VERSION ""

NS_ :

BS_:

BU_: BMU ECU LOGGER

BO_ 2284093440 BMU_TransmitVoltage_N_0_P_0: 8 BMU
 SG_ BMU_M00_V00 : 0|16@1+ (1,0) [0|65535] "mV" LOGGER
 SG_ BMU_M00_V01 : 16|16@1+ (1,0) [0|65535] "mV" LOGGER
 SG_ BMU_M00_V02 : 32|16@1+ (1,0) [0|65535] "mV" LOGGER
 SG_ BMU_M00_VAge0 : 48|16@1+ (1,0) [0|65535] "ms" LOGGER

BO_ 2284093441 BMU_TransmitVoltage_N_0_P_1: 8 BMU
 SG_ BMU_M00_V03 : 0|16@1+ (1,0) [0|65535] "mV" LOGGER
 SG_ BMU_M00_V04 : 16|16@1+ (1,0) [0|65535] "mV" LOGGER
 SG_ BMU_M00_V05 : 32|16@1+ (1,0) [0|65535] "mV" LOGGER
 SG_ BMU_M00_VAge1 : 48|16@1+ (1,0) [0|65535] "ms" LOGGER

BO_ 2284093442 BMU_TransmitVoltage_N_0_P_2: 8 BMU
 SG_ BMU_M00_V06 : 0|16@1+ (1,0) [0|65535] "mV" LOGGER
 SG_ BMU_M00_V07 : 16|16@1+ (1,0) [0|65535] "mV" LOGGER
 SG_ BMU_M00_V08 : 32|16@1+ (1,0) [0|65535] "mV" LOGGER
 SG_ BMU_M00_VAge2 : 48|16@1+ (1,0) [0|65535] "ms" LOGGER

BO_ 2284093443 BMU_TransmitVoltage_N_0_P_3: 8 BMU
 SG_ BMU_M00_V09 : 0|16@1+ (1,0) [0|65535] "mV" LOGGER
 SG_ BMU_M00_V10 : 16|16@1+ (1,0) [0|65535] "mV" LOGGER
 SG_ BMU_M00_V11 : 32|16@1+ (1,0) [0|65535] "mV" LOGGER
 SG_ BMU_M00_VAge3 : 48|16@1+ (1,0) [0|65535] "ms" LOGGER

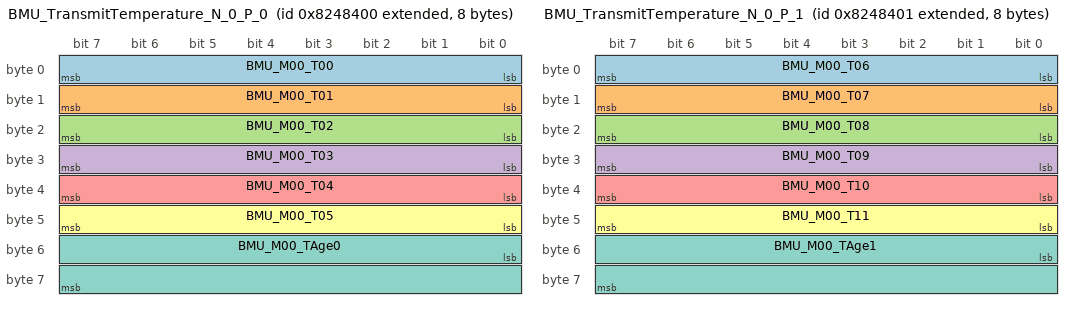
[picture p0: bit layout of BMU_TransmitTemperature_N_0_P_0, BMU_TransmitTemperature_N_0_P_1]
BO_ 2284094464 BMU_TransmitTemperature_N_0_P_0: 8 BMU
 SG_ BMU_M00_T00 : 0|8@1+ (1,0) [0|255] "degC" ECU,LOGGER
 SG_ BMU_M00_T01 : 8|8@1+ (1,0) [0|255] "degC" ECU,LOGGER
 SG_ BMU_M00_T02 : 16|8@1+ (1,0) [0|255] "degC" ECU,LOGGER
 SG_ BMU_M00_T03 : 24|8@1+ (1,0) [0|255] "degC" ECU,LOGGER
 SG_ BMU_M00_T04 : 32|8@1+ (1,0) [0|255] "degC" ECU,LOGGER
 SG_ BMU_M00_T05 : 40|8@1+ (1,0) [0|255] "degC" ECU,LOGGER
 SG_ BMU_M00_TAge0 : 48|16@1+ (1,0) [0|65535] "ms" ECU,LOGGER

BO_ 2284094465 BMU_TransmitTemperature_N_0_P_1: 8 BMU
 SG_ BMU_M00_T06 : 0|8@1+ (1,0) [0|255] "degC" ECU,LOGGER
 SG_ BMU_M00_T07 : 8|8@1+ (1,0) [0|255] "degC" ECU,LOGGER
 SG_ BMU_M00_T08 : 16|8@1+ (1,0) [0|255] "degC" ECU,LOGGER
 SG_ BMU_M00_T09 : 24|8@1+ (1,0) [0|255] "degC" ECU,LOGGER
 SG_ BMU_M00_T10 : 32|8@1+ (1,0) [0|255] "degC" ECU,LOGGER
 SG_ BMU_M00_T11 : 40|8@1+ (1,0) [0|255] "degC" ECU,LOGGER
 SG_ BMU_M00_TAge1 : 48|16@1+ (1,0) [0|65535] "ms" ECU,LOGGER

BO_ 2284095488 BMU_TransmitBalancing_N_0: 8 BMU
 SG_ BMU_M00_Balance : 0|16@1+ (1,0) [0|65535] "" LOGGER
 SG_ BMU_M00_DieTemp : 16|8@1+ (1,0) [0|255] "degC" LOGGER

BO_ 2284093456 BMU_TransmitVoltage_N_1_P_0: 8 BMU
 SG_ BMU_M01_V00 : 0|16@1+ (1,0) [0|65535] "mV" LOGGER
 SG_ BMU_M01_V01 : 16|16@1+ (1,0) [0|65535] "mV" LOGGER
 SG_ BMU_M01_V02 : 32|16@1+ (1,0) [0|65535] "mV" LOGGER
 SG_ BMU_M01_VAge0 : 48|16@1+ (1,0) [0|65535] "ms" LOGGER

BO_ 2284093457 BMU_TransmitVoltage_N_1_P_1: 8 BMU
 SG_ BMU_M01_V03 : 0|16@1+ (1,0) [0|65535] "mV" LOGGER
 SG_ BMU_M01_V04 : 16|16@1+ (1,0) [0|65535] "mV" LOGGER
 SG_ BMU_M01_V05 : 32|16@1+ (1,0) [0|65535] "mV" LOGGER
 SG_ BMU_M01_VAge1 : 48|16@1+ (1,0) [0|65535] "ms" LOGGER

BO_ 2284093458 BMU_TransmitVoltage_N_1_P_2: 8 BMU
 SG_ BMU_M01_V06 : 0|16@1+ (1,0) [0|65535] "mV" LOGGER
 SG_ BMU_M01_V07 : 16|16@1+ (1,0) [0|65535] "mV" LOGGER
 SG_ BMU_M01_V08 : 32|16@1+ (1,0) [0|65535] "mV" LOGGER
 SG_ BMU_M01_VAge2 : 48|16@1+ (1,0) [0|65535] "ms" LOGGER

BO_ 2284093459 BMU_TransmitVoltage_N_1_P_3: 8 BMU
 SG_ BMU_M01_V09 : 0|16@1+ (1,0) [0|65535] "mV" LOGGER
 SG_ BMU_M01_V10 : 16|16@1+ (1,0) [0|65535] "mV" LOGGER
 SG_ BMU_M01_V11 : 32|16@1+ (1,0) [0|65535] "mV" LOGGER
 SG_ BMU_M01_VAge3 : 48|16@1+ (1,0) [0|65535] "ms" LOGGER

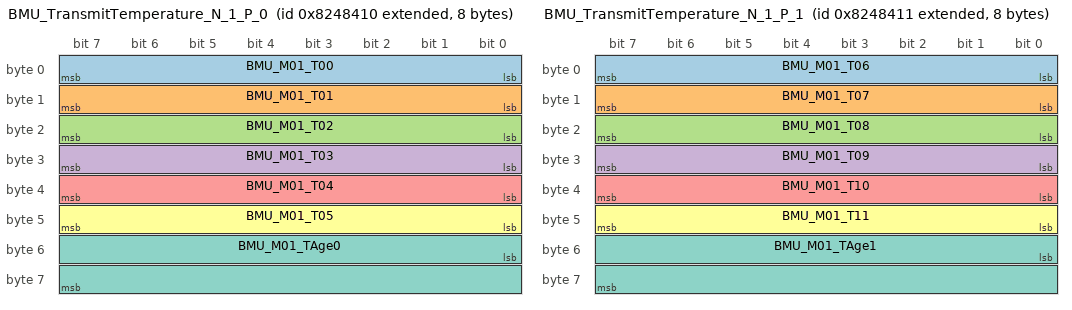
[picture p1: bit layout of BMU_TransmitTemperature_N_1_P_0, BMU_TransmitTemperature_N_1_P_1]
BO_ 2284094480 BMU_TransmitTemperature_N_1_P_0: 8 BMU
 SG_ BMU_M01_T00 : 0|8@1+ (1,0) [0|255] "degC" ECU,LOGGER
 SG_ BMU_M01_T01 : 8|8@1+ (1,0) [0|255] "degC" ECU,LOGGER
 SG_ BMU_M01_T02 : 16|8@1+ (1,0) [0|255] "degC" ECU,LOGGER
 SG_ BMU_M01_T03 : 24|8@1+ (1,0) [0|255] "degC" ECU,LOGGER
 SG_ BMU_M01_T04 : 32|8@1+ (1,0) [0|255] "degC" ECU,LOGGER
 SG_ BMU_M01_T05 : 40|8@1+ (1,0) [0|255] "degC" ECU,LOGGER
 SG_ BMU_M01_TAge0 : 48|16@1+ (1,0) [0|65535] "ms" ECU,LOGGER

BO_ 2284094481 BMU_TransmitTemperature_N_1_P_1: 8 BMU
 SG_ BMU_M01_T06 : 0|8@1+ (1,0) [0|255] "degC" ECU,LOGGER
 SG_ BMU_M01_T07 : 8|8@1+ (1,0) [0|255] "degC" ECU,LOGGER
 SG_ BMU_M01_T08 : 16|8@1+ (1,0) [0|255] "degC" ECU,LOGGER
 SG_ BMU_M01_T09 : 24|8@1+ (1,0) [0|255] "degC" ECU,LOGGER
 SG_ BMU_M01_T10 : 32|8@1+ (1,0) [0|255] "degC" ECU,LOGGER
 SG_ BMU_M01_T11 : 40|8@1+ (1,0) [0|255] "degC" ECU,LOGGER
 SG_ BMU_M01_TAge1 : 48|16@1+ (1,0) [0|65535] "ms" ECU,LOGGER

BO_ 2284095504 BMU_TransmitBalancing_N_1: 8 BMU
 SG_ BMU_M01_Balance : 0|16@1+ (1,0) [0|65535] "" LOGGER
 SG_ BMU_M01_DieTemp : 16|8@1+ (1,0) [0|255] "degC" LOGGER

BO_ 2284093472 BMU_TransmitVoltage_N_2_P_0: 8 BMU
 SG_ BMU_M02_V00 : 0|16@1+ (1,0) [0|65535] "mV" LOGGER
 SG_ BMU_M02_V01 : 16|16@1+ (1,0) [0|65535] "mV" LOGGER
 SG_ BMU_M02_V02 : 32|16@1+ (1,0) [0|65535] "mV" LOGGER
 SG_ BMU_M02_VAge0 : 48|16@1+ (1,0) [0|65535] "ms" LOGGER

BO_ 2284093473 BMU_TransmitVoltage_N_2_P_1: 8 BMU
 SG_ BMU_M02_V03 : 0|16@1+ (1,0) [0|65535] "mV" LOGGER
 SG_ BMU_M02_V04 : 16|16@1+ (1,0) [0|65535] "mV" LOGGER
 SG_ BMU_M02_V05 : 32|16@1+ (1,0) [0|65535] "mV" LOGGER
 SG_ BMU_M02_VAge1 : 48|16@1+ (1,0) [0|65535] "ms" LOGGER

BO_ 2284093474 BMU_TransmitVoltage_N_2_P_2: 8 BMU
 SG_ BMU_M02_V06 : 0|16@1+ (1,0) [0|65535] "mV" LOGGER
 SG_ BMU_M02_V07 : 16|16@1+ (1,0) [0|65535] "mV" LOGGER
 SG_ BMU_M02_V08 : 32|16@1+ (1,0) [0|65535] "mV" LOGGER
 SG_ BMU_M02_VAge2 : 48|16@1+ (1,0) [0|65535] "ms" LOGGER

BO_ 2284093475 BMU_TransmitVoltage_N_2_P_3: 8 BMU
 SG_ BMU_M02_V09 : 0|16@1+ (1,0) [0|65535] "mV" LOGGER
 SG_ BMU_M02_V10 : 16|16@1+ (1,0) [0|65535] "mV" LOGGER
 SG_ BMU_M02_V11 : 32|16@1+ (1,0) [0|65535] "mV" LOGGER
 SG_ BMU_M02_VAge3 : 48|16@1+ (1,0) [0|65535] "ms" LOGGER

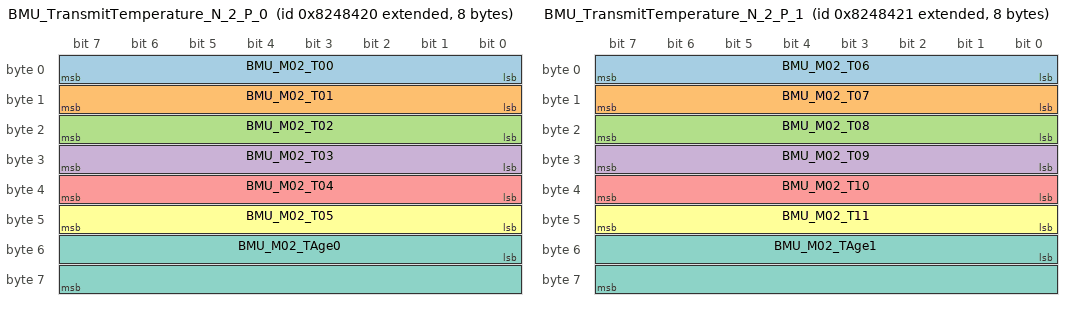
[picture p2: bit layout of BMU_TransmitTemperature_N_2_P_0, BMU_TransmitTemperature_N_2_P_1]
BO_ 2284094496 BMU_TransmitTemperature_N_2_P_0: 8 BMU
 SG_ BMU_M02_T00 : 0|8@1+ (1,0) [0|255] "degC" ECU,LOGGER
 SG_ BMU_M02_T01 : 8|8@1+ (1,0) [0|255] "degC" ECU,LOGGER
 SG_ BMU_M02_T02 : 16|8@1+ (1,0) [0|255] "degC" ECU,LOGGER
 SG_ BMU_M02_T03 : 24|8@1+ (1,0) [0|255] "degC" ECU,LOGGER
 SG_ BMU_M02_T04 : 32|8@1+ (1,0) [0|255] "degC" ECU,LOGGER
 SG_ BMU_M02_T05 : 40|8@1+ (1,0) [0|255] "degC" ECU,LOGGER
 SG_ BMU_M02_TAge0 : 48|16@1+ (1,0) [0|65535] "ms" ECU,LOGGER

BO_ 2284094497 BMU_TransmitTemperature_N_2_P_1: 8 BMU
 SG_ BMU_M02_T06 : 0|8@1+ (1,0) [0|255] "degC" ECU,LOGGER
 SG_ BMU_M02_T07 : 8|8@1+ (1,0) [0|255] "degC" ECU,LOGGER
 SG_ BMU_M02_T08 : 16|8@1+ (1,0) [0|255] "degC" ECU,LOGGER
 SG_ BMU_M02_T09 : 24|8@1+ (1,0) [0|255] "degC" ECU,LOGGER
 SG_ BMU_M02_T10 : 32|8@1+ (1,0) [0|255] "degC" ECU,LOGGER
 SG_ BMU_M02_T11 : 40|8@1+ (1,0) [0|255] "degC" ECU,LOGGER
 SG_ BMU_M02_TAge1 : 48|16@1+ (1,0) [0|65535] "ms" ECU,LOGGER

BO_ 2284095520 BMU_TransmitBalancing_N_2: 8 BMU
 SG_ BMU_M02_Balance : 0|16@1+ (1,0) [0|65535] "" LOGGER
 SG_ BMU_M02_DieTemp : 16|8@1+ (1,0) [0|255] "degC" LOGGER

BO_ 2284093488 BMU_TransmitVoltage_N_3_P_0: 8 BMU
 SG_ BMU_M03_V00 : 0|16@1+ (1,0) [0|65535] "mV" LOGGER
 SG_ BMU_M03_V01 : 16|16@1+ (1,0) [0|65535] "mV" LOGGER
 SG_ BMU_M03_V02 : 32|16@1+ (1,0) [0|65535] "mV" LOGGER
 SG_ BMU_M03_VAge0 : 48|16@1+ (1,0) [0|65535] "ms" LOGGER

BO_ 2284093489 BMU_TransmitVoltage_N_3_P_1: 8 BMU
 SG_ BMU_M03_V03 : 0|16@1+ (1,0) [0|65535] "mV" LOGGER
 SG_ BMU_M03_V04 : 16|16@1+ (1,0) [0|65535] "mV" LOGGER
 SG_ BMU_M03_V05 : 32|16@1+ (1,0) [0|65535] "mV" LOGGER
 SG_ BMU_M03_VAge1 : 48|16@1+ (1,0) [0|65535] "ms" LOGGER

BO_ 2284093490 BMU_TransmitVoltage_N_3_P_2: 8 BMU
 SG_ BMU_M03_V06 : 0|16@1+ (1,0) [0|65535] "mV" LOGGER
 SG_ BMU_M03_V07 : 16|16@1+ (1,0) [0|65535] "mV" LOGGER
 SG_ BMU_M03_V08 : 32|16@1+ (1,0) [0|65535] "mV" LOGGER
 SG_ BMU_M03_VAge2 : 48|16@1+ (1,0) [0|65535] "ms" LOGGER

BO_ 2284093491 BMU_TransmitVoltage_N_3_P_3: 8 BMU
 SG_ BMU_M03_V09 : 0|16@1+ (1,0) [0|65535] "mV" LOGGER
 SG_ BMU_M03_V10 : 16|16@1+ (1,0) [0|65535] "mV" LOGGER
 SG_ BMU_M03_V11 : 32|16@1+ (1,0) [0|65535] "mV" LOGGER
 SG_ BMU_M03_VAge3 : 48|16@1+ (1,0) [0|65535] "ms" LOGGER

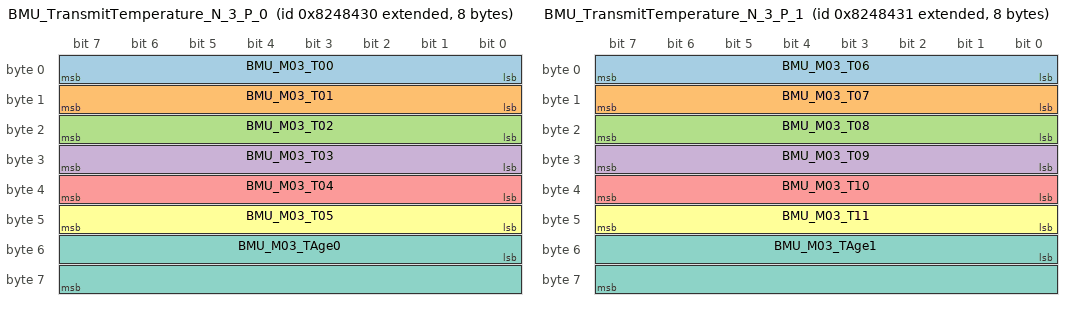
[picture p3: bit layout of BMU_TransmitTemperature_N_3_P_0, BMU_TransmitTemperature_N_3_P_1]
BO_ 2284094512 BMU_TransmitTemperature_N_3_P_0: 8 BMU
 SG_ BMU_M03_T00 : 0|8@1+ (1,0) [0|255] "degC" ECU,LOGGER
 SG_ BMU_M03_T01 : 8|8@1+ (1,0) [0|255] "degC" ECU,LOGGER
 SG_ BMU_M03_T02 : 16|8@1+ (1,0) [0|255] "degC" ECU,LOGGER
 SG_ BMU_M03_T03 : 24|8@1+ (1,0) [0|255] "degC" ECU,LOGGER
 SG_ BMU_M03_T04 : 32|8@1+ (1,0) [0|255] "degC" ECU,LOGGER
 SG_ BMU_M03_T05 : 40|8@1+ (1,0) [0|255] "degC" ECU,LOGGER
 SG_ BMU_M03_TAge0 : 48|16@1+ (1,0) [0|65535] "ms" ECU,LOGGER

BO_ 2284094513 BMU_TransmitTemperature_N_3_P_1: 8 BMU
 SG_ BMU_M03_T06 : 0|8@1+ (1,0) [0|255] "degC" ECU,LOGGER
 SG_ BMU_M03_T07 : 8|8@1+ (1,0) [0|255] "degC" ECU,LOGGER
 SG_ BMU_M03_T08 : 16|8@1+ (1,0) [0|255] "degC" ECU,LOGGER
 SG_ BMU_M03_T09 : 24|8@1+ (1,0) [0|255] "degC" ECU,LOGGER
 SG_ BMU_M03_T10 : 32|8@1+ (1,0) [0|255] "degC" ECU,LOGGER
 SG_ BMU_M03_T11 : 40|8@1+ (1,0) [0|255] "degC" ECU,LOGGER
 SG_ BMU_M03_TAge1 : 48|16@1+ (1,0) [0|65535] "ms" ECU,LOGGER

BO_ 2284095536 BMU_TransmitBalancing_N_3: 8 BMU
 SG_ BMU_M03_Balance : 0|16@1+ (1,0) [0|65535] "" LOGGER
 SG_ BMU_M03_DieTemp : 16|8@1+ (1,0) [0|255] "degC" LOGGER

BO_ 2284093504 BMU_TransmitVoltage_N_4_P_0: 8 BMU
 SG_ BMU_M04_V00 : 0|16@1+ (1,0) [0|65535] "mV" LOGGER
 SG_ BMU_M04_V01 : 16|16@1+ (1,0) [0|65535] "mV" LOGGER
 SG_ BMU_M04_V02 : 32|16@1+ (1,0) [0|65535] "mV" LOGGER
 SG_ BMU_M04_VAge0 : 48|16@1+ (1,0) [0|65535] "ms" LOGGER

BO_ 2284093505 BMU_TransmitVoltage_N_4_P_1: 8 BMU
 SG_ BMU_M04_V03 : 0|16@1+ (1,0) [0|65535] "mV" LOGGER
 SG_ BMU_M04_V04 : 16|16@1+ (1,0) [0|65535] "mV" LOGGER
 SG_ BMU_M04_V05 : 32|16@1+ (1,0) [0|65535] "mV" LOGGER
 SG_ BMU_M04_VAge1 : 48|16@1+ (1,0) [0|65535] "ms" LOGGER

BO_ 2284093506 BMU_TransmitVoltage_N_4_P_2: 8 BMU
 SG_ BMU_M04_V06 : 0|16@1+ (1,0) [0|65535] "mV" LOGGER
 SG_ BMU_M04_V07 : 16|16@1+ (1,0) [0|65535] "mV" LOGGER
 SG_ BMU_M04_V08 : 32|16@1+ (1,0) [0|65535] "mV" LOGGER
 SG_ BMU_M04_VAge2 : 48|16@1+ (1,0) [0|65535] "ms" LOGGER

BO_ 2284093507 BMU_TransmitVoltage_N_4_P_3: 8 BMU
 SG_ BMU_M04_V09 : 0|16@1+ (1,0) [0|65535] "mV" LOGGER
 SG_ BMU_M04_V10 : 16|16@1+ (1,0) [0|65535] "mV" LOGGER
 SG_ BMU_M04_V11 : 32|16@1+ (1,0) [0|65535] "mV" LOGGER
 SG_ BMU_M04_VAge3 : 48|16@1+ (1,0) [0|65535] "ms" LOGGER

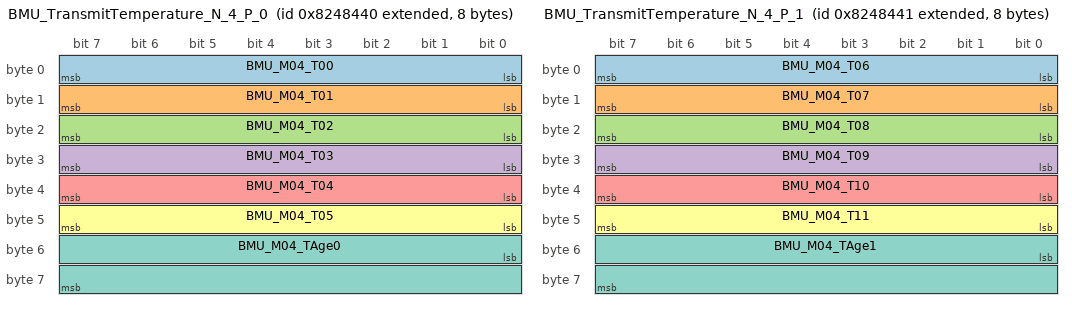
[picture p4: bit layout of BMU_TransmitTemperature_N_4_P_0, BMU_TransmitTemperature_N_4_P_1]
BO_ 2284094528 BMU_TransmitTemperature_N_4_P_0: 8 BMU
 SG_ BMU_M04_T00 : 0|8@1+ (1,0) [0|255] "degC" ECU,LOGGER
 SG_ BMU_M04_T01 : 8|8@1+ (1,0) [0|255] "degC" ECU,LOGGER
 SG_ BMU_M04_T02 : 16|8@1+ (1,0) [0|255] "degC" ECU,LOGGER
 SG_ BMU_M04_T03 : 24|8@1+ (1,0) [0|255] "degC" ECU,LOGGER
 SG_ BMU_M04_T04 : 32|8@1+ (1,0) [0|255] "degC" ECU,LOGGER
 SG_ BMU_M04_T05 : 40|8@1+ (1,0) [0|255] "degC" ECU,LOGGER
 SG_ BMU_M04_TAge0 : 48|16@1+ (1,0) [0|65535] "ms" ECU,LOGGER

BO_ 2284094529 BMU_TransmitTemperature_N_4_P_1: 8 BMU
 SG_ BMU_M04_T06 : 0|8@1+ (1,0) [0|255] "degC" ECU,LOGGER
 SG_ BMU_M04_T07 : 8|8@1+ (1,0) [0|255] "degC" ECU,LOGGER
 SG_ BMU_M04_T08 : 16|8@1+ (1,0) [0|255] "degC" ECU,LOGGER
 SG_ BMU_M04_T09 : 24|8@1+ (1,0) [0|255] "degC" ECU,LOGGER
 SG_ BMU_M04_T10 : 32|8@1+ (1,0) [0|255] "degC" ECU,LOGGER
 SG_ BMU_M04_T11 : 40|8@1+ (1,0) [0|255] "degC" ECU,LOGGER
 SG_ BMU_M04_TAge1 : 48|16@1+ (1,0) [0|65535] "ms" ECU,LOGGER

BO_ 2284095552 BMU_TransmitBalancing_N_4: 8 BMU
 SG_ BMU_M04_Balance : 0|16@1+ (1,0) [0|65535] "" LOGGER
 SG_ BMU_M04_DieTemp : 16|8@1+ (1,0) [0|255] "degC" LOGGER

BO_ 2284093520 BMU_TransmitVoltage_N_5_P_0: 8 BMU
 SG_ BMU_M05_V00 : 0|16@1+ (1,0) [0|65535] "mV" LOGGER
 SG_ BMU_M05_V01 : 16|16@1+ (1,0) [0|65535] "mV" LOGGER
 SG_ BMU_M05_V02 : 32|16@1+ (1,0) [0|65535] "mV" LOGGER
 SG_ BMU_M05_VAge0 : 48|16@1+ (1,0) [0|65535] "ms" LOGGER

BO_ 2284093521 BMU_TransmitVoltage_N_5_P_1: 8 BMU
 SG_ BMU_M05_V03 : 0|16@1+ (1,0) [0|65535] "mV" LOGGER
 SG_ BMU_M05_V04 : 16|16@1+ (1,0) [0|65535] "mV" LOGGER
 SG_ BMU_M05_V05 : 32|16@1+ (1,0) [0|65535] "mV" LOGGER
 SG_ BMU_M05_VAge1 : 48|16@1+ (1,0) [0|65535] "ms" LOGGER

BO_ 2284093522 BMU_TransmitVoltage_N_5_P_2: 8 BMU
 SG_ BMU_M05_V06 : 0|16@1+ (1,0) [0|65535] "mV" LOGGER
 SG_ BMU_M05_V07 : 16|16@1+ (1,0) [0|65535] "mV" LOGGER
 SG_ BMU_M05_V08 : 32|16@1+ (1,0) [0|65535] "mV" LOGGER
 SG_ BMU_M05_VAge2 : 48|16@1+ (1,0) [0|65535] "ms" LOGGER

BO_ 2284093523 BMU_TransmitVoltage_N_5_P_3: 8 BMU
 SG_ BMU_M05_V09 : 0|16@1+ (1,0) [0|65535] "mV" LOGGER
 SG_ BMU_M05_V10 : 16|16@1+ (1,0) [0|65535] "mV" LOGGER
 SG_ BMU_M05_V11 : 32|16@1+ (1,0) [0|65535] "mV" LOGGER
 SG_ BMU_M05_VAge3 : 48|16@1+ (1,0) [0|65535] "ms" LOGGER

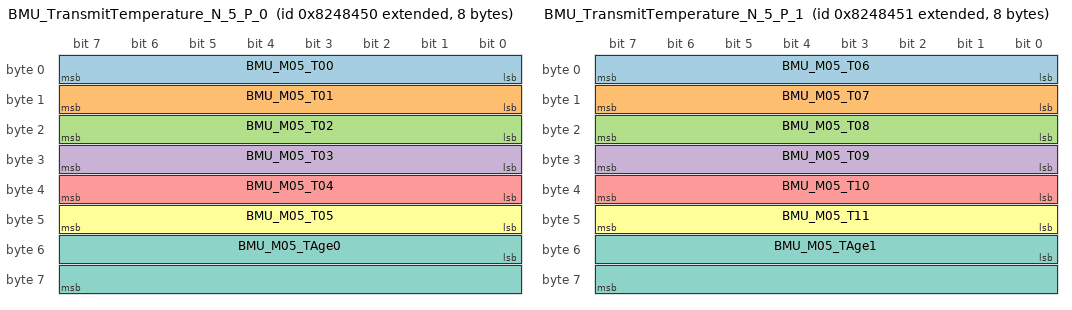
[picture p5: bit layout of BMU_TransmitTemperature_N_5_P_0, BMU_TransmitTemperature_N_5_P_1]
BO_ 2284094544 BMU_TransmitTemperature_N_5_P_0: 8 BMU
 SG_ BMU_M05_T00 : 0|8@1+ (1,0) [0|255] "degC" ECU,LOGGER
 SG_ BMU_M05_T01 : 8|8@1+ (1,0) [0|255] "degC" ECU,LOGGER
 SG_ BMU_M05_T02 : 16|8@1+ (1,0) [0|255] "degC" ECU,LOGGER
 SG_ BMU_M05_T03 : 24|8@1+ (1,0) [0|255] "degC" ECU,LOGGER
 SG_ BMU_M05_T04 : 32|8@1+ (1,0) [0|255] "degC" ECU,LOGGER
 SG_ BMU_M05_T05 : 40|8@1+ (1,0) [0|255] "degC" ECU,LOGGER
 SG_ BMU_M05_TAge0 : 48|16@1+ (1,0) [0|65535] "ms" ECU,LOGGER

BO_ 2284094545 BMU_TransmitTemperature_N_5_P_1: 8 BMU
 SG_ BMU_M05_T06 : 0|8@1+ (1,0) [0|255] "degC" ECU,LOGGER
 SG_ BMU_M05_T07 : 8|8@1+ (1,0) [0|255] "degC" ECU,LOGGER
 SG_ BMU_M05_T08 : 16|8@1+ (1,0) [0|255] "degC" ECU,LOGGER
 SG_ BMU_M05_T09 : 24|8@1+ (1,0) [0|255] "degC" ECU,LOGGER
 SG_ BMU_M05_T10 : 32|8@1+ (1,0) [0|255] "degC" ECU,LOGGER
 SG_ BMU_M05_T11 : 40|8@1+ (1,0) [0|255] "degC" ECU,LOGGER
 SG_ BMU_M05_TAge1 : 48|16@1+ (1,0) [0|65535] "ms" ECU,LOGGER

BO_ 2284095568 BMU_TransmitBalancing_N_5: 8 BMU
 SG_ BMU_M05_Balance : 0|16@1+ (1,0) [0|65535] "" LOGGER
 SG_ BMU_M05_DieTemp : 16|8@1+ (1,0) [0|255] "degC" LOGGER

BO_ 2284093536 BMU_TransmitVoltage_N_6_P_0: 8 BMU
 SG_ BMU_M06_V00 : 0|16@1+ (1,0) [0|65535] "mV" LOGGER
 SG_ BMU_M06_V01 : 16|16@1+ (1,0) [0|65535] "mV" LOGGER
 SG_ BMU_M06_V02 : 32|16@1+ (1,0) [0|65535] "mV" LOGGER
 SG_ BMU_M06_VAge0 : 48|16@1+ (1,0) [0|65535] "ms" LOGGER

BO_ 2284093537 BMU_TransmitVoltage_N_6_P_1: 8 BMU
 SG_ BMU_M06_V03 : 0|16@1+ (1,0) [0|65535] "mV" LOGGER
 SG_ BMU_M06_V04 : 16|16@1+ (1,0) [0|65535] "mV" LOGGER
 SG_ BMU_M06_V05 : 32|16@1+ (1,0) [0|65535] "mV" LOGGER
 SG_ BMU_M06_VAge1 : 48|16@1+ (1,0) [0|65535] "ms" LOGGER

BO_ 2284093538 BMU_TransmitVoltage_N_6_P_2: 8 BMU
 SG_ BMU_M06_V06 : 0|16@1+ (1,0) [0|65535] "mV" LOGGER
 SG_ BMU_M06_V07 : 16|16@1+ (1,0) [0|65535] "mV" LOGGER
 SG_ BMU_M06_V08 : 32|16@1+ (1,0) [0|65535] "mV" LOGGER
 SG_ BMU_M06_VAge2 : 48|16@1+ (1,0) [0|65535] "ms" LOGGER

BO_ 2284093539 BMU_TransmitVoltage_N_6_P_3: 8 BMU
 SG_ BMU_M06_V09 : 0|16@1+ (1,0) [0|65535] "mV" LOGGER
 SG_ BMU_M06_V10 : 16|16@1+ (1,0) [0|65535] "mV" LOGGER
 SG_ BMU_M06_V11 : 32|16@1+ (1,0) [0|65535] "mV" LOGGER
 SG_ BMU_M06_VAge3 : 48|16@1+ (1,0) [0|65535] "ms" LOGGER

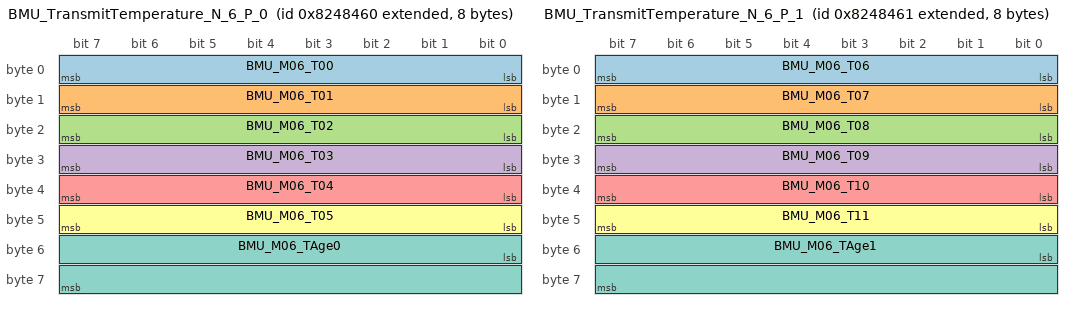
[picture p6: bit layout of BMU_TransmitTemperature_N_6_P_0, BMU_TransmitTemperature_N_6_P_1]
BO_ 2284094560 BMU_TransmitTemperature_N_6_P_0: 8 BMU
 SG_ BMU_M06_T00 : 0|8@1+ (1,0) [0|255] "degC" ECU,LOGGER
 SG_ BMU_M06_T01 : 8|8@1+ (1,0) [0|255] "degC" ECU,LOGGER
 SG_ BMU_M06_T02 : 16|8@1+ (1,0) [0|255] "degC" ECU,LOGGER
 SG_ BMU_M06_T03 : 24|8@1+ (1,0) [0|255] "degC" ECU,LOGGER
 SG_ BMU_M06_T04 : 32|8@1+ (1,0) [0|255] "degC" ECU,LOGGER
 SG_ BMU_M06_T05 : 40|8@1+ (1,0) [0|255] "degC" ECU,LOGGER
 SG_ BMU_M06_TAge0 : 48|16@1+ (1,0) [0|65535] "ms" ECU,LOGGER

BO_ 2284094561 BMU_TransmitTemperature_N_6_P_1: 8 BMU
 SG_ BMU_M06_T06 : 0|8@1+ (1,0) [0|255] "degC" ECU,LOGGER
 SG_ BMU_M06_T07 : 8|8@1+ (1,0) [0|255] "degC" ECU,LOGGER
 SG_ BMU_M06_T08 : 16|8@1+ (1,0) [0|255] "degC" ECU,LOGGER
 SG_ BMU_M06_T09 : 24|8@1+ (1,0) [0|255] "degC" ECU,LOGGER
 SG_ BMU_M06_T10 : 32|8@1+ (1,0) [0|255] "degC" ECU,LOGGER
 SG_ BMU_M06_T11 : 40|8@1+ (1,0) [0|255] "degC" ECU,LOGGER
 SG_ BMU_M06_TAge1 : 48|16@1+ (1,0) [0|65535] "ms" ECU,LOGGER

BO_ 2284095584 BMU_TransmitBalancing_N_6: 8 BMU
 SG_ BMU_M06_Balance : 0|16@1+ (1,0) [0|65535] "" LOGGER
 SG_ BMU_M06_DieTemp : 16|8@1+ (1,0) [0|255] "degC" LOGGER

BO_ 2284093552 BMU_TransmitVoltage_N_7_P_0: 8 BMU
 SG_ BMU_M07_V00 : 0|16@1+ (1,0) [0|65535] "mV" LOGGER
 SG_ BMU_M07_V01 : 16|16@1+ (1,0) [0|65535] "mV" LOGGER
 SG_ BMU_M07_V02 : 32|16@1+ (1,0) [0|65535] "mV" LOGGER
 SG_ BMU_M07_VAge0 : 48|16@1+ (1,0) [0|65535] "ms" LOGGER

BO_ 2284093553 BMU_TransmitVoltage_N_7_P_1: 8 BMU
 SG_ BMU_M07_V03 : 0|16@1+ (1,0) [0|65535] "mV" LOGGER
 SG_ BMU_M07_V04 : 16|16@1+ (1,0) [0|65535] "mV" LOGGER
 SG_ BMU_M07_V05 : 32|16@1+ (1,0) [0|65535] "mV" LOGGER
 SG_ BMU_M07_VAge1 : 48|16@1+ (1,0) [0|65535] "ms" LOGGER

BO_ 2284093554 BMU_TransmitVoltage_N_7_P_2: 8 BMU
 SG_ BMU_M07_V06 : 0|16@1+ (1,0) [0|65535] "mV" LOGGER
 SG_ BMU_M07_V07 : 16|16@1+ (1,0) [0|65535] "mV" LOGGER
 SG_ BMU_M07_V08 : 32|16@1+ (1,0) [0|65535] "mV" LOGGER
 SG_ BMU_M07_VAge2 : 48|16@1+ (1,0) [0|65535] "ms" LOGGER

BO_ 2284093555 BMU_TransmitVoltage_N_7_P_3: 8 BMU
 SG_ BMU_M07_V09 : 0|16@1+ (1,0) [0|65535] "mV" LOGGER
 SG_ BMU_M07_V10 : 16|16@1+ (1,0) [0|65535] "mV" LOGGER
 SG_ BMU_M07_V11 : 32|16@1+ (1,0) [0|65535] "mV" LOGGER
 SG_ BMU_M07_VAge3 : 48|16@1+ (1,0) [0|65535] "ms" LOGGER

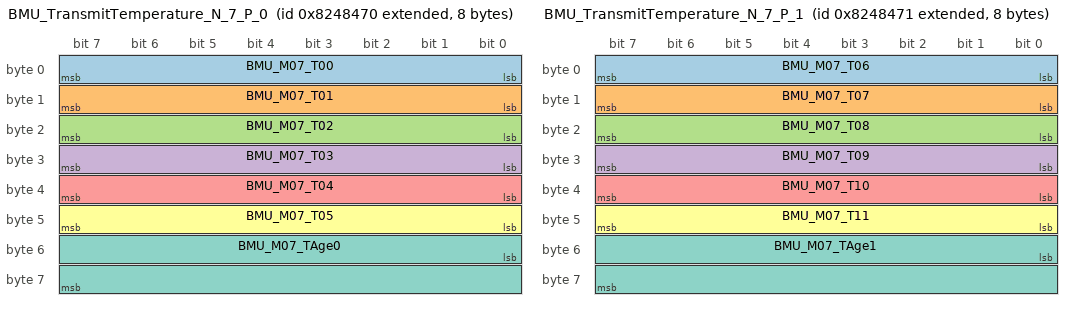
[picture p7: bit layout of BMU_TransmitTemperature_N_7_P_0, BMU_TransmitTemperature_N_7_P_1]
BO_ 2284094576 BMU_TransmitTemperature_N_7_P_0: 8 BMU
 SG_ BMU_M07_T00 : 0|8@1+ (1,0) [0|255] "degC" ECU,LOGGER
 SG_ BMU_M07_T01 : 8|8@1+ (1,0) [0|255] "degC" ECU,LOGGER
 SG_ BMU_M07_T02 : 16|8@1+ (1,0) [0|255] "degC" ECU,LOGGER
 SG_ BMU_M07_T03 : 24|8@1+ (1,0) [0|255] "degC" ECU,LOGGER
 SG_ BMU_M07_T04 : 32|8@1+ (1,0) [0|255] "degC" ECU,LOGGER
 SG_ BMU_M07_T05 : 40|8@1+ (1,0) [0|255] "degC" ECU,LOGGER
 SG_ BMU_M07_TAge0 : 48|16@1+ (1,0) [0|65535] "ms" ECU,LOGGER

BO_ 2284094577 BMU_TransmitTemperature_N_7_P_1: 8 BMU
 SG_ BMU_M07_T06 : 0|8@1+ (1,0) [0|255] "degC" ECU,LOGGER
 SG_ BMU_M07_T07 : 8|8@1+ (1,0) [0|255] "degC" ECU,LOGGER
 SG_ BMU_M07_T08 : 16|8@1+ (1,0) [0|255] "degC" ECU,LOGGER
 SG_ BMU_M07_T09 : 24|8@1+ (1,0) [0|255] "degC" ECU,LOGGER
 SG_ BMU_M07_T10 : 32|8@1+ (1,0) [0|255] "degC" ECU,LOGGER
 SG_ BMU_M07_T11 : 40|8@1+ (1,0) [0|255] "degC" ECU,LOGGER
 SG_ BMU_M07_TAge1 : 48|16@1+ (1,0) [0|65535] "ms" ECU,LOGGER

BO_ 2284095600 BMU_TransmitBalancing_N_7: 8 BMU
 SG_ BMU_M07_Balance : 0|16@1+ (1,0) [0|65535] "" LOGGER
 SG_ BMU_M07_DieTemp : 16|8@1+ (1,0) [0|255] "degC" LOGGER

BO_ 2284093568 BMU_TransmitVoltage_N_8_P_0: 8 BMU
 SG_ BMU_M08_V00 : 0|16@1+ (1,0) [0|65535] "mV" LOGGER
 SG_ BMU_M08_V01 : 16|16@1+ (1,0) [0|65535] "mV" LOGGER
 SG_ BMU_M08_V02 : 32|16@1+ (1,0) [0|65535] "mV" LOGGER
 SG_ BMU_M08_VAge0 : 48|16@1+ (1,0) [0|65535] "ms" LOGGER

BO_ 2284093569 BMU_TransmitVoltage_N_8_P_1: 8 BMU
 SG_ BMU_M08_V03 : 0|16@1+ (1,0) [0|65535] "mV" LOGGER
 SG_ BMU_M08_V04 : 16|16@1+ (1,0) [0|65535] "mV" LOGGER
 SG_ BMU_M08_V05 : 32|16@1+ (1,0) [0|65535] "mV" LOGGER
 SG_ BMU_M08_VAge1 : 48|16@1+ (1,0) [0|65535] "ms" LOGGER

BO_ 2284093570 BMU_TransmitVoltage_N_8_P_2: 8 BMU
 SG_ BMU_M08_V06 : 0|16@1+ (1,0) [0|65535] "mV" LOGGER
 SG_ BMU_M08_V07 : 16|16@1+ (1,0) [0|65535] "mV" LOGGER
 SG_ BMU_M08_V08 : 32|16@1+ (1,0) [0|65535] "mV" LOGGER
 SG_ BMU_M08_VAge2 : 48|16@1+ (1,0) [0|65535] "ms" LOGGER

BO_ 2284093571 BMU_TransmitVoltage_N_8_P_3: 8 BMU
 SG_ BMU_M08_V09 : 0|16@1+ (1,0) [0|65535] "mV" LOGGER
 SG_ BMU_M08_V10 : 16|16@1+ (1,0) [0|65535] "mV" LOGGER
 SG_ BMU_M08_V11 : 32|16@1+ (1,0) [0|65535] "mV" LOGGER
 SG_ BMU_M08_VAge3 : 48|16@1+ (1,0) [0|65535] "ms" LOGGER

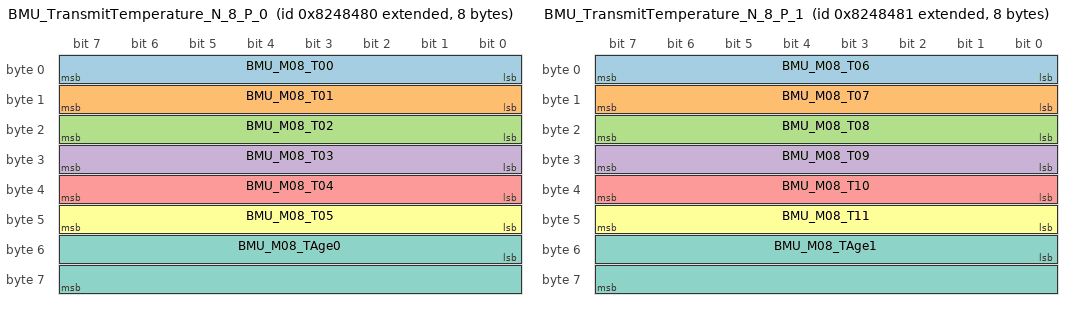
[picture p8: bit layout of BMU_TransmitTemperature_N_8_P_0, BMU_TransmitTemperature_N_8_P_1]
BO_ 2284094592 BMU_TransmitTemperature_N_8_P_0: 8 BMU
 SG_ BMU_M08_T00 : 0|8@1+ (1,0) [0|255] "degC" ECU,LOGGER
 SG_ BMU_M08_T01 : 8|8@1+ (1,0) [0|255] "degC" ECU,LOGGER
 SG_ BMU_M08_T02 : 16|8@1+ (1,0) [0|255] "degC" ECU,LOGGER
 SG_ BMU_M08_T03 : 24|8@1+ (1,0) [0|255] "degC" ECU,LOGGER
 SG_ BMU_M08_T04 : 32|8@1+ (1,0) [0|255] "degC" ECU,LOGGER
 SG_ BMU_M08_T05 : 40|8@1+ (1,0) [0|255] "degC" ECU,LOGGER
 SG_ BMU_M08_TAge0 : 48|16@1+ (1,0) [0|65535] "ms" ECU,LOGGER

BO_ 2284094593 BMU_TransmitTemperature_N_8_P_1: 8 BMU
 SG_ BMU_M08_T06 : 0|8@1+ (1,0) [0|255] "degC" ECU,LOGGER
 SG_ BMU_M08_T07 : 8|8@1+ (1,0) [0|255] "degC" ECU,LOGGER
 SG_ BMU_M08_T08 : 16|8@1+ (1,0) [0|255] "degC" ECU,LOGGER
 SG_ BMU_M08_T09 : 24|8@1+ (1,0) [0|255] "degC" ECU,LOGGER
 SG_ BMU_M08_T10 : 32|8@1+ (1,0) [0|255] "degC" ECU,LOGGER
 SG_ BMU_M08_T11 : 40|8@1+ (1,0) [0|255] "degC" ECU,LOGGER
 SG_ BMU_M08_TAge1 : 48|16@1+ (1,0) [0|65535] "ms" ECU,LOGGER

BO_ 2284095616 BMU_TransmitBalancing_N_8: 8 BMU
 SG_ BMU_M08_Balance : 0|16@1+ (1,0) [0|65535] "" LOGGER
 SG_ BMU_M08_DieTemp : 16|8@1+ (1,0) [0|255] "degC" LOGGER

BO_ 2284093584 BMU_TransmitVoltage_N_9_P_0: 8 BMU
 SG_ BMU_M09_V00 : 0|16@1+ (1,0) [0|65535] "mV" LOGGER
 SG_ BMU_M09_V01 : 16|16@1+ (1,0) [0|65535] "mV" LOGGER
 SG_ BMU_M09_V02 : 32|16@1+ (1,0) [0|65535] "mV" LOGGER
 SG_ BMU_M09_VAge0 : 48|16@1+ (1,0) [0|65535] "ms" LOGGER

BO_ 2284093585 BMU_TransmitVoltage_N_9_P_1: 8 BMU
 SG_ BMU_M09_V03 : 0|16@1+ (1,0) [0|65535] "mV" LOGGER
 SG_ BMU_M09_V04 : 16|16@1+ (1,0) [0|65535] "mV" LOGGER
 SG_ BMU_M09_V05 : 32|16@1+ (1,0) [0|65535] "mV" LOGGER
 SG_ BMU_M09_VAge1 : 48|16@1+ (1,0) [0|65535] "ms" LOGGER

BO_ 2284093586 BMU_TransmitVoltage_N_9_P_2: 8 BMU
 SG_ BMU_M09_V06 : 0|16@1+ (1,0) [0|65535] "mV" LOGGER
 SG_ BMU_M09_V07 : 16|16@1+ (1,0) [0|65535] "mV" LOGGER
 SG_ BMU_M09_V08 : 32|16@1+ (1,0) [0|65535] "mV" LOGGER
 SG_ BMU_M09_VAge2 : 48|16@1+ (1,0) [0|65535] "ms" LOGGER

BO_ 2284093587 BMU_TransmitVoltage_N_9_P_3: 8 BMU
 SG_ BMU_M09_V09 : 0|16@1+ (1,0) [0|65535] "mV" LOGGER
 SG_ BMU_M09_V10 : 16|16@1+ (1,0) [0|65535] "mV" LOGGER
 SG_ BMU_M09_V11 : 32|16@1+ (1,0) [0|65535] "mV" LOGGER
 SG_ BMU_M09_VAge3 : 48|16@1+ (1,0) [0|65535] "ms" LOGGER

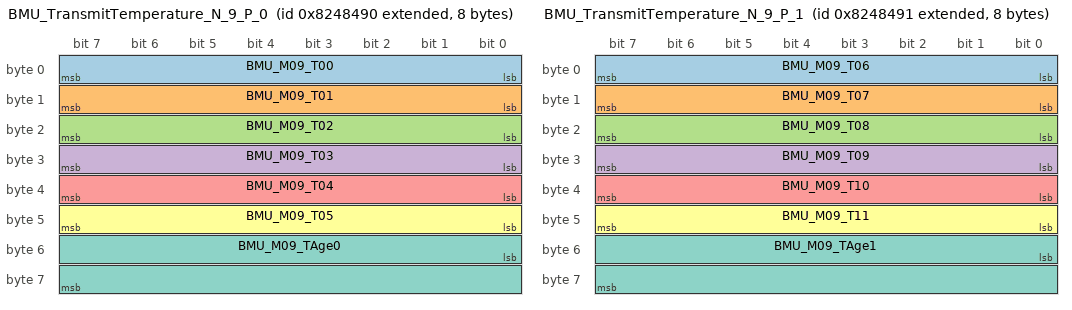
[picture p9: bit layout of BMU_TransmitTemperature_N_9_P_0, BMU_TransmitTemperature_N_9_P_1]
BO_ 2284094608 BMU_TransmitTemperature_N_9_P_0: 8 BMU
 SG_ BMU_M09_T00 : 0|8@1+ (1,0) [0|255] "degC" ECU,LOGGER
 SG_ BMU_M09_T01 : 8|8@1+ (1,0) [0|255] "degC" ECU,LOGGER
 SG_ BMU_M09_T02 : 16|8@1+ (1,0) [0|255] "degC" ECU,LOGGER
 SG_ BMU_M09_T03 : 24|8@1+ (1,0) [0|255] "degC" ECU,LOGGER
 SG_ BMU_M09_T04 : 32|8@1+ (1,0) [0|255] "degC" ECU,LOGGER
 SG_ BMU_M09_T05 : 40|8@1+ (1,0) [0|255] "degC" ECU,LOGGER
 SG_ BMU_M09_TAge0 : 48|16@1+ (1,0) [0|65535] "ms" ECU,LOGGER

BO_ 2284094609 BMU_TransmitTemperature_N_9_P_1: 8 BMU
 SG_ BMU_M09_T06 : 0|8@1+ (1,0) [0|255] "degC" ECU,LOGGER
 SG_ BMU_M09_T07 : 8|8@1+ (1,0) [0|255] "degC" ECU,LOGGER
 SG_ BMU_M09_T08 : 16|8@1+ (1,0) [0|255] "degC" ECU,LOGGER
 SG_ BMU_M09_T09 : 24|8@1+ (1,0) [0|255] "degC" ECU,LOGGER
 SG_ BMU_M09_T10 : 32|8@1+ (1,0) [0|255] "degC" ECU,LOGGER
 SG_ BMU_M09_T11 : 40|8@1+ (1,0) [0|255] "degC" ECU,LOGGER
 SG_ BMU_M09_TAge1 : 48|16@1+ (1,0) [0|65535] "ms" ECU,LOGGER

BO_ 2284095632 BMU_TransmitBalancing_N_9: 8 BMU
 SG_ BMU_M09_Balance : 0|16@1+ (1,0) [0|65535] "" LOGGER
 SG_ BMU_M09_DieTemp : 16|8@1+ (1,0) [0|255] "degC" LOGGER

BO_ 2284093600 BMU_TransmitVoltage_N_10_P_0: 8 BMU
 SG_ BMU_M10_V00 : 0|16@1+ (1,0) [0|65535] "mV" LOGGER
 SG_ BMU_M10_V01 : 16|16@1+ (1,0) [0|65535] "mV" LOGGER
 SG_ BMU_M10_V02 : 32|16@1+ (1,0) [0|65535] "mV" LOGGER
 SG_ BMU_M10_VAge0 : 48|16@1+ (1,0) [0|65535] "ms" LOGGER

BO_ 2284093601 BMU_TransmitVoltage_N_10_P_1: 8 BMU
 SG_ BMU_M10_V03 : 0|16@1+ (1,0) [0|65535] "mV" LOGGER
 SG_ BMU_M10_V04 : 16|16@1+ (1,0) [0|65535] "mV" LOGGER
 SG_ BMU_M10_V05 : 32|16@1+ (1,0) [0|65535] "mV" LOGGER
 SG_ BMU_M10_VAge1 : 48|16@1+ (1,0) [0|65535] "ms" LOGGER

BO_ 2284093602 BMU_TransmitVoltage_N_10_P_2: 8 BMU
 SG_ BMU_M10_V06 : 0|16@1+ (1,0) [0|65535] "mV" LOGGER
 SG_ BMU_M10_V07 : 16|16@1+ (1,0) [0|65535] "mV" LOGGER
 SG_ BMU_M10_V08 : 32|16@1+ (1,0) [0|65535] "mV" LOGGER
 SG_ BMU_M10_VAge2 : 48|16@1+ (1,0) [0|65535] "ms" LOGGER

BO_ 2284093603 BMU_TransmitVoltage_N_10_P_3: 8 BMU
 SG_ BMU_M10_V09 : 0|16@1+ (1,0) [0|65535] "mV" LOGGER
 SG_ BMU_M10_V10 : 16|16@1+ (1,0) [0|65535] "mV" LOGGER
 SG_ BMU_M10_V11 : 32|16@1+ (1,0) [0|65535] "mV" LOGGER
 SG_ BMU_M10_VAge3 : 48|16@1+ (1,0) [0|65535] "ms" LOGGER

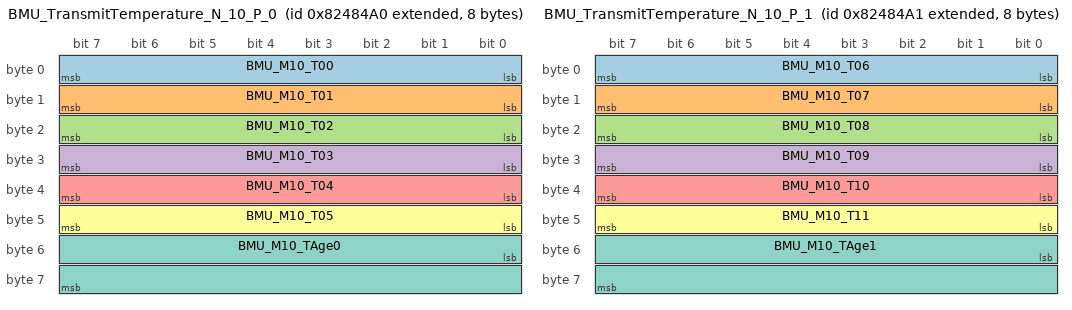
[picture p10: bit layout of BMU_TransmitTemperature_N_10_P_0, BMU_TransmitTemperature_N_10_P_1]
BO_ 2284094624 BMU_TransmitTemperature_N_10_P_0: 8 BMU
 SG_ BMU_M10_T00 : 0|8@1+ (1,0) [0|255] "degC" ECU,LOGGER
 SG_ BMU_M10_T01 : 8|8@1+ (1,0) [0|255] "degC" ECU,LOGGER
 SG_ BMU_M10_T02 : 16|8@1+ (1,0) [0|255] "degC" ECU,LOGGER
 SG_ BMU_M10_T03 : 24|8@1+ (1,0) [0|255] "degC" ECU,LOGGER
 SG_ BMU_M10_T04 : 32|8@1+ (1,0) [0|255] "degC" ECU,LOGGER
 SG_ BMU_M10_T05 : 40|8@1+ (1,0) [0|255] "degC" ECU,LOGGER
 SG_ BMU_M10_TAge0 : 48|16@1+ (1,0) [0|65535] "ms" ECU,LOGGER

BO_ 2284094625 BMU_TransmitTemperature_N_10_P_1: 8 BMU
 SG_ BMU_M10_T06 : 0|8@1+ (1,0) [0|255] "degC" ECU,LOGGER
 SG_ BMU_M10_T07 : 8|8@1+ (1,0) [0|255] "degC" ECU,LOGGER
 SG_ BMU_M10_T08 : 16|8@1+ (1,0) [0|255] "degC" ECU,LOGGER
 SG_ BMU_M10_T09 : 24|8@1+ (1,0) [0|255] "degC" ECU,LOGGER
 SG_ BMU_M10_T10 : 32|8@1+ (1,0) [0|255] "degC" ECU,LOGGER
 SG_ BMU_M10_T11 : 40|8@1+ (1,0) [0|255] "degC" ECU,LOGGER
 SG_ BMU_M10_TAge1 : 48|16@1+ (1,0) [0|65535] "ms" ECU,LOGGER

BO_ 2284095648 BMU_TransmitBalancing_N_10: 8 BMU
 SG_ BMU_M10_Balance : 0|16@1+ (1,0) [0|65535] "" LOGGER
 SG_ BMU_M10_DieTemp : 16|8@1+ (1,0) [0|255] "degC" LOGGER

BO_ 2284093616 BMU_TransmitVoltage_N_11_P_0: 8 BMU
 SG_ BMU_M11_V00 : 0|16@1+ (1,0) [0|65535] "mV" LOGGER
 SG_ BMU_M11_V01 : 16|16@1+ (1,0) [0|65535] "mV" LOGGER
 SG_ BMU_M11_V02 : 32|16@1+ (1,0) [0|65535] "mV" LOGGER
 SG_ BMU_M11_VAge0 : 48|16@1+ (1,0) [0|65535] "ms" LOGGER

BO_ 2284093617 BMU_TransmitVoltage_N_11_P_1: 8 BMU
 SG_ BMU_M11_V03 : 0|16@1+ (1,0) [0|65535] "mV" LOGGER
 SG_ BMU_M11_V04 : 16|16@1+ (1,0) [0|65535] "mV" LOGGER
 SG_ BMU_M11_V05 : 32|16@1+ (1,0) [0|65535] "mV" LOGGER
 SG_ BMU_M11_VAge1 : 48|16@1+ (1,0) [0|65535] "ms" LOGGER

BO_ 2284093618 BMU_TransmitVoltage_N_11_P_2: 8 BMU
 SG_ BMU_M11_V06 : 0|16@1+ (1,0) [0|65535] "mV" LOGGER
 SG_ BMU_M11_V07 : 16|16@1+ (1,0) [0|65535] "mV" LOGGER
 SG_ BMU_M11_V08 : 32|16@1+ (1,0) [0|65535] "mV" LOGGER
 SG_ BMU_M11_VAge2 : 48|16@1+ (1,0) [0|65535] "ms" LOGGER

BO_ 2284093619 BMU_TransmitVoltage_N_11_P_3: 8 BMU
 SG_ BMU_M11_V09 : 0|16@1+ (1,0) [0|65535] "mV" LOGGER
 SG_ BMU_M11_V10 : 16|16@1+ (1,0) [0|65535] "mV" LOGGER
 SG_ BMU_M11_V11 : 32|16@1+ (1,0) [0|65535] "mV" LOGGER
 SG_ BMU_M11_VAge3 : 48|16@1+ (1,0) [0|65535] "ms" LOGGER

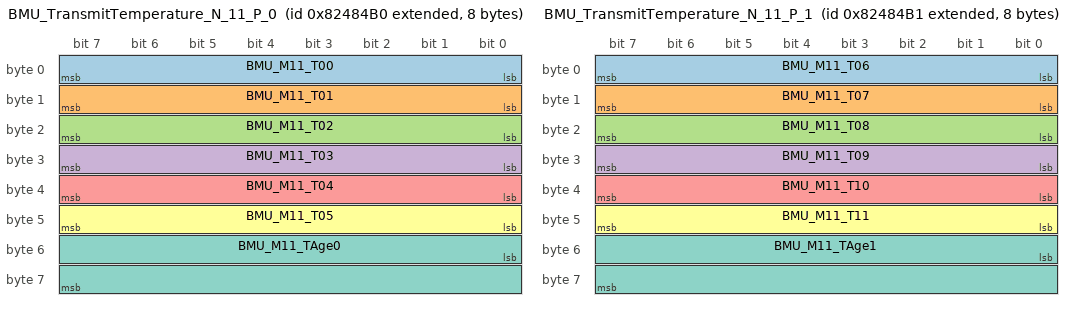
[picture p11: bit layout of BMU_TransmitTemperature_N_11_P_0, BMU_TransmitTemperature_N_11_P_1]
BO_ 2284094640 BMU_TransmitTemperature_N_11_P_0: 8 BMU
 SG_ BMU_M11_T00 : 0|8@1+ (1,0) [0|255] "degC" ECU,LOGGER
 SG_ BMU_M11_T01 : 8|8@1+ (1,0) [0|255] "degC" ECU,LOGGER
 SG_ BMU_M11_T02 : 16|8@1+ (1,0) [0|255] "degC" ECU,LOGGER
 SG_ BMU_M11_T03 : 24|8@1+ (1,0) [0|255] "degC" ECU,LOGGER
 SG_ BMU_M11_T04 : 32|8@1+ (1,0) [0|255] "degC" ECU,LOGGER
 SG_ BMU_M11_T05 : 40|8@1+ (1,0) [0|255] "degC" ECU,LOGGER
 SG_ BMU_M11_TAge0 : 48|16@1+ (1,0) [0|65535] "ms" ECU,LOGGER

BO_ 2284094641 BMU_TransmitTemperature_N_11_P_1: 8 BMU
 SG_ BMU_M11_T06 : 0|8@1+ (1,0) [0|255] "degC" ECU,LOGGER
 SG_ BMU_M11_T07 : 8|8@1+ (1,0) [0|255] "degC" ECU,LOGGER
 SG_ BMU_M11_T08 : 16|8@1+ (1,0) [0|255] "degC" ECU,LOGGER
 SG_ BMU_M11_T09 : 24|8@1+ (1,0) [0|255] "degC" ECU,LOGGER
 SG_ BMU_M11_T10 : 32|8@1+ (1,0) [0|255] "degC" ECU,LOGGER
 SG_ BMU_M11_T11 : 40|8@1+ (1,0) [0|255] "degC" ECU,LOGGER
 SG_ BMU_M11_TAge1 : 48|16@1+ (1,0) [0|65535] "ms" ECU,LOGGER

BO_ 2284095664 BMU_TransmitBalancing_N_11: 8 BMU
 SG_ BMU_M11_Balance : 0|16@1+ (1,0) [0|65535] "" LOGGER
 SG_ BMU_M11_DieTemp : 16|8@1+ (1,0) [0|255] "degC" LOGGER

BO_ 2284093632 BMU_TransmitVoltage_N_12_P_0: 8 BMU
 SG_ BMU_M12_V00 : 0|16@1+ (1,0) [0|65535] "mV" LOGGER
 SG_ BMU_M12_V01 : 16|16@1+ (1,0) [0|65535] "mV" LOGGER
 SG_ BMU_M12_V02 : 32|16@1+ (1,0) [0|65535] "mV" LOGGER
 SG_ BMU_M12_VAge0 : 48|16@1+ (1,0) [0|65535] "ms" LOGGER

BO_ 2284093633 BMU_TransmitVoltage_N_12_P_1: 8 BMU
 SG_ BMU_M12_V03 : 0|16@1+ (1,0) [0|65535] "mV" LOGGER
 SG_ BMU_M12_V04 : 16|16@1+ (1,0) [0|65535] "mV" LOGGER
 SG_ BMU_M12_V05 : 32|16@1+ (1,0) [0|65535] "mV" LOGGER
 SG_ BMU_M12_VAge1 : 48|16@1+ (1,0) [0|65535] "ms" LOGGER

BO_ 2284093634 BMU_TransmitVoltage_N_12_P_2: 8 BMU
 SG_ BMU_M12_V06 : 0|16@1+ (1,0) [0|65535] "mV" LOGGER
 SG_ BMU_M12_V07 : 16|16@1+ (1,0) [0|65535] "mV" LOGGER
 SG_ BMU_M12_V08 : 32|16@1+ (1,0) [0|65535] "mV" LOGGER
 SG_ BMU_M12_VAge2 : 48|16@1+ (1,0) [0|65535] "ms" LOGGER

BO_ 2284093635 BMU_TransmitVoltage_N_12_P_3: 8 BMU
 SG_ BMU_M12_V09 : 0|16@1+ (1,0) [0|65535] "mV" LOGGER
 SG_ BMU_M12_V10 : 16|16@1+ (1,0) [0|65535] "mV" LOGGER
 SG_ BMU_M12_V11 : 32|16@1+ (1,0) [0|65535] "mV" LOGGER
 SG_ BMU_M12_VAge3 : 48|16@1+ (1,0) [0|65535] "ms" LOGGER

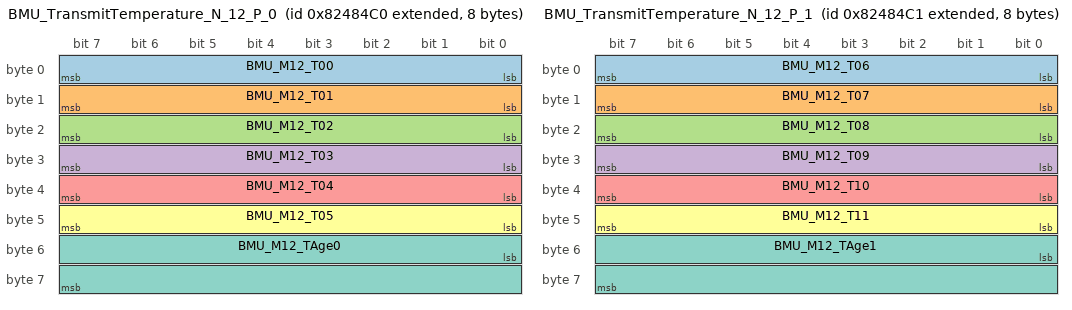
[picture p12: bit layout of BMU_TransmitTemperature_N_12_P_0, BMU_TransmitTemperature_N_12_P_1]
BO_ 2284094656 BMU_TransmitTemperature_N_12_P_0: 8 BMU
 SG_ BMU_M12_T00 : 0|8@1+ (1,0) [0|255] "degC" ECU,LOGGER
 SG_ BMU_M12_T01 : 8|8@1+ (1,0) [0|255] "degC" ECU,LOGGER
 SG_ BMU_M12_T02 : 16|8@1+ (1,0) [0|255] "degC" ECU,LOGGER
 SG_ BMU_M12_T03 : 24|8@1+ (1,0) [0|255] "degC" ECU,LOGGER
 SG_ BMU_M12_T04 : 32|8@1+ (1,0) [0|255] "degC" ECU,LOGGER
 SG_ BMU_M12_T05 : 40|8@1+ (1,0) [0|255] "degC" ECU,LOGGER
 SG_ BMU_M12_TAge0 : 48|16@1+ (1,0) [0|65535] "ms" ECU,LOGGER

BO_ 2284094657 BMU_TransmitTemperature_N_12_P_1: 8 BMU
 SG_ BMU_M12_T06 : 0|8@1+ (1,0) [0|255] "degC" ECU,LOGGER
 SG_ BMU_M12_T07 : 8|8@1+ (1,0) [0|255] "degC" ECU,LOGGER
 SG_ BMU_M12_T08 : 16|8@1+ (1,0) [0|255] "degC" ECU,LOGGER
 SG_ BMU_M12_T09 : 24|8@1+ (1,0) [0|255] "degC" ECU,LOGGER
 SG_ BMU_M12_T10 : 32|8@1+ (1,0) [0|255] "degC" ECU,LOGGER
 SG_ BMU_M12_T11 : 40|8@1+ (1,0) [0|255] "degC" ECU,LOGGER
 SG_ BMU_M12_TAge1 : 48|16@1+ (1,0) [0|65535] "ms" ECU,LOGGER

BO_ 2284095680 BMU_TransmitBalancing_N_12: 8 BMU
 SG_ BMU_M12_Balance : 0|16@1+ (1,0) [0|65535] "" LOGGER
 SG_ BMU_M12_DieTemp : 16|8@1+ (1,0) [0|255] "degC" LOGGER

BO_ 2284093648 BMU_TransmitVoltage_N_13_P_0: 8 BMU
 SG_ BMU_M13_V00 : 0|16@1+ (1,0) [0|65535] "mV" LOGGER
 SG_ BMU_M13_V01 : 16|16@1+ (1,0) [0|65535] "mV" LOGGER
 SG_ BMU_M13_V02 : 32|16@1+ (1,0) [0|65535] "mV" LOGGER
 SG_ BMU_M13_VAge0 : 48|16@1+ (1,0) [0|65535] "ms" LOGGER

BO_ 2284093649 BMU_TransmitVoltage_N_13_P_1: 8 BMU
 SG_ BMU_M13_V03 : 0|16@1+ (1,0) [0|65535] "mV" LOGGER
 SG_ BMU_M13_V04 : 16|16@1+ (1,0) [0|65535] "mV" LOGGER
 SG_ BMU_M13_V05 : 32|16@1+ (1,0) [0|65535] "mV" LOGGER
 SG_ BMU_M13_VAge1 : 48|16@1+ (1,0) [0|65535] "ms" LOGGER

BO_ 2284093650 BMU_TransmitVoltage_N_13_P_2: 8 BMU
 SG_ BMU_M13_V06 : 0|16@1+ (1,0) [0|65535] "mV" LOGGER
 SG_ BMU_M13_V07 : 16|16@1+ (1,0) [0|65535] "mV" LOGGER
 SG_ BMU_M13_V08 : 32|16@1+ (1,0) [0|65535] "mV" LOGGER
 SG_ BMU_M13_VAge2 : 48|16@1+ (1,0) [0|65535] "ms" LOGGER

BO_ 2284093651 BMU_TransmitVoltage_N_13_P_3: 8 BMU
 SG_ BMU_M13_V09 : 0|16@1+ (1,0) [0|65535] "mV" LOGGER
 SG_ BMU_M13_V10 : 16|16@1+ (1,0) [0|65535] "mV" LOGGER
 SG_ BMU_M13_V11 : 32|16@1+ (1,0) [0|65535] "mV" LOGGER
 SG_ BMU_M13_VAge3 : 48|16@1+ (1,0) [0|65535] "ms" LOGGER

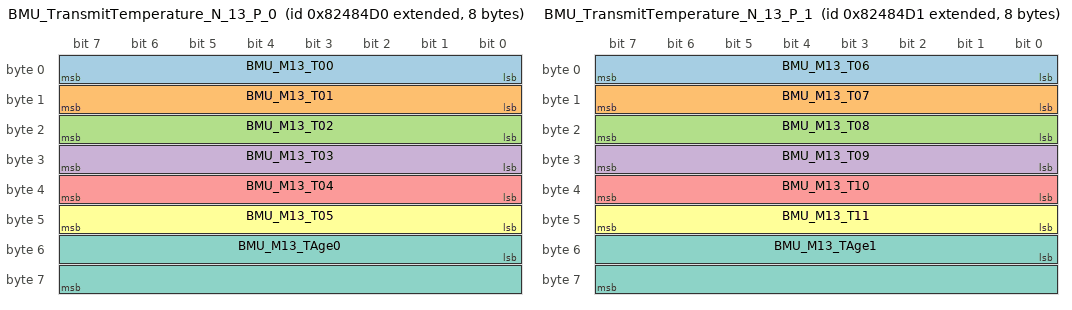
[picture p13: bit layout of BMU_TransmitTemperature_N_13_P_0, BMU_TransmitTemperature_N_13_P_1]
BO_ 2284094672 BMU_TransmitTemperature_N_13_P_0: 8 BMU
 SG_ BMU_M13_T00 : 0|8@1+ (1,0) [0|255] "degC" ECU,LOGGER
 SG_ BMU_M13_T01 : 8|8@1+ (1,0) [0|255] "degC" ECU,LOGGER
 SG_ BMU_M13_T02 : 16|8@1+ (1,0) [0|255] "degC" ECU,LOGGER
 SG_ BMU_M13_T03 : 24|8@1+ (1,0) [0|255] "degC" ECU,LOGGER
 SG_ BMU_M13_T04 : 32|8@1+ (1,0) [0|255] "degC" ECU,LOGGER
 SG_ BMU_M13_T05 : 40|8@1+ (1,0) [0|255] "degC" ECU,LOGGER
 SG_ BMU_M13_TAge0 : 48|16@1+ (1,0) [0|65535] "ms" ECU,LOGGER

BO_ 2284094673 BMU_TransmitTemperature_N_13_P_1: 8 BMU
 SG_ BMU_M13_T06 : 0|8@1+ (1,0) [0|255] "degC" ECU,LOGGER
 SG_ BMU_M13_T07 : 8|8@1+ (1,0) [0|255] "degC" ECU,LOGGER
 SG_ BMU_M13_T08 : 16|8@1+ (1,0) [0|255] "degC" ECU,LOGGER
 SG_ BMU_M13_T09 : 24|8@1+ (1,0) [0|255] "degC" ECU,LOGGER
 SG_ BMU_M13_T10 : 32|8@1+ (1,0) [0|255] "degC" ECU,LOGGER
 SG_ BMU_M13_T11 : 40|8@1+ (1,0) [0|255] "degC" ECU,LOGGER
 SG_ BMU_M13_TAge1 : 48|16@1+ (1,0) [0|65535] "ms" ECU,LOGGER

BO_ 2284095696 BMU_TransmitBalancing_N_13: 8 BMU
 SG_ BMU_M13_Balance : 0|16@1+ (1,0) [0|65535] "" LOGGER
 SG_ BMU_M13_DieTemp : 16|8@1+ (1,0) [0|255] "degC" LOGGER

BO_ 2284093664 BMU_TransmitVoltage_N_14_P_0: 8 BMU
 SG_ BMU_M14_V00 : 0|16@1+ (1,0) [0|65535] "mV" LOGGER
 SG_ BMU_M14_V01 : 16|16@1+ (1,0) [0|65535] "mV" LOGGER
 SG_ BMU_M14_V02 : 32|16@1+ (1,0) [0|65535] "mV" LOGGER
 SG_ BMU_M14_VAge0 : 48|16@1+ (1,0) [0|65535] "ms" LOGGER

BO_ 2284093665 BMU_TransmitVoltage_N_14_P_1: 8 BMU
 SG_ BMU_M14_V03 : 0|16@1+ (1,0) [0|65535] "mV" LOGGER
 SG_ BMU_M14_V04 : 16|16@1+ (1,0) [0|65535] "mV" LOGGER
 SG_ BMU_M14_V05 : 32|16@1+ (1,0) [0|65535] "mV" LOGGER
 SG_ BMU_M14_VAge1 : 48|16@1+ (1,0) [0|65535] "ms" LOGGER

BO_ 2284093666 BMU_TransmitVoltage_N_14_P_2: 8 BMU
 SG_ BMU_M14_V06 : 0|16@1+ (1,0) [0|65535] "mV" LOGGER
 SG_ BMU_M14_V07 : 16|16@1+ (1,0) [0|65535] "mV" LOGGER
 SG_ BMU_M14_V08 : 32|16@1+ (1,0) [0|65535] "mV" LOGGER
 SG_ BMU_M14_VAge2 : 48|16@1+ (1,0) [0|65535] "ms" LOGGER

BO_ 2284093667 BMU_TransmitVoltage_N_14_P_3: 8 BMU
 SG_ BMU_M14_V09 : 0|16@1+ (1,0) [0|65535] "mV" LOGGER
 SG_ BMU_M14_V10 : 16|16@1+ (1,0) [0|65535] "mV" LOGGER
 SG_ BMU_M14_V11 : 32|16@1+ (1,0) [0|65535] "mV" LOGGER
 SG_ BMU_M14_VAge3 : 48|16@1+ (1,0) [0|65535] "ms" LOGGER

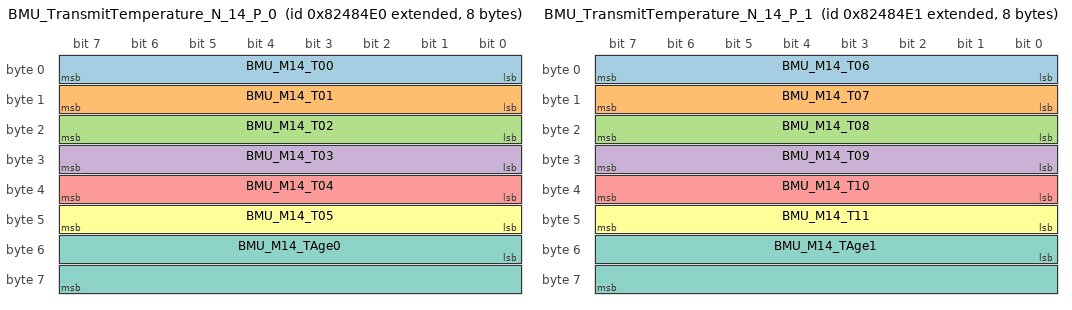
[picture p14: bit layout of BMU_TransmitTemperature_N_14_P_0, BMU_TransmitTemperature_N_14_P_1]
BO_ 2284094688 BMU_TransmitTemperature_N_14_P_0: 8 BMU
 SG_ BMU_M14_T00 : 0|8@1+ (1,0) [0|255] "degC" ECU,LOGGER
 SG_ BMU_M14_T01 : 8|8@1+ (1,0) [0|255] "degC" ECU,LOGGER
 SG_ BMU_M14_T02 : 16|8@1+ (1,0) [0|255] "degC" ECU,LOGGER
 SG_ BMU_M14_T03 : 24|8@1+ (1,0) [0|255] "degC" ECU,LOGGER
 SG_ BMU_M14_T04 : 32|8@1+ (1,0) [0|255] "degC" ECU,LOGGER
 SG_ BMU_M14_T05 : 40|8@1+ (1,0) [0|255] "degC" ECU,LOGGER
 SG_ BMU_M14_TAge0 : 48|16@1+ (1,0) [0|65535] "ms" ECU,LOGGER

BO_ 2284094689 BMU_TransmitTemperature_N_14_P_1: 8 BMU
 SG_ BMU_M14_T06 : 0|8@1+ (1,0) [0|255] "degC" ECU,LOGGER
 SG_ BMU_M14_T07 : 8|8@1+ (1,0) [0|255] "degC" ECU,LOGGER
 SG_ BMU_M14_T08 : 16|8@1+ (1,0) [0|255] "degC" ECU,LOGGER
 SG_ BMU_M14_T09 : 24|8@1+ (1,0) [0|255] "degC" ECU,LOGGER
 SG_ BMU_M14_T10 : 32|8@1+ (1,0) [0|255] "degC" ECU,LOGGER
 SG_ BMU_M14_T11 : 40|8@1+ (1,0) [0|255] "degC" ECU,LOGGER
 SG_ BMU_M14_TAge1 : 48|16@1+ (1,0) [0|65535] "ms" ECU,LOGGER

BO_ 2284095712 BMU_TransmitBalancing_N_14: 8 BMU
 SG_ BMU_M14_Balance : 0|16@1+ (1,0) [0|65535] "" LOGGER
 SG_ BMU_M14_DieTemp : 16|8@1+ (1,0) [0|255] "degC" LOGGER

BO_ 2284093680 BMU_TransmitVoltage_N_15_P_0: 8 BMU
 SG_ BMU_M15_V00 : 0|16@1+ (1,0) [0|65535] "mV" LOGGER
 SG_ BMU_M15_V01 : 16|16@1+ (1,0) [0|65535] "mV" LOGGER
 SG_ BMU_M15_V02 : 32|16@1+ (1,0) [0|65535] "mV" LOGGER
 SG_ BMU_M15_VAge0 : 48|16@1+ (1,0) [0|65535] "ms" LOGGER

BO_ 2284093681 BMU_TransmitVoltage_N_15_P_1: 8 BMU
 SG_ BMU_M15_V03 : 0|16@1+ (1,0) [0|65535] "mV" LOGGER
 SG_ BMU_M15_V04 : 16|16@1+ (1,0) [0|65535] "mV" LOGGER
 SG_ BMU_M15_V05 : 32|16@1+ (1,0) [0|65535] "mV" LOGGER
 SG_ BMU_M15_VAge1 : 48|16@1+ (1,0) [0|65535] "ms" LOGGER

BO_ 2284093682 BMU_TransmitVoltage_N_15_P_2: 8 BMU
 SG_ BMU_M15_V06 : 0|16@1+ (1,0) [0|65535] "mV" LOGGER
 SG_ BMU_M15_V07 : 16|16@1+ (1,0) [0|65535] "mV" LOGGER
 SG_ BMU_M15_V08 : 32|16@1+ (1,0) [0|65535] "mV" LOGGER
 SG_ BMU_M15_VAge2 : 48|16@1+ (1,0) [0|65535] "ms" LOGGER

BO_ 2284093683 BMU_TransmitVoltage_N_15_P_3: 8 BMU
 SG_ BMU_M15_V09 : 0|16@1+ (1,0) [0|65535] "mV" LOGGER
 SG_ BMU_M15_V10 : 16|16@1+ (1,0) [0|65535] "mV" LOGGER
 SG_ BMU_M15_V11 : 32|16@1+ (1,0) [0|65535] "mV" LOGGER
 SG_ BMU_M15_VAge3 : 48|16@1+ (1,0) [0|65535] "ms" LOGGER

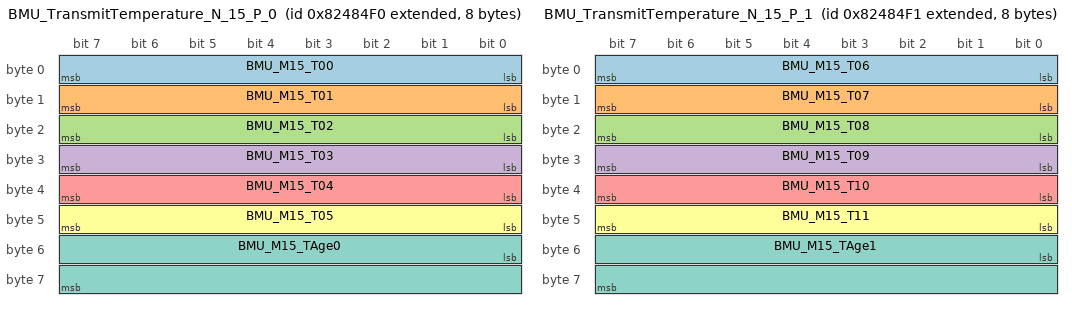
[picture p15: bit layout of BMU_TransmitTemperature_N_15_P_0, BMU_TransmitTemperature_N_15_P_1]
BO_ 2284094704 BMU_TransmitTemperature_N_15_P_0: 8 BMU
 SG_ BMU_M15_T00 : 0|8@1+ (1,0) [0|255] "degC" ECU,LOGGER
 SG_ BMU_M15_T01 : 8|8@1+ (1,0) [0|255] "degC" ECU,LOGGER
 SG_ BMU_M15_T02 : 16|8@1+ (1,0) [0|255] "degC" ECU,LOGGER
 SG_ BMU_M15_T03 : 24|8@1+ (1,0) [0|255] "degC" ECU,LOGGER
 SG_ BMU_M15_T04 : 32|8@1+ (1,0) [0|255] "degC" ECU,LOGGER
 SG_ BMU_M15_T05 : 40|8@1+ (1,0) [0|255] "degC" ECU,LOGGER
 SG_ BMU_M15_TAge0 : 48|16@1+ (1,0) [0|65535] "ms" ECU,LOGGER

BO_ 2284094705 BMU_TransmitTemperature_N_15_P_1: 8 BMU
 SG_ BMU_M15_T06 : 0|8@1+ (1,0) [0|255] "degC" ECU,LOGGER
 SG_ BMU_M15_T07 : 8|8@1+ (1,0) [0|255] "degC" ECU,LOGGER
 SG_ BMU_M15_T08 : 16|8@1+ (1,0) [0|255] "degC" ECU,LOGGER
 SG_ BMU_M15_T09 : 24|8@1+ (1,0) [0|255] "degC" ECU,LOGGER
 SG_ BMU_M15_T10 : 32|8@1+ (1,0) [0|255] "degC" ECU,LOGGER
 SG_ BMU_M15_T11 : 40|8@1+ (1,0) [0|255] "degC" ECU,LOGGER
 SG_ BMU_M15_TAge1 : 48|16@1+ (1,0) [0|65535] "ms" ECU,LOGGER

BO_ 2284095728 BMU_TransmitBalancing_N_15: 8 BMU
 SG_ BMU_M15_Balance : 0|16@1+ (1,0) [0|65535] "" LOGGER
 SG_ BMU_M15_DieTemp : 16|8@1+ (1,0) [0|255] "degC" LOGGER

BO_ 2284093696 BMU_TransmitVoltage_N_16_P_0: 8 BMU
 SG_ BMU_M16_V00 : 0|16@1+ (1,0) [0|65535] "mV" LOGGER
 SG_ BMU_M16_V01 : 16|16@1+ (1,0) [0|65535] "mV" LOGGER
 SG_ BMU_M16_V02 : 32|16@1+ (1,0) [0|65535] "mV" LOGGER
 SG_ BMU_M16_VAge0 : 48|16@1+ (1,0) [0|65535] "ms" LOGGER

BO_ 2284093697 BMU_TransmitVoltage_N_16_P_1: 8 BMU
 SG_ BMU_M16_V03 : 0|16@1+ (1,0) [0|65535] "mV" LOGGER
 SG_ BMU_M16_V04 : 16|16@1+ (1,0) [0|65535] "mV" LOGGER
 SG_ BMU_M16_V05 : 32|16@1+ (1,0) [0|65535] "mV" LOGGER
 SG_ BMU_M16_VAge1 : 48|16@1+ (1,0) [0|65535] "ms" LOGGER

BO_ 2284093698 BMU_TransmitVoltage_N_16_P_2: 8 BMU
 SG_ BMU_M16_V06 : 0|16@1+ (1,0) [0|65535] "mV" LOGGER
 SG_ BMU_M16_V07 : 16|16@1+ (1,0) [0|65535] "mV" LOGGER
 SG_ BMU_M16_V08 : 32|16@1+ (1,0) [0|65535] "mV" LOGGER
 SG_ BMU_M16_VAge2 : 48|16@1+ (1,0) [0|65535] "ms" LOGGER

BO_ 2284093699 BMU_TransmitVoltage_N_16_P_3: 8 BMU
 SG_ BMU_M16_V09 : 0|16@1+ (1,0) [0|65535] "mV" LOGGER
 SG_ BMU_M16_V10 : 16|16@1+ (1,0) [0|65535] "mV" LOGGER
 SG_ BMU_M16_V11 : 32|16@1+ (1,0) [0|65535] "mV" LOGGER
 SG_ BMU_M16_VAge3 : 48|16@1+ (1,0) [0|65535] "ms" LOGGER

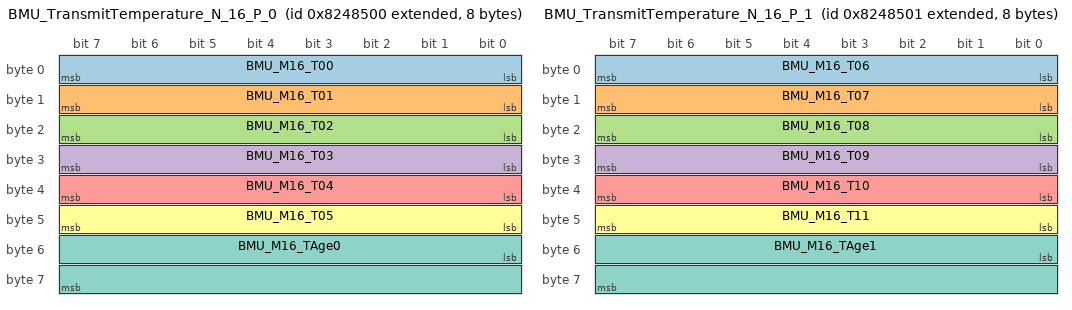
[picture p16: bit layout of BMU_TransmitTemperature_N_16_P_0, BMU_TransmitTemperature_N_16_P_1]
BO_ 2284094720 BMU_TransmitTemperature_N_16_P_0: 8 BMU
 SG_ BMU_M16_T00 : 0|8@1+ (1,0) [0|255] "degC" ECU,LOGGER
 SG_ BMU_M16_T01 : 8|8@1+ (1,0) [0|255] "degC" ECU,LOGGER
 SG_ BMU_M16_T02 : 16|8@1+ (1,0) [0|255] "degC" ECU,LOGGER
 SG_ BMU_M16_T03 : 24|8@1+ (1,0) [0|255] "degC" ECU,LOGGER
 SG_ BMU_M16_T04 : 32|8@1+ (1,0) [0|255] "degC" ECU,LOGGER
 SG_ BMU_M16_T05 : 40|8@1+ (1,0) [0|255] "degC" ECU,LOGGER
 SG_ BMU_M16_TAge0 : 48|16@1+ (1,0) [0|65535] "ms" ECU,LOGGER

BO_ 2284094721 BMU_TransmitTemperature_N_16_P_1: 8 BMU
 SG_ BMU_M16_T06 : 0|8@1+ (1,0) [0|255] "degC" ECU,LOGGER
 SG_ BMU_M16_T07 : 8|8@1+ (1,0) [0|255] "degC" ECU,LOGGER
 SG_ BMU_M16_T08 : 16|8@1+ (1,0) [0|255] "degC" ECU,LOGGER
 SG_ BMU_M16_T09 : 24|8@1+ (1,0) [0|255] "degC" ECU,LOGGER
 SG_ BMU_M16_T10 : 32|8@1+ (1,0) [0|255] "degC" ECU,LOGGER
 SG_ BMU_M16_T11 : 40|8@1+ (1,0) [0|255] "degC" ECU,LOGGER
 SG_ BMU_M16_TAge1 : 48|16@1+ (1,0) [0|65535] "ms" ECU,LOGGER

BO_ 2284095744 BMU_TransmitBalancing_N_16: 8 BMU
 SG_ BMU_M16_Balance : 0|16@1+ (1,0) [0|65535] "" LOGGER
 SG_ BMU_M16_DieTemp : 16|8@1+ (1,0) [0|255] "degC" LOGGER

BO_ 2284093712 BMU_TransmitVoltage_N_17_P_0: 8 BMU
 SG_ BMU_M17_V00 : 0|16@1+ (1,0) [0|65535] "mV" LOGGER
 SG_ BMU_M17_V01 : 16|16@1+ (1,0) [0|65535] "mV" LOGGER
 SG_ BMU_M17_V02 : 32|16@1+ (1,0) [0|65535] "mV" LOGGER
 SG_ BMU_M17_VAge0 : 48|16@1+ (1,0) [0|65535] "ms" LOGGER

BO_ 2284093713 BMU_TransmitVoltage_N_17_P_1: 8 BMU
 SG_ BMU_M17_V03 : 0|16@1+ (1,0) [0|65535] "mV" LOGGER
 SG_ BMU_M17_V04 : 16|16@1+ (1,0) [0|65535] "mV" LOGGER
 SG_ BMU_M17_V05 : 32|16@1+ (1,0) [0|65535] "mV" LOGGER
 SG_ BMU_M17_VAge1 : 48|16@1+ (1,0) [0|65535] "ms" LOGGER

BO_ 2284093714 BMU_TransmitVoltage_N_17_P_2: 8 BMU
 SG_ BMU_M17_V06 : 0|16@1+ (1,0) [0|65535] "mV" LOGGER
 SG_ BMU_M17_V07 : 16|16@1+ (1,0) [0|65535] "mV" LOGGER
 SG_ BMU_M17_V08 : 32|16@1+ (1,0) [0|65535] "mV" LOGGER
 SG_ BMU_M17_VAge2 : 48|16@1+ (1,0) [0|65535] "ms" LOGGER

BO_ 2284093715 BMU_TransmitVoltage_N_17_P_3: 8 BMU
 SG_ BMU_M17_V09 : 0|16@1+ (1,0) [0|65535] "mV" LOGGER
 SG_ BMU_M17_V10 : 16|16@1+ (1,0) [0|65535] "mV" LOGGER
 SG_ BMU_M17_V11 : 32|16@1+ (1,0) [0|65535] "mV" LOGGER
 SG_ BMU_M17_VAge3 : 48|16@1+ (1,0) [0|65535] "ms" LOGGER

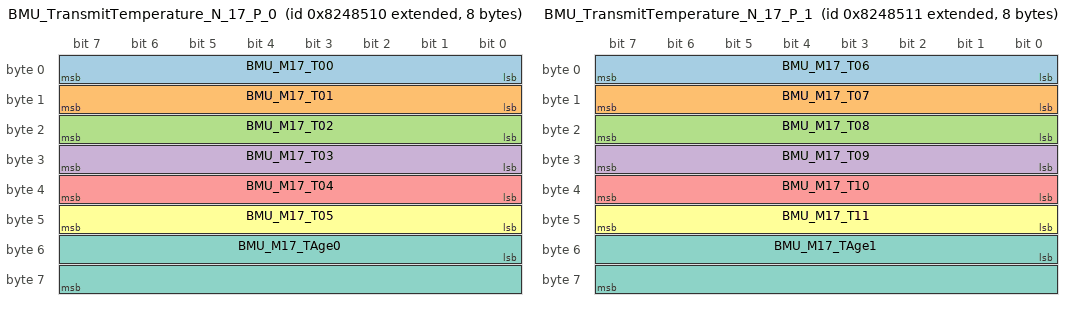
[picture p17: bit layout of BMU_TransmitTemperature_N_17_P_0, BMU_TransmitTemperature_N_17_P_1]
BO_ 2284094736 BMU_TransmitTemperature_N_17_P_0: 8 BMU
 SG_ BMU_M17_T00 : 0|8@1+ (1,0) [0|255] "degC" ECU,LOGGER
 SG_ BMU_M17_T01 : 8|8@1+ (1,0) [0|255] "degC" ECU,LOGGER
 SG_ BMU_M17_T02 : 16|8@1+ (1,0) [0|255] "degC" ECU,LOGGER
 SG_ BMU_M17_T03 : 24|8@1+ (1,0) [0|255] "degC" ECU,LOGGER
 SG_ BMU_M17_T04 : 32|8@1+ (1,0) [0|255] "degC" ECU,LOGGER
 SG_ BMU_M17_T05 : 40|8@1+ (1,0) [0|255] "degC" ECU,LOGGER
 SG_ BMU_M17_TAge0 : 48|16@1+ (1,0) [0|65535] "ms" ECU,LOGGER

BO_ 2284094737 BMU_TransmitTemperature_N_17_P_1: 8 BMU
 SG_ BMU_M17_T06 : 0|8@1+ (1,0) [0|255] "degC" ECU,LOGGER
 SG_ BMU_M17_T07 : 8|8@1+ (1,0) [0|255] "degC" ECU,LOGGER
 SG_ BMU_M17_T08 : 16|8@1+ (1,0) [0|255] "degC" ECU,LOGGER
 SG_ BMU_M17_T09 : 24|8@1+ (1,0) [0|255] "degC" ECU,LOGGER
 SG_ BMU_M17_T10 : 32|8@1+ (1,0) [0|255] "degC" ECU,LOGGER
 SG_ BMU_M17_T11 : 40|8@1+ (1,0) [0|255] "degC" ECU,LOGGER
 SG_ BMU_M17_TAge1 : 48|16@1+ (1,0) [0|65535] "ms" ECU,LOGGER

BO_ 2284095760 BMU_TransmitBalancing_N_17: 8 BMU
 SG_ BMU_M17_Balance : 0|16@1+ (1,0) [0|65535] "" LOGGER
 SG_ BMU_M17_DieTemp : 16|8@1+ (1,0) [0|255] "degC" LOGGER

BO_ 2284093728 BMU_TransmitVoltage_N_18_P_0: 8 BMU
 SG_ BMU_M18_V00 : 0|16@1+ (1,0) [0|65535] "mV" LOGGER
 SG_ BMU_M18_V01 : 16|16@1+ (1,0) [0|65535] "mV" LOGGER
 SG_ BMU_M18_V02 : 32|16@1+ (1,0) [0|65535] "mV" LOGGER
 SG_ BMU_M18_VAge0 : 48|16@1+ (1,0) [0|65535] "ms" LOGGER

BO_ 2284093729 BMU_TransmitVoltage_N_18_P_1: 8 BMU
 SG_ BMU_M18_V03 : 0|16@1+ (1,0) [0|65535] "mV" LOGGER
 SG_ BMU_M18_V04 : 16|16@1+ (1,0) [0|65535] "mV" LOGGER
 SG_ BMU_M18_V05 : 32|16@1+ (1,0) [0|65535] "mV" LOGGER
 SG_ BMU_M18_VAge1 : 48|16@1+ (1,0) [0|65535] "ms" LOGGER

BO_ 2284093730 BMU_TransmitVoltage_N_18_P_2: 8 BMU
 SG_ BMU_M18_V06 : 0|16@1+ (1,0) [0|65535] "mV" LOGGER
 SG_ BMU_M18_V07 : 16|16@1+ (1,0) [0|65535] "mV" LOGGER
 SG_ BMU_M18_V08 : 32|16@1+ (1,0) [0|65535] "mV" LOGGER
 SG_ BMU_M18_VAge2 : 48|16@1+ (1,0) [0|65535] "ms" LOGGER

BO_ 2284093731 BMU_TransmitVoltage_N_18_P_3: 8 BMU
 SG_ BMU_M18_V09 : 0|16@1+ (1,0) [0|65535] "mV" LOGGER
 SG_ BMU_M18_V10 : 16|16@1+ (1,0) [0|65535] "mV" LOGGER
 SG_ BMU_M18_V11 : 32|16@1+ (1,0) [0|65535] "mV" LOGGER
 SG_ BMU_M18_VAge3 : 48|16@1+ (1,0) [0|65535] "ms" LOGGER

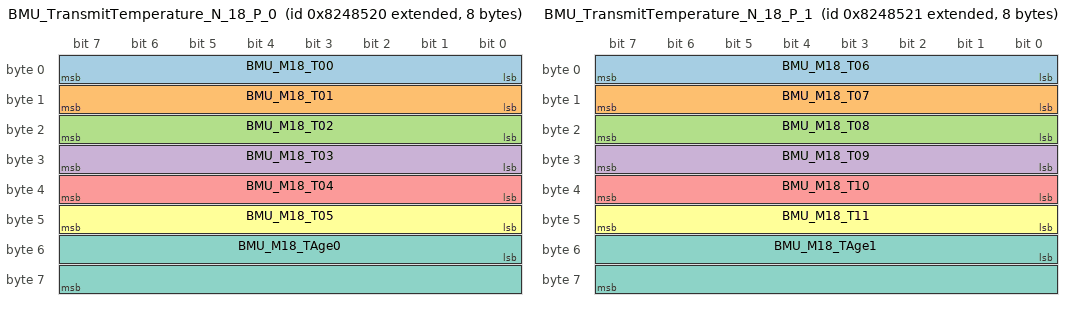
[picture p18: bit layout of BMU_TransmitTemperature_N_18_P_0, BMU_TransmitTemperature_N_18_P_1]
BO_ 2284094752 BMU_TransmitTemperature_N_18_P_0: 8 BMU
 SG_ BMU_M18_T00 : 0|8@1+ (1,0) [0|255] "degC" ECU,LOGGER
 SG_ BMU_M18_T01 : 8|8@1+ (1,0) [0|255] "degC" ECU,LOGGER
 SG_ BMU_M18_T02 : 16|8@1+ (1,0) [0|255] "degC" ECU,LOGGER
 SG_ BMU_M18_T03 : 24|8@1+ (1,0) [0|255] "degC" ECU,LOGGER
 SG_ BMU_M18_T04 : 32|8@1+ (1,0) [0|255] "degC" ECU,LOGGER
 SG_ BMU_M18_T05 : 40|8@1+ (1,0) [0|255] "degC" ECU,LOGGER
 SG_ BMU_M18_TAge0 : 48|16@1+ (1,0) [0|65535] "ms" ECU,LOGGER

BO_ 2284094753 BMU_TransmitTemperature_N_18_P_1: 8 BMU
 SG_ BMU_M18_T06 : 0|8@1+ (1,0) [0|255] "degC" ECU,LOGGER
 SG_ BMU_M18_T07 : 8|8@1+ (1,0) [0|255] "degC" ECU,LOGGER
 SG_ BMU_M18_T08 : 16|8@1+ (1,0) [0|255] "degC" ECU,LOGGER
 SG_ BMU_M18_T09 : 24|8@1+ (1,0) [0|255] "degC" ECU,LOGGER
 SG_ BMU_M18_T10 : 32|8@1+ (1,0) [0|255] "degC" ECU,LOGGER
 SG_ BMU_M18_T11 : 40|8@1+ (1,0) [0|255] "degC" ECU,LOGGER
 SG_ BMU_M18_TAge1 : 48|16@1+ (1,0) [0|65535] "ms" ECU,LOGGER

BO_ 2284095776 BMU_TransmitBalancing_N_18: 8 BMU
 SG_ BMU_M18_Balance : 0|16@1+ (1,0) [0|65535] "" LOGGER
 SG_ BMU_M18_DieTemp : 16|8@1+ (1,0) [0|255] "degC" LOGGER

BO_ 2284093744 BMU_TransmitVoltage_N_19_P_0: 8 BMU
 SG_ BMU_M19_V00 : 0|16@1+ (1,0) [0|65535] "mV" LOGGER
 SG_ BMU_M19_V01 : 16|16@1+ (1,0) [0|65535] "mV" LOGGER
 SG_ BMU_M19_V02 : 32|16@1+ (1,0) [0|65535] "mV" LOGGER
 SG_ BMU_M19_VAge0 : 48|16@1+ (1,0) [0|65535] "ms" LOGGER

BO_ 2284093745 BMU_TransmitVoltage_N_19_P_1: 8 BMU
 SG_ BMU_M19_V03 : 0|16@1+ (1,0) [0|65535] "mV" LOGGER
 SG_ BMU_M19_V04 : 16|16@1+ (1,0) [0|65535] "mV" LOGGER
 SG_ BMU_M19_V05 : 32|16@1+ (1,0) [0|65535] "mV" LOGGER
 SG_ BMU_M19_VAge1 : 48|16@1+ (1,0) [0|65535] "ms" LOGGER

BO_ 2284093746 BMU_TransmitVoltage_N_19_P_2: 8 BMU
 SG_ BMU_M19_V06 : 0|16@1+ (1,0) [0|65535] "mV" LOGGER
 SG_ BMU_M19_V07 : 16|16@1+ (1,0) [0|65535] "mV" LOGGER
 SG_ BMU_M19_V08 : 32|16@1+ (1,0) [0|65535] "mV" LOGGER
 SG_ BMU_M19_VAge2 : 48|16@1+ (1,0) [0|65535] "ms" LOGGER

BO_ 2284093747 BMU_TransmitVoltage_N_19_P_3: 8 BMU
 SG_ BMU_M19_V09 : 0|16@1+ (1,0) [0|65535] "mV" LOGGER
 SG_ BMU_M19_V10 : 16|16@1+ (1,0) [0|65535] "mV" LOGGER
 SG_ BMU_M19_V11 : 32|16@1+ (1,0) [0|65535] "mV" LOGGER
 SG_ BMU_M19_VAge3 : 48|16@1+ (1,0) [0|65535] "ms" LOGGER

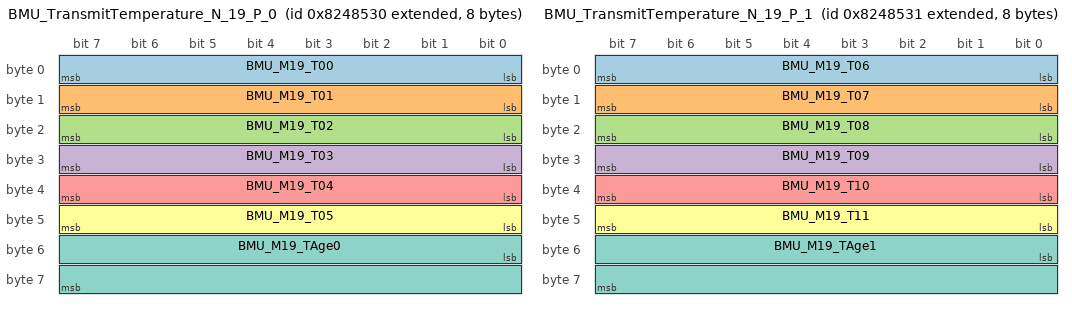
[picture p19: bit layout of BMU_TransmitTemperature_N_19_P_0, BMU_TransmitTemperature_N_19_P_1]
BO_ 2284094768 BMU_TransmitTemperature_N_19_P_0: 8 BMU
 SG_ BMU_M19_T00 : 0|8@1+ (1,0) [0|255] "degC" ECU,LOGGER
 SG_ BMU_M19_T01 : 8|8@1+ (1,0) [0|255] "degC" ECU,LOGGER
 SG_ BMU_M19_T02 : 16|8@1+ (1,0) [0|255] "degC" ECU,LOGGER
 SG_ BMU_M19_T03 : 24|8@1+ (1,0) [0|255] "degC" ECU,LOGGER
 SG_ BMU_M19_T04 : 32|8@1+ (1,0) [0|255] "degC" ECU,LOGGER
 SG_ BMU_M19_T05 : 40|8@1+ (1,0) [0|255] "degC" ECU,LOGGER
 SG_ BMU_M19_TAge0 : 48|16@1+ (1,0) [0|65535] "ms" ECU,LOGGER

BO_ 2284094769 BMU_TransmitTemperature_N_19_P_1: 8 BMU
 SG_ BMU_M19_T06 : 0|8@1+ (1,0) [0|255] "degC" ECU,LOGGER
 SG_ BMU_M19_T07 : 8|8@1+ (1,0) [0|255] "degC" ECU,LOGGER
 SG_ BMU_M19_T08 : 16|8@1+ (1,0) [0|255] "degC" ECU,LOGGER
 SG_ BMU_M19_T09 : 24|8@1+ (1,0) [0|255] "degC" ECU,LOGGER
 SG_ BMU_M19_T10 : 32|8@1+ (1,0) [0|255] "degC" ECU,LOGGER
 SG_ BMU_M19_T11 : 40|8@1+ (1,0) [0|255] "degC" ECU,LOGGER
 SG_ BMU_M19_TAge1 : 48|16@1+ (1,0) [0|65535] "ms" ECU,LOGGER

BO_ 2284095792 BMU_TransmitBalancing_N_19: 8 BMU
 SG_ BMU_M19_Balance : 0|16@1+ (1,0) [0|65535] "" LOGGER
 SG_ BMU_M19_DieTemp : 16|8@1+ (1,0) [0|255] "degC" LOGGER

BO_ 2284093760 BMU_TransmitVoltage_N_20_P_0: 8 BMU
 SG_ BMU_M20_V00 : 0|16@1+ (1,0) [0|65535] "mV" LOGGER
 SG_ BMU_M20_V01 : 16|16@1+ (1,0) [0|65535] "mV" LOGGER
 SG_ BMU_M20_V02 : 32|16@1+ (1,0) [0|65535] "mV" LOGGER
 SG_ BMU_M20_VAge0 : 48|16@1+ (1,0) [0|65535] "ms" LOGGER

BO_ 2284093761 BMU_TransmitVoltage_N_20_P_1: 8 BMU
 SG_ BMU_M20_V03 : 0|16@1+ (1,0) [0|65535] "mV" LOGGER
 SG_ BMU_M20_V04 : 16|16@1+ (1,0) [0|65535] "mV" LOGGER
 SG_ BMU_M20_V05 : 32|16@1+ (1,0) [0|65535] "mV" LOGGER
 SG_ BMU_M20_VAge1 : 48|16@1+ (1,0) [0|65535] "ms" LOGGER

BO_ 2284093762 BMU_TransmitVoltage_N_20_P_2: 8 BMU
 SG_ BMU_M20_V06 : 0|16@1+ (1,0) [0|65535] "mV" LOGGER
 SG_ BMU_M20_V07 : 16|16@1+ (1,0) [0|65535] "mV" LOGGER
 SG_ BMU_M20_V08 : 32|16@1+ (1,0) [0|65535] "mV" LOGGER
 SG_ BMU_M20_VAge2 : 48|16@1+ (1,0) [0|65535] "ms" LOGGER

BO_ 2284093763 BMU_TransmitVoltage_N_20_P_3: 8 BMU
 SG_ BMU_M20_V09 : 0|16@1+ (1,0) [0|65535] "mV" LOGGER
 SG_ BMU_M20_V10 : 16|16@1+ (1,0) [0|65535] "mV" LOGGER
 SG_ BMU_M20_V11 : 32|16@1+ (1,0) [0|65535] "mV" LOGGER
 SG_ BMU_M20_VAge3 : 48|16@1+ (1,0) [0|65535] "ms" LOGGER

BO_ 2284094784 BMU_TransmitTemperature_N_20_P_0: 8 BMU
 SG_ BMU_M20_T00 : 0|8@1+ (1,0) [0|255] "degC" ECU,LOGGER
 SG_ BMU_M20_T01 : 8|8@1+ (1,0) [0|255] "degC" ECU,LOGGER
 SG_ BMU_M20_T02 : 16|8@1+ (1,0) [0|255] "degC" ECU,LOGGER
 SG_ BMU_M20_T03 : 24|8@1+ (1,0) [0|255] "degC" ECU,LOGGER
 SG_ BMU_M20_T04 : 32|8@1+ (1,0) [0|255] "degC" ECU,LOGGER
 SG_ BMU_M20_T05 : 40|8@1+ (1,0) [0|255] "degC" ECU,LOGGER
 SG_ BMU_M20_TAge0 : 48|16@1+ (1,0) [0|65535] "ms" ECU,LOGGER

BO_ 2284094785 BMU_TransmitTemperature_N_20_P_1: 8 BMU
 SG_ BMU_M20_T06 : 0|8@1+ (1,0) [0|255] "degC" ECU,LOGGER
 SG_ BMU_M20_T07 : 8|8@1+ (1,0) [0|255] "degC" ECU,LOGGER
 SG_ BMU_M20_T08 : 16|8@1+ (1,0) [0|255] "degC" ECU,LOGGER
 SG_ BMU_M20_T09 : 24|8@1+ (1,0) [0|255] "degC" ECU,LOGGER
 SG_ BMU_M20_T10 : 32|8@1+ (1,0) [0|255] "degC" ECU,LOGGER
 SG_ BMU_M20_T11 : 40|8@1+ (1,0) [0|255] "degC" ECU,LOGGER
 SG_ BMU_M20_TAge1 : 48|16@1+ (1,0) [0|65535] "ms" ECU,LOGGER

BO_ 2284095808 BMU_TransmitBalancing_N_20: 8 BMU
 SG_ BMU_M20_Balance : 0|16@1+ (1,0) [0|65535] "" LOGGER
 SG_ BMU_M20_DieTemp : 16|8@1+ (1,0) [0|255] "degC" LOGGER

BO_ 2284093776 BMU_TransmitVoltage_N_21_P_0: 8 BMU
 SG_ BMU_M21_V00 : 0|16@1+ (1,0) [0|65535] "mV" LOGGER
 SG_ BMU_M21_V01 : 16|16@1+ (1,0) [0|65535] "mV" LOGGER
 SG_ BMU_M21_V02 : 32|16@1+ (1,0) [0|65535] "mV" LOGGER
 SG_ BMU_M21_VAge0 : 48|16@1+ (1,0) [0|65535] "ms" LOGGER

BO_ 2284093777 BMU_TransmitVoltage_N_21_P_1: 8 BMU
 SG_ BMU_M21_V03 : 0|16@1+ (1,0) [0|65535] "mV" LOGGER
 SG_ BMU_M21_V04 : 16|16@1+ (1,0) [0|65535] "mV" LOGGER
 SG_ BMU_M21_V05 : 32|16@1+ (1,0) [0|65535] "mV" LOGGER
 SG_ BMU_M21_VAge1 : 48|16@1+ (1,0) [0|65535] "ms" LOGGER

BO_ 2284093778 BMU_TransmitVoltage_N_21_P_2: 8 BMU
 SG_ BMU_M21_V06 : 0|16@1+ (1,0) [0|65535] "mV" LOGGER
 SG_ BMU_M21_V07 : 16|16@1+ (1,0) [0|65535] "mV" LOGGER
 SG_ BMU_M21_V08 : 32|16@1+ (1,0) [0|65535] "mV" LOGGER
 SG_ BMU_M21_VAge2 : 48|16@1+ (1,0) [0|65535] "ms" LOGGER

BO_ 2284093779 BMU_TransmitVoltage_N_21_P_3: 8 BMU
 SG_ BMU_M21_V09 : 0|16@1+ (1,0) [0|65535] "mV" LOGGER
 SG_ BMU_M21_V10 : 16|16@1+ (1,0) [0|65535] "mV" LOGGER
 SG_ BMU_M21_V11 : 32|16@1+ (1,0) [0|65535] "mV" LOGGER
 SG_ BMU_M21_VAge3 : 48|16@1+ (1,0) [0|65535] "ms" LOGGER

BO_ 2284094800 BMU_TransmitTemperature_N_21_P_0: 8 BMU
 SG_ BMU_M21_T00 : 0|8@1+ (1,0) [0|255] "degC" ECU,LOGGER
 SG_ BMU_M21_T01 : 8|8@1+ (1,0) [0|255] "degC" ECU,LOGGER
 SG_ BMU_M21_T02 : 16|8@1+ (1,0) [0|255] "degC" ECU,LOGGER
 SG_ BMU_M21_T03 : 24|8@1+ (1,0) [0|255] "degC" ECU,LOGGER
 SG_ BMU_M21_T04 : 32|8@1+ (1,0) [0|255] "degC" ECU,LOGGER
 SG_ BMU_M21_T05 : 40|8@1+ (1,0) [0|255] "degC" ECU,LOGGER
 SG_ BMU_M21_TAge0 : 48|16@1+ (1,0) [0|65535] "ms" ECU,LOGGER

BO_ 2284094801 BMU_TransmitTemperature_N_21_P_1: 8 BMU
 SG_ BMU_M21_T06 : 0|8@1+ (1,0) [0|255] "degC" ECU,LOGGER
 SG_ BMU_M21_T07 : 8|8@1+ (1,0) [0|255] "degC" ECU,LOGGER
 SG_ BMU_M21_T08 : 16|8@1+ (1,0) [0|255] "degC" ECU,LOGGER
 SG_ BMU_M21_T09 : 24|8@1+ (1,0) [0|255] "degC" ECU,LOGGER
 SG_ BMU_M21_T10 : 32|8@1+ (1,0) [0|255] "degC" ECU,LOGGER
 SG_ BMU_M21_T11 : 40|8@1+ (1,0) [0|255] "degC" ECU,LOGGER
 SG_ BMU_M21_TAge1 : 48|16@1+ (1,0) [0|65535] "ms" ECU,LOGGER

BO_ 2284095824 BMU_TransmitBalancing_N_21: 8 BMU
 SG_ BMU_M21_Balance : 0|16@1+ (1,0) [0|65535] "" LOGGER
 SG_ BMU_M21_DieTemp : 16|8@1+ (1,0) [0|255] "degC" LOGGER

BO_ 2284093792 BMU_TransmitVoltage_N_22_P_0: 8 BMU
 SG_ BMU_M22_V00 : 0|16@1+ (1,0) [0|65535] "mV" LOGGER
 SG_ BMU_M22_V01 : 16|16@1+ (1,0) [0|65535] "mV" LOGGER
 SG_ BMU_M22_V02 : 32|16@1+ (1,0) [0|65535] "mV" LOGGER
 SG_ BMU_M22_VAge0 : 48|16@1+ (1,0) [0|65535] "ms" LOGGER

BO_ 2284093793 BMU_TransmitVoltage_N_22_P_1: 8 BMU
 SG_ BMU_M22_V03 : 0|16@1+ (1,0) [0|65535] "mV" LOGGER
 SG_ BMU_M22_V04 : 16|16@1+ (1,0) [0|65535] "mV" LOGGER
 SG_ BMU_M22_V05 : 32|16@1+ (1,0) [0|65535] "mV" LOGGER
 SG_ BMU_M22_VAge1 : 48|16@1+ (1,0) [0|65535] "ms" LOGGER

BO_ 2284093794 BMU_TransmitVoltage_N_22_P_2: 8 BMU
 SG_ BMU_M22_V06 : 0|16@1+ (1,0) [0|65535] "mV" LOGGER
 SG_ BMU_M22_V07 : 16|16@1+ (1,0) [0|65535] "mV" LOGGER
 SG_ BMU_M22_V08 : 32|16@1+ (1,0) [0|65535] "mV" LOGGER
 SG_ BMU_M22_VAge2 : 48|16@1+ (1,0) [0|65535] "ms" LOGGER

BO_ 2284093795 BMU_TransmitVoltage_N_22_P_3: 8 BMU
 SG_ BMU_M22_V09 : 0|16@1+ (1,0) [0|65535] "mV" LOGGER
 SG_ BMU_M22_V10 : 16|16@1+ (1,0) [0|65535] "mV" LOGGER
 SG_ BMU_M22_V11 : 32|16@1+ (1,0) [0|65535] "mV" LOGGER
 SG_ BMU_M22_VAge3 : 48|16@1+ (1,0) [0|65535] "ms" LOGGER

BO_ 2284094816 BMU_TransmitTemperature_N_22_P_0: 8 BMU
 SG_ BMU_M22_T00 : 0|8@1+ (1,0) [0|255] "degC" ECU,LOGGER
 SG_ BMU_M22_T01 : 8|8@1+ (1,0) [0|255] "degC" ECU,LOGGER
 SG_ BMU_M22_T02 : 16|8@1+ (1,0) [0|255] "degC" ECU,LOGGER
 SG_ BMU_M22_T03 : 24|8@1+ (1,0) [0|255] "degC" ECU,LOGGER
 SG_ BMU_M22_T04 : 32|8@1+ (1,0) [0|255] "degC" ECU,LOGGER
 SG_ BMU_M22_T05 : 40|8@1+ (1,0) [0|255] "degC" ECU,LOGGER
 SG_ BMU_M22_TAge0 : 48|16@1+ (1,0) [0|65535] "ms" ECU,LOGGER

BO_ 2284094817 BMU_TransmitTemperature_N_22_P_1: 8 BMU
 SG_ BMU_M22_T06 : 0|8@1+ (1,0) [0|255] "degC" ECU,LOGGER
 SG_ BMU_M22_T07 : 8|8@1+ (1,0) [0|255] "degC" ECU,LOGGER
 SG_ BMU_M22_T08 : 16|8@1+ (1,0) [0|255] "degC" ECU,LOGGER
 SG_ BMU_M22_T09 : 24|8@1+ (1,0) [0|255] "degC" ECU,LOGGER
 SG_ BMU_M22_T10 : 32|8@1+ (1,0) [0|255] "degC" ECU,LOGGER
 SG_ BMU_M22_T11 : 40|8@1+ (1,0) [0|255] "degC" ECU,LOGGER
 SG_ BMU_M22_TAge1 : 48|16@1+ (1,0) [0|65535] "ms" ECU,LOGGER

BO_ 2284095840 BMU_TransmitBalancing_N_22: 8 BMU
 SG_ BMU_M22_Balance : 0|16@1+ (1,0) [0|65535] "" LOGGER
 SG_ BMU_M22_DieTemp : 16|8@1+ (1,0) [0|255] "degC" LOGGER

BO_ 2284093808 BMU_TransmitVoltage_N_23_P_0: 8 BMU
 SG_ BMU_M23_V00 : 0|16@1+ (1,0) [0|65535] "mV" LOGGER
 SG_ BMU_M23_V01 : 16|16@1+ (1,0) [0|65535] "mV" LOGGER
 SG_ BMU_M23_V02 : 32|16@1+ (1,0) [0|65535] "mV" LOGGER
 SG_ BMU_M23_VAge0 : 48|16@1+ (1,0) [0|65535] "ms" LOGGER

BO_ 2284093809 BMU_TransmitVoltage_N_23_P_1: 8 BMU
 SG_ BMU_M23_V03 : 0|16@1+ (1,0) [0|65535] "mV" LOGGER
 SG_ BMU_M23_V04 : 16|16@1+ (1,0) [0|65535] "mV" LOGGER
 SG_ BMU_M23_V05 : 32|16@1+ (1,0) [0|65535] "mV" LOGGER
 SG_ BMU_M23_VAge1 : 48|16@1+ (1,0) [0|65535] "ms" LOGGER

BO_ 2284093810 BMU_TransmitVoltage_N_23_P_2: 8 BMU
 SG_ BMU_M23_V06 : 0|16@1+ (1,0) [0|65535] "mV" LOGGER
 SG_ BMU_M23_V07 : 16|16@1+ (1,0) [0|65535] "mV" LOGGER
 SG_ BMU_M23_V08 : 32|16@1+ (1,0) [0|65535] "mV" LOGGER
 SG_ BMU_M23_VAge2 : 48|16@1+ (1,0) [0|65535] "ms" LOGGER

BO_ 2284093811 BMU_TransmitVoltage_N_23_P_3: 8 BMU
 SG_ BMU_M23_V09 : 0|16@1+ (1,0) [0|65535] "mV" LOGGER
 SG_ BMU_M23_V10 : 16|16@1+ (1,0) [0|65535] "mV" LOGGER
 SG_ BMU_M23_V11 : 32|16@1+ (1,0) [0|65535] "mV" LOGGER
 SG_ BMU_M23_VAge3 : 48|16@1+ (1,0) [0|65535] "ms" LOGGER

BO_ 2284094832 BMU_TransmitTemperature_N_23_P_0: 8 BMU
 SG_ BMU_M23_T00 : 0|8@1+ (1,0) [0|255] "degC" ECU,LOGGER
 SG_ BMU_M23_T01 : 8|8@1+ (1,0) [0|255] "degC" ECU,LOGGER
 SG_ BMU_M23_T02 : 16|8@1+ (1,0) [0|255] "degC" ECU,LOGGER
 SG_ BMU_M23_T03 : 24|8@1+ (1,0) [0|255] "degC" ECU,LOGGER
 SG_ BMU_M23_T04 : 32|8@1+ (1,0) [0|255] "degC" ECU,LOGGER
 SG_ BMU_M23_T05 : 40|8@1+ (1,0) [0|255] "degC" ECU,LOGGER
 SG_ BMU_M23_TAge0 : 48|16@1+ (1,0) [0|65535] "ms" ECU,LOGGER

BO_ 2284094833 BMU_TransmitTemperature_N_23_P_1: 8 BMU
 SG_ BMU_M23_T06 : 0|8@1+ (1,0) [0|255] "degC" ECU,LOGGER
 SG_ BMU_M23_T07 : 8|8@1+ (1,0) [0|255] "degC" ECU,LOGGER
 SG_ BMU_M23_T08 : 16|8@1+ (1,0) [0|255] "degC" ECU,LOGGER
 SG_ BMU_M23_T09 : 24|8@1+ (1,0) [0|255] "degC" ECU,LOGGER
 SG_ BMU_M23_T10 : 32|8@1+ (1,0) [0|255] "degC" ECU,LOGGER
 SG_ BMU_M23_T11 : 40|8@1+ (1,0) [0|255] "degC" ECU,LOGGER
 SG_ BMU_M23_TAge1 : 48|16@1+ (1,0) [0|65535] "ms" ECU,LOGGER

BO_ 2284095856 BMU_TransmitBalancing_N_23: 8 BMU
 SG_ BMU_M23_Balance : 0|16@1+ (1,0) [0|65535] "" LOGGER
 SG_ BMU_M23_DieTemp : 16|8@1+ (1,0) [0|255] "degC" LOGGER

BO_ 2416443392 BMU_TRANSMIT_VOLTAGE_N0_P0: 8 BMU
 SG_ BMU_M00_V00 : 0|16@1+ (1,0) [0|65535] "mV" LOGGER
 SG_ BMU_M00_V01 : 16|16@1+ (1,0) [0|65535] "mV" LOGGER
 SG_ BMU_M00_V02 : 32|16@1+ (1,0) [0|65535] "mV" LOGGER
 SG_ BMU_M00_VAge0 : 48|16@1+ (1,0) [0|65535] "ms" LOGGER

BO_ 2416443393 BMU_TRANSMIT_VOLTAGE_N0_P1: 8 BMU
 SG_ BMU_M00_V03 : 0|16@1+ (1,0) [0|65535] "mV" LOGGER
 SG_ BMU_M00_V04 : 16|16@1+ (1,0) [0|65535] "mV" LOGGER
 SG_ BMU_M00_V05 : 32|16@1+ (1,0) [0|65535] "mV" LOGGER
 SG_ BMU_M00_VAge1 : 48|16@1+ (1,0) [0|65535] "ms" LOGGER

BO_ 2416443394 BMU_TRANSMIT_VOLTAGE_N0_P2: 8 BMU
 SG_ BMU_M00_V06 : 0|16@1+ (1,0) [0|65535] "mV" LOGGER
 SG_ BMU_M00_V07 : 16|16@1+ (1,0) [0|65535] "mV" LOGGER
 SG_ BMU_M00_V08 : 32|16@1+ (1,0) [0|65535] "mV" LOGGER
 SG_ BMU_M00_VAge2 : 48|16@1+ (1,0) [0|65535] "ms" LOGGER

BO_ 2416443395 BMU_TRANSMIT_VOLTAGE_N0_P3: 8 BMU
 SG_ BMU_M00_V09 : 0|16@1+ (1,0) [0|65535] "mV" LOGGER
 SG_ BMU_M00_V10 : 16|16@1+ (1,0) [0|65535] "mV" LOGGER
 SG_ BMU_M00_V11 : 32|16@1+ (1,0) [0|65535] "mV" LOGGER
 SG_ BMU_M00_VAge3 : 48|16@1+ (1,0) [0|65535] "ms" LOGGER

BO_ 2416444416 BMU_TRANSMIT_TEMPERATURE_N0_P0: 8 BMU
 SG_ BMU_M00_T00 : 0|8@1+ (1,0) [0|255] "degC" LOGGER
 SG_ BMU_M00_T01 : 8|8@1+ (1,0) [0|255] "degC" LOGGER
 SG_ BMU_M00_T02 : 16|8@1+ (1,0) [0|255] "degC" LOGGER
 SG_ BMU_M00_T03 : 24|8@1+ (1,0) [0|255] "degC" LOGGER
 SG_ BMU_M00_T04 : 32|8@1+ (1,0) [0|255] "degC" LOGGER
 SG_ BMU_M00_T05 : 40|8@1+ (1,0) [0|255] "degC" LOGGER
 SG_ BMU_M00_TAge0 : 48|16@1+ (1,0) [0|65535] "ms" LOGGER

BO_ 2416444417 BMU_TRANSMIT_TEMPERATURE_N0_P1: 8 BMU
 SG_ BMU_M00_T06 : 0|8@1+ (1,0) [0|255] "degC" LOGGER
 SG_ BMU_M00_T07 : 8|8@1+ (1,0) [0|255] "degC" LOGGER
 SG_ BMU_M00_T08 : 16|8@1+ (1,0) [0|255] "degC" LOGGER
 SG_ BMU_M00_T09 : 24|8@1+ (1,0) [0|255] "degC" LOGGER
 SG_ BMU_M00_T10 : 32|8@1+ (1,0) [0|255] "degC" LOGGER
 SG_ BMU_M00_T11 : 40|8@1+ (1,0) [0|255] "degC" LOGGER
 SG_ BMU_M00_TAge1 : 48|16@1+ (1,0) [0|65535] "ms" LOGGER

BO_ 2416445440 BMU_TRANSMIT_BALANCING_N0: 8 BMU
 SG_ BMU_M00_Balance : 0|16@1+ (1,0) [0|65535] "" LOGGER
 SG_ BMU_M00_DieTemp : 16|8@1+ (1,0) [0|255] "degC" LOGGER

BO_ 2416443408 BMU_TRANSMIT_VOLTAGE_N1_P0: 8 BMU
 SG_ BMU_M01_V00 : 0|16@1+ (1,0) [0|65535] "mV" LOGGER
 SG_ BMU_M01_V01 : 16|16@1+ (1,0) [0|65535] "mV" LOGGER
 SG_ BMU_M01_V02 : 32|16@1+ (1,0) [0|65535] "mV" LOGGER
 SG_ BMU_M01_VAge0 : 48|16@1+ (1,0) [0|65535] "ms" LOGGER

BO_ 2416443409 BMU_TRANSMIT_VOLTAGE_N1_P1: 8 BMU
 SG_ BMU_M01_V03 : 0|16@1+ (1,0) [0|65535] "mV" LOGGER
 SG_ BMU_M01_V04 : 16|16@1+ (1,0) [0|65535] "mV" LOGGER
 SG_ BMU_M01_V05 : 32|16@1+ (1,0) [0|65535] "mV" LOGGER
 SG_ BMU_M01_VAge1 : 48|16@1+ (1,0) [0|65535] "ms" LOGGER

BO_ 2416443410 BMU_TRANSMIT_VOLTAGE_N1_P2: 8 BMU
 SG_ BMU_M01_V06 : 0|16@1+ (1,0) [0|65535] "mV" LOGGER
 SG_ BMU_M01_V07 : 16|16@1+ (1,0) [0|65535] "mV" LOGGER
 SG_ BMU_M01_V08 : 32|16@1+ (1,0) [0|65535] "mV" LOGGER
 SG_ BMU_M01_VAge2 : 48|16@1+ (1,0) [0|65535] "ms" LOGGER

BO_ 2416443411 BMU_TRANSMIT_VOLTAGE_N1_P3: 8 BMU
 SG_ BMU_M01_V09 : 0|16@1+ (1,0) [0|65535] "mV" LOGGER
 SG_ BMU_M01_V10 : 16|16@1+ (1,0) [0|65535] "mV" LOGGER
 SG_ BMU_M01_V11 : 32|16@1+ (1,0) [0|65535] "mV" LOGGER
 SG_ BMU_M01_VAge3 : 48|16@1+ (1,0) [0|65535] "ms" LOGGER

BO_ 2416444432 BMU_TRANSMIT_TEMPERATURE_N1_P0: 8 BMU
 SG_ BMU_M01_T00 : 0|8@1+ (1,0) [0|255] "degC" LOGGER
 SG_ BMU_M01_T01 : 8|8@1+ (1,0) [0|255] "degC" LOGGER
 SG_ BMU_M01_T02 : 16|8@1+ (1,0) [0|255] "degC" LOGGER
 SG_ BMU_M01_T03 : 24|8@1+ (1,0) [0|255] "degC" LOGGER
 SG_ BMU_M01_T04 : 32|8@1+ (1,0) [0|255] "degC" LOGGER
 SG_ BMU_M01_T05 : 40|8@1+ (1,0) [0|255] "degC" LOGGER
 SG_ BMU_M01_TAge0 : 48|16@1+ (1,0) [0|65535] "ms" LOGGER

BO_ 2416444433 BMU_TRANSMIT_TEMPERATURE_N1_P1: 8 BMU
 SG_ BMU_M01_T06 : 0|8@1+ (1,0) [0|255] "degC" LOGGER
 SG_ BMU_M01_T07 : 8|8@1+ (1,0) [0|255] "degC" LOGGER
 SG_ BMU_M01_T08 : 16|8@1+ (1,0) [0|255] "degC" LOGGER
 SG_ BMU_M01_T09 : 24|8@1+ (1,0) [0|255] "degC" LOGGER
 SG_ BMU_M01_T10 : 32|8@1+ (1,0) [0|255] "degC" LOGGER
 SG_ BMU_M01_T11 : 40|8@1+ (1,0) [0|255] "degC" LOGGER
 SG_ BMU_M01_TAge1 : 48|16@1+ (1,0) [0|65535] "ms" LOGGER

BO_ 2416445456 BMU_TRANSMIT_BALANCING_N1: 8 BMU
 SG_ BMU_M01_Balance : 0|16@1+ (1,0) [0|65535] "" LOGGER
 SG_ BMU_M01_DieTemp : 16|8@1+ (1,0) [0|255] "degC" LOGGER

BO_ 2416443424 BMU_TRANSMIT_VOLTAGE_N2_P0: 8 BMU
 SG_ BMU_M02_V00 : 0|16@1+ (1,0) [0|65535] "mV" LOGGER
 SG_ BMU_M02_V01 : 16|16@1+ (1,0) [0|65535] "mV" LOGGER
 SG_ BMU_M02_V02 : 32|16@1+ (1,0) [0|65535] "mV" LOGGER
 SG_ BMU_M02_VAge0 : 48|16@1+ (1,0) [0|65535] "ms" LOGGER

BO_ 2416443425 BMU_TRANSMIT_VOLTAGE_N2_P1: 8 BMU
 SG_ BMU_M02_V03 : 0|16@1+ (1,0) [0|65535] "mV" LOGGER
 SG_ BMU_M02_V04 : 16|16@1+ (1,0) [0|65535] "mV" LOGGER
 SG_ BMU_M02_V05 : 32|16@1+ (1,0) [0|65535] "mV" LOGGER
 SG_ BMU_M02_VAge1 : 48|16@1+ (1,0) [0|65535] "ms" LOGGER

BO_ 2416443426 BMU_TRANSMIT_VOLTAGE_N2_P2: 8 BMU
 SG_ BMU_M02_V06 : 0|16@1+ (1,0) [0|65535] "mV" LOGGER
 SG_ BMU_M02_V07 : 16|16@1+ (1,0) [0|65535] "mV" LOGGER
 SG_ BMU_M02_V08 : 32|16@1+ (1,0) [0|65535] "mV" LOGGER
 SG_ BMU_M02_VAge2 : 48|16@1+ (1,0) [0|65535] "ms" LOGGER

BO_ 2416443427 BMU_TRANSMIT_VOLTAGE_N2_P3: 8 BMU
 SG_ BMU_M02_V09 : 0|16@1+ (1,0) [0|65535] "mV" LOGGER
 SG_ BMU_M02_V10 : 16|16@1+ (1,0) [0|65535] "mV" LOGGER
 SG_ BMU_M02_V11 : 32|16@1+ (1,0) [0|65535] "mV" LOGGER
 SG_ BMU_M02_VAge3 : 48|16@1+ (1,0) [0|65535] "ms" LOGGER

BO_ 2416444448 BMU_TRANSMIT_TEMPERATURE_N2_P0: 8 BMU
 SG_ BMU_M02_T00 : 0|8@1+ (1,0) [0|255] "degC" LOGGER
 SG_ BMU_M02_T01 : 8|8@1+ (1,0) [0|255] "degC" LOGGER
 SG_ BMU_M02_T02 : 16|8@1+ (1,0) [0|255] "degC" LOGGER
 SG_ BMU_M02_T03 : 24|8@1+ (1,0) [0|255] "degC" LOGGER
 SG_ BMU_M02_T04 : 32|8@1+ (1,0) [0|255] "degC" LOGGER
 SG_ BMU_M02_T05 : 40|8@1+ (1,0) [0|255] "degC" LOGGER
 SG_ BMU_M02_TAge0 : 48|16@1+ (1,0) [0|65535] "ms" LOGGER

BO_ 2416444449 BMU_TRANSMIT_TEMPERATURE_N2_P1: 8 BMU
 SG_ BMU_M02_T06 : 0|8@1+ (1,0) [0|255] "degC" LOGGER
 SG_ BMU_M02_T07 : 8|8@1+ (1,0) [0|255] "degC" LOGGER
 SG_ BMU_M02_T08 : 16|8@1+ (1,0) [0|255] "degC" LOGGER
 SG_ BMU_M02_T09 : 24|8@1+ (1,0) [0|255] "degC" LOGGER
 SG_ BMU_M02_T10 : 32|8@1+ (1,0) [0|255] "degC" LOGGER
 SG_ BMU_M02_T11 : 40|8@1+ (1,0) [0|255] "degC" LOGGER
 SG_ BMU_M02_TAge1 : 48|16@1+ (1,0) [0|65535] "ms" LOGGER

BO_ 2416445472 BMU_TRANSMIT_BALANCING_N2: 8 BMU
 SG_ BMU_M02_Balance : 0|16@1+ (1,0) [0|65535] "" LOGGER
 SG_ BMU_M02_DieTemp : 16|8@1+ (1,0) [0|255] "degC" LOGGER

BO_ 2416443440 BMU_TRANSMIT_VOLTAGE_N3_P0: 8 BMU
 SG_ BMU_M03_V00 : 0|16@1+ (1,0) [0|65535] "mV" LOGGER
 SG_ BMU_M03_V01 : 16|16@1+ (1,0) [0|65535] "mV" LOGGER
 SG_ BMU_M03_V02 : 32|16@1+ (1,0) [0|65535] "mV" LOGGER
 SG_ BMU_M03_VAge0 : 48|16@1+ (1,0) [0|65535] "ms" LOGGER

BO_ 2416443441 BMU_TRANSMIT_VOLTAGE_N3_P1: 8 BMU
 SG_ BMU_M03_V03 : 0|16@1+ (1,0) [0|65535] "mV" LOGGER
 SG_ BMU_M03_V04 : 16|16@1+ (1,0) [0|65535] "mV" LOGGER
 SG_ BMU_M03_V05 : 32|16@1+ (1,0) [0|65535] "mV" LOGGER
 SG_ BMU_M03_VAge1 : 48|16@1+ (1,0) [0|65535] "ms" LOGGER

BO_ 2416443442 BMU_TRANSMIT_VOLTAGE_N3_P2: 8 BMU
 SG_ BMU_M03_V06 : 0|16@1+ (1,0) [0|65535] "mV" LOGGER
 SG_ BMU_M03_V07 : 16|16@1+ (1,0) [0|65535] "mV" LOGGER
 SG_ BMU_M03_V08 : 32|16@1+ (1,0) [0|65535] "mV" LOGGER
 SG_ BMU_M03_VAge2 : 48|16@1+ (1,0) [0|65535] "ms" LOGGER

BO_ 2416443443 BMU_TRANSMIT_VOLTAGE_N3_P3: 8 BMU
 SG_ BMU_M03_V09 : 0|16@1+ (1,0) [0|65535] "mV" LOGGER
 SG_ BMU_M03_V10 : 16|16@1+ (1,0) [0|65535] "mV" LOGGER
 SG_ BMU_M03_V11 : 32|16@1+ (1,0) [0|65535] "mV" LOGGER
 SG_ BMU_M03_VAge3 : 48|16@1+ (1,0) [0|65535] "ms" LOGGER

BO_ 2416444464 BMU_TRANSMIT_TEMPERATURE_N3_P0: 8 BMU
 SG_ BMU_M03_T00 : 0|8@1+ (1,0) [0|255] "degC" LOGGER
 SG_ BMU_M03_T01 : 8|8@1+ (1,0) [0|255] "degC" LOGGER
 SG_ BMU_M03_T02 : 16|8@1+ (1,0) [0|255] "degC" LOGGER
 SG_ BMU_M03_T03 : 24|8@1+ (1,0) [0|255] "degC" LOGGER
 SG_ BMU_M03_T04 : 32|8@1+ (1,0) [0|255] "degC" LOGGER
 SG_ BMU_M03_T05 : 40|8@1+ (1,0) [0|255] "degC" LOGGER
 SG_ BMU_M03_TAge0 : 48|16@1+ (1,0) [0|65535] "ms" LOGGER

BO_ 2416444465 BMU_TRANSMIT_TEMPERATURE_N3_P1: 8 BMU
 SG_ BMU_M03_T06 : 0|8@1+ (1,0) [0|255] "degC" LOGGER
 SG_ BMU_M03_T07 : 8|8@1+ (1,0) [0|255] "degC" LOGGER
 SG_ BMU_M03_T08 : 16|8@1+ (1,0) [0|255] "degC" LOGGER
 SG_ BMU_M03_T09 : 24|8@1+ (1,0) [0|255] "degC" LOGGER
 SG_ BMU_M03_T10 : 32|8@1+ (1,0) [0|255] "degC" LOGGER
 SG_ BMU_M03_T11 : 40|8@1+ (1,0) [0|255] "degC" LOGGER
 SG_ BMU_M03_TAge1 : 48|16@1+ (1,0) [0|65535] "ms" LOGGER

BO_ 2416445488 BMU_TRANSMIT_BALANCING_N3: 8 BMU
 SG_ BMU_M03_Balance : 0|16@1+ (1,0) [0|65535] "" LOGGER
 SG_ BMU_M03_DieTemp : 16|8@1+ (1,0) [0|255] "degC" LOGGER

BO_ 2416443456 BMU_TRANSMIT_VOLTAGE_N4_P0: 8 BMU
 SG_ BMU_M04_V00 : 0|16@1+ (1,0) [0|65535] "mV" LOGGER
 SG_ BMU_M04_V01 : 16|16@1+ (1,0) [0|65535] "mV" LOGGER
 SG_ BMU_M04_V02 : 32|16@1+ (1,0) [0|65535] "mV" LOGGER
 SG_ BMU_M04_VAge0 : 48|16@1+ (1,0) [0|65535] "ms" LOGGER

BO_ 2416443457 BMU_TRANSMIT_VOLTAGE_N4_P1: 8 BMU
 SG_ BMU_M04_V03 : 0|16@1+ (1,0) [0|65535] "mV" LOGGER
 SG_ BMU_M04_V04 : 16|16@1+ (1,0) [0|65535] "mV" LOGGER
 SG_ BMU_M04_V05 : 32|16@1+ (1,0) [0|65535] "mV" LOGGER
 SG_ BMU_M04_VAge1 : 48|16@1+ (1,0) [0|65535] "ms" LOGGER

BO_ 2416443458 BMU_TRANSMIT_VOLTAGE_N4_P2: 8 BMU
 SG_ BMU_M04_V06 : 0|16@1+ (1,0) [0|65535] "mV" LOGGER
 SG_ BMU_M04_V07 : 16|16@1+ (1,0) [0|65535] "mV" LOGGER
 SG_ BMU_M04_V08 : 32|16@1+ (1,0) [0|65535] "mV" LOGGER
 SG_ BMU_M04_VAge2 : 48|16@1+ (1,0) [0|65535] "ms" LOGGER

BO_ 2416443459 BMU_TRANSMIT_VOLTAGE_N4_P3: 8 BMU
 SG_ BMU_M04_V09 : 0|16@1+ (1,0) [0|65535] "mV" LOGGER
 SG_ BMU_M04_V10 : 16|16@1+ (1,0) [0|65535] "mV" LOGGER
 SG_ BMU_M04_V11 : 32|16@1+ (1,0) [0|65535] "mV" LOGGER
 SG_ BMU_M04_VAge3 : 48|16@1+ (1,0) [0|65535] "ms" LOGGER

BO_ 2416444480 BMU_TRANSMIT_TEMPERATURE_N4_P0: 8 BMU
 SG_ BMU_M04_T00 : 0|8@1+ (1,0) [0|255] "degC" LOGGER
 SG_ BMU_M04_T01 : 8|8@1+ (1,0) [0|255] "degC" LOGGER
 SG_ BMU_M04_T02 : 16|8@1+ (1,0) [0|255] "degC" LOGGER
 SG_ BMU_M04_T03 : 24|8@1+ (1,0) [0|255] "degC" LOGGER
 SG_ BMU_M04_T04 : 32|8@1+ (1,0) [0|255] "degC" LOGGER
 SG_ BMU_M04_T05 : 40|8@1+ (1,0) [0|255] "degC" LOGGER
 SG_ BMU_M04_TAge0 : 48|16@1+ (1,0) [0|65535] "ms" LOGGER

BO_ 2416444481 BMU_TRANSMIT_TEMPERATURE_N4_P1: 8 BMU
 SG_ BMU_M04_T06 : 0|8@1+ (1,0) [0|255] "degC" LOGGER
 SG_ BMU_M04_T07 : 8|8@1+ (1,0) [0|255] "degC" LOGGER
 SG_ BMU_M04_T08 : 16|8@1+ (1,0) [0|255] "degC" LOGGER
 SG_ BMU_M04_T09 : 24|8@1+ (1,0) [0|255] "degC" LOGGER
 SG_ BMU_M04_T10 : 32|8@1+ (1,0) [0|255] "degC" LOGGER
 SG_ BMU_M04_T11 : 40|8@1+ (1,0) [0|255] "degC" LOGGER
 SG_ BMU_M04_TAge1 : 48|16@1+ (1,0) [0|65535] "ms" LOGGER

BO_ 2416445504 BMU_TRANSMIT_BALANCING_N4: 8 BMU
 SG_ BMU_M04_Balance : 0|16@1+ (1,0) [0|65535] "" LOGGER
 SG_ BMU_M04_DieTemp : 16|8@1+ (1,0) [0|255] "degC" LOGGER

BO_ 2416443472 BMU_TRANSMIT_VOLTAGE_N5_P0: 8 BMU
 SG_ BMU_M05_V00 : 0|16@1+ (1,0) [0|65535] "mV" LOGGER
 SG_ BMU_M05_V01 : 16|16@1+ (1,0) [0|65535] "mV" LOGGER
 SG_ BMU_M05_V02 : 32|16@1+ (1,0) [0|65535] "mV" LOGGER
 SG_ BMU_M05_VAge0 : 48|16@1+ (1,0) [0|65535] "ms" LOGGER

BO_ 2416443473 BMU_TRANSMIT_VOLTAGE_N5_P1: 8 BMU
 SG_ BMU_M05_V03 : 0|16@1+ (1,0) [0|65535] "mV" LOGGER
 SG_ BMU_M05_V04 : 16|16@1+ (1,0) [0|65535] "mV" LOGGER
 SG_ BMU_M05_V05 : 32|16@1+ (1,0) [0|65535] "mV" LOGGER
 SG_ BMU_M05_VAge1 : 48|16@1+ (1,0) [0|65535] "ms" LOGGER

BO_ 2416443474 BMU_TRANSMIT_VOLTAGE_N5_P2: 8 BMU
 SG_ BMU_M05_V06 : 0|16@1+ (1,0) [0|65535] "mV" LOGGER
 SG_ BMU_M05_V07 : 16|16@1+ (1,0) [0|65535] "mV" LOGGER
 SG_ BMU_M05_V08 : 32|16@1+ (1,0) [0|65535] "mV" LOGGER
 SG_ BMU_M05_VAge2 : 48|16@1+ (1,0) [0|65535] "ms" LOGGER

BO_ 2416443475 BMU_TRANSMIT_VOLTAGE_N5_P3: 8 BMU
 SG_ BMU_M05_V09 : 0|16@1+ (1,0) [0|65535] "mV" LOGGER
 SG_ BMU_M05_V10 : 16|16@1+ (1,0) [0|65535] "mV" LOGGER
 SG_ BMU_M05_V11 : 32|16@1+ (1,0) [0|65535] "mV" LOGGER
 SG_ BMU_M05_VAge3 : 48|16@1+ (1,0) [0|65535] "ms" LOGGER

BO_ 2416444496 BMU_TRANSMIT_TEMPERATURE_N5_P0: 8 BMU
 SG_ BMU_M05_T00 : 0|8@1+ (1,0) [0|255] "degC" LOGGER
 SG_ BMU_M05_T01 : 8|8@1+ (1,0) [0|255] "degC" LOGGER
 SG_ BMU_M05_T02 : 16|8@1+ (1,0) [0|255] "degC" LOGGER
 SG_ BMU_M05_T03 : 24|8@1+ (1,0) [0|255] "degC" LOGGER
 SG_ BMU_M05_T04 : 32|8@1+ (1,0) [0|255] "degC" LOGGER
 SG_ BMU_M05_T05 : 40|8@1+ (1,0) [0|255] "degC" LOGGER
 SG_ BMU_M05_TAge0 : 48|16@1+ (1,0) [0|65535] "ms" LOGGER

BO_ 2416444497 BMU_TRANSMIT_TEMPERATURE_N5_P1: 8 BMU
 SG_ BMU_M05_T06 : 0|8@1+ (1,0) [0|255] "degC" LOGGER
 SG_ BMU_M05_T07 : 8|8@1+ (1,0) [0|255] "degC" LOGGER
 SG_ BMU_M05_T08 : 16|8@1+ (1,0) [0|255] "degC" LOGGER
 SG_ BMU_M05_T09 : 24|8@1+ (1,0) [0|255] "degC" LOGGER
 SG_ BMU_M05_T10 : 32|8@1+ (1,0) [0|255] "degC" LOGGER
 SG_ BMU_M05_T11 : 40|8@1+ (1,0) [0|255] "degC" LOGGER
 SG_ BMU_M05_TAge1 : 48|16@1+ (1,0) [0|65535] "ms" LOGGER

BO_ 2416445520 BMU_TRANSMIT_BALANCING_N5: 8 BMU
 SG_ BMU_M05_Balance : 0|16@1+ (1,0) [0|65535] "" LOGGER
 SG_ BMU_M05_DieTemp : 16|8@1+ (1,0) [0|255] "degC" LOGGER

BO_ 2416443488 BMU_TRANSMIT_VOLTAGE_N6_P0: 8 BMU
 SG_ BMU_M06_V00 : 0|16@1+ (1,0) [0|65535] "mV" LOGGER
 SG_ BMU_M06_V01 : 16|16@1+ (1,0) [0|65535] "mV" LOGGER
 SG_ BMU_M06_V02 : 32|16@1+ (1,0) [0|65535] "mV" LOGGER
 SG_ BMU_M06_VAge0 : 48|16@1+ (1,0) [0|65535] "ms" LOGGER

BO_ 2416443489 BMU_TRANSMIT_VOLTAGE_N6_P1: 8 BMU
 SG_ BMU_M06_V03 : 0|16@1+ (1,0) [0|65535] "mV" LOGGER
 SG_ BMU_M06_V04 : 16|16@1+ (1,0) [0|65535] "mV" LOGGER
 SG_ BMU_M06_V05 : 32|16@1+ (1,0) [0|65535] "mV" LOGGER
 SG_ BMU_M06_VAge1 : 48|16@1+ (1,0) [0|65535] "ms" LOGGER

BO_ 2416443490 BMU_TRANSMIT_VOLTAGE_N6_P2: 8 BMU
 SG_ BMU_M06_V06 : 0|16@1+ (1,0) [0|65535] "mV" LOGGER
 SG_ BMU_M06_V07 : 16|16@1+ (1,0) [0|65535] "mV" LOGGER
 SG_ BMU_M06_V08 : 32|16@1+ (1,0) [0|65535] "mV" LOGGER
 SG_ BMU_M06_VAge2 : 48|16@1+ (1,0) [0|65535] "ms" LOGGER

BO_ 2416443491 BMU_TRANSMIT_VOLTAGE_N6_P3: 8 BMU
 SG_ BMU_M06_V09 : 0|16@1+ (1,0) [0|65535] "mV" LOGGER
 SG_ BMU_M06_V10 : 16|16@1+ (1,0) [0|65535] "mV" LOGGER
 SG_ BMU_M06_V11 : 32|16@1+ (1,0) [0|65535] "mV" LOGGER
 SG_ BMU_M06_VAge3 : 48|16@1+ (1,0) [0|65535] "ms" LOGGER

BO_ 2416444512 BMU_TRANSMIT_TEMPERATURE_N6_P0: 8 BMU
 SG_ BMU_M06_T00 : 0|8@1+ (1,0) [0|255] "degC" LOGGER
 SG_ BMU_M06_T01 : 8|8@1+ (1,0) [0|255] "degC" LOGGER
 SG_ BMU_M06_T02 : 16|8@1+ (1,0) [0|255] "degC" LOGGER
 SG_ BMU_M06_T03 : 24|8@1+ (1,0) [0|255] "degC" LOGGER
 SG_ BMU_M06_T04 : 32|8@1+ (1,0) [0|255] "degC" LOGGER
 SG_ BMU_M06_T05 : 40|8@1+ (1,0) [0|255] "degC" LOGGER
 SG_ BMU_M06_TAge0 : 48|16@1+ (1,0) [0|65535] "ms" LOGGER

BO_ 2416444513 BMU_TRANSMIT_TEMPERATURE_N6_P1: 8 BMU
 SG_ BMU_M06_T06 : 0|8@1+ (1,0) [0|255] "degC" LOGGER
 SG_ BMU_M06_T07 : 8|8@1+ (1,0) [0|255] "degC" LOGGER
 SG_ BMU_M06_T08 : 16|8@1+ (1,0) [0|255] "degC" LOGGER
 SG_ BMU_M06_T09 : 24|8@1+ (1,0) [0|255] "degC" LOGGER
 SG_ BMU_M06_T10 : 32|8@1+ (1,0) [0|255] "degC" LOGGER
 SG_ BMU_M06_T11 : 40|8@1+ (1,0) [0|255] "degC" LOGGER
 SG_ BMU_M06_TAge1 : 48|16@1+ (1,0) [0|65535] "ms" LOGGER

BO_ 2416445536 BMU_TRANSMIT_BALANCING_N6: 8 BMU
 SG_ BMU_M06_Balance : 0|16@1+ (1,0) [0|65535] "" LOGGER
 SG_ BMU_M06_DieTemp : 16|8@1+ (1,0) [0|255] "degC" LOGGER

BO_ 2416443504 BMU_TRANSMIT_VOLTAGE_N7_P0: 8 BMU
 SG_ BMU_M07_V00 : 0|16@1+ (1,0) [0|65535] "mV" LOGGER
 SG_ BMU_M07_V01 : 16|16@1+ (1,0) [0|65535] "mV" LOGGER
 SG_ BMU_M07_V02 : 32|16@1+ (1,0) [0|65535] "mV" LOGGER
 SG_ BMU_M07_VAge0 : 48|16@1+ (1,0) [0|65535] "ms" LOGGER

BO_ 2416443505 BMU_TRANSMIT_VOLTAGE_N7_P1: 8 BMU
 SG_ BMU_M07_V03 : 0|16@1+ (1,0) [0|65535] "mV" LOGGER
 SG_ BMU_M07_V04 : 16|16@1+ (1,0) [0|65535] "mV" LOGGER
 SG_ BMU_M07_V05 : 32|16@1+ (1,0) [0|65535] "mV" LOGGER
 SG_ BMU_M07_VAge1 : 48|16@1+ (1,0) [0|65535] "ms" LOGGER

BO_ 2416443506 BMU_TRANSMIT_VOLTAGE_N7_P2: 8 BMU
 SG_ BMU_M07_V06 : 0|16@1+ (1,0) [0|65535] "mV" LOGGER
 SG_ BMU_M07_V07 : 16|16@1+ (1,0) [0|65535] "mV" LOGGER
 SG_ BMU_M07_V08 : 32|16@1+ (1,0) [0|65535] "mV" LOGGER
 SG_ BMU_M07_VAge2 : 48|16@1+ (1,0) [0|65535] "ms" LOGGER

BO_ 2416443507 BMU_TRANSMIT_VOLTAGE_N7_P3: 8 BMU
 SG_ BMU_M07_V09 : 0|16@1+ (1,0) [0|65535] "mV" LOGGER
 SG_ BMU_M07_V10 : 16|16@1+ (1,0) [0|65535] "mV" LOGGER
 SG_ BMU_M07_V11 : 32|16@1+ (1,0) [0|65535] "mV" LOGGER
 SG_ BMU_M07_VAge3 : 48|16@1+ (1,0) [0|65535] "ms" LOGGER

BO_ 2416444528 BMU_TRANSMIT_TEMPERATURE_N7_P0: 8 BMU
 SG_ BMU_M07_T00 : 0|8@1+ (1,0) [0|255] "degC" LOGGER
 SG_ BMU_M07_T01 : 8|8@1+ (1,0) [0|255] "degC" LOGGER
 SG_ BMU_M07_T02 : 16|8@1+ (1,0) [0|255] "degC" LOGGER
 SG_ BMU_M07_T03 : 24|8@1+ (1,0) [0|255] "degC" LOGGER
 SG_ BMU_M07_T04 : 32|8@1+ (1,0) [0|255] "degC" LOGGER
 SG_ BMU_M07_T05 : 40|8@1+ (1,0) [0|255] "degC" LOGGER
 SG_ BMU_M07_TAge0 : 48|16@1+ (1,0) [0|65535] "ms" LOGGER

BO_ 2416444529 BMU_TRANSMIT_TEMPERATURE_N7_P1: 8 BMU
 SG_ BMU_M07_T06 : 0|8@1+ (1,0) [0|255] "degC" LOGGER
 SG_ BMU_M07_T07 : 8|8@1+ (1,0) [0|255] "degC" LOGGER
 SG_ BMU_M07_T08 : 16|8@1+ (1,0) [0|255] "degC" LOGGER
 SG_ BMU_M07_T09 : 24|8@1+ (1,0) [0|255] "degC" LOGGER
 SG_ BMU_M07_T10 : 32|8@1+ (1,0) [0|255] "degC" LOGGER
 SG_ BMU_M07_T11 : 40|8@1+ (1,0) [0|255] "degC" LOGGER
 SG_ BMU_M07_TAge1 : 48|16@1+ (1,0) [0|65535] "ms" LOGGER

BO_ 2416445552 BMU_TRANSMIT_BALANCING_N7: 8 BMU
 SG_ BMU_M07_Balance : 0|16@1+ (1,0) [0|65535] "" LOGGER
 SG_ BMU_M07_DieTemp : 16|8@1+ (1,0) [0|255] "degC" LOGGER

BO_ 2416443520 BMU_TRANSMIT_VOLTAGE_N8_P0: 8 BMU
 SG_ BMU_M08_V00 : 0|16@1+ (1,0) [0|65535] "mV" LOGGER
 SG_ BMU_M08_V01 : 16|16@1+ (1,0) [0|65535] "mV" LOGGER
 SG_ BMU_M08_V02 : 32|16@1+ (1,0) [0|65535] "mV" LOGGER
 SG_ BMU_M08_VAge0 : 48|16@1+ (1,0) [0|65535] "ms" LOGGER

BO_ 2416443521 BMU_TRANSMIT_VOLTAGE_N8_P1: 8 BMU
 SG_ BMU_M08_V03 : 0|16@1+ (1,0) [0|65535] "mV" LOGGER
 SG_ BMU_M08_V04 : 16|16@1+ (1,0) [0|65535] "mV" LOGGER
 SG_ BMU_M08_V05 : 32|16@1+ (1,0) [0|65535] "mV" LOGGER
 SG_ BMU_M08_VAge1 : 48|16@1+ (1,0) [0|65535] "ms" LOGGER

BO_ 2416443522 BMU_TRANSMIT_VOLTAGE_N8_P2: 8 BMU
 SG_ BMU_M08_V06 : 0|16@1+ (1,0) [0|65535] "mV" LOGGER
 SG_ BMU_M08_V07 : 16|16@1+ (1,0) [0|65535] "mV" LOGGER
 SG_ BMU_M08_V08 : 32|16@1+ (1,0) [0|65535] "mV" LOGGER
 SG_ BMU_M08_VAge2 : 48|16@1+ (1,0) [0|65535] "ms" LOGGER

BO_ 2416443523 BMU_TRANSMIT_VOLTAGE_N8_P3: 8 BMU
 SG_ BMU_M08_V09 : 0|16@1+ (1,0) [0|65535] "mV" LOGGER
 SG_ BMU_M08_V10 : 16|16@1+ (1,0) [0|65535] "mV" LOGGER
 SG_ BMU_M08_V11 : 32|16@1+ (1,0) [0|65535] "mV" LOGGER
 SG_ BMU_M08_VAge3 : 48|16@1+ (1,0) [0|65535] "ms" LOGGER

BO_ 2416444544 BMU_TRANSMIT_TEMPERATURE_N8_P0: 8 BMU
 SG_ BMU_M08_T00 : 0|8@1+ (1,0) [0|255] "degC" LOGGER
 SG_ BMU_M08_T01 : 8|8@1+ (1,0) [0|255] "degC" LOGGER
 SG_ BMU_M08_T02 : 16|8@1+ (1,0) [0|255] "degC" LOGGER
 SG_ BMU_M08_T03 : 24|8@1+ (1,0) [0|255] "degC" LOGGER
 SG_ BMU_M08_T04 : 32|8@1+ (1,0) [0|255] "degC" LOGGER
 SG_ BMU_M08_T05 : 40|8@1+ (1,0) [0|255] "degC" LOGGER
 SG_ BMU_M08_TAge0 : 48|16@1+ (1,0) [0|65535] "ms" LOGGER

BO_ 2416444545 BMU_TRANSMIT_TEMPERATURE_N8_P1: 8 BMU
 SG_ BMU_M08_T06 : 0|8@1+ (1,0) [0|255] "degC" LOGGER
 SG_ BMU_M08_T07 : 8|8@1+ (1,0) [0|255] "degC" LOGGER
 SG_ BMU_M08_T08 : 16|8@1+ (1,0) [0|255] "degC" LOGGER
 SG_ BMU_M08_T09 : 24|8@1+ (1,0) [0|255] "degC" LOGGER
 SG_ BMU_M08_T10 : 32|8@1+ (1,0) [0|255] "degC" LOGGER
 SG_ BMU_M08_T11 : 40|8@1+ (1,0) [0|255] "degC" LOGGER
 SG_ BMU_M08_TAge1 : 48|16@1+ (1,0) [0|65535] "ms" LOGGER

BO_ 2416445568 BMU_TRANSMIT_BALANCING_N8: 8 BMU
 SG_ BMU_M08_Balance : 0|16@1+ (1,0) [0|65535] "" LOGGER
 SG_ BMU_M08_DieTemp : 16|8@1+ (1,0) [0|255] "degC" LOGGER

BO_ 2416443536 BMU_TRANSMIT_VOLTAGE_N9_P0: 8 BMU
 SG_ BMU_M09_V00 : 0|16@1+ (1,0) [0|65535] "mV" LOGGER
 SG_ BMU_M09_V01 : 16|16@1+ (1,0) [0|65535] "mV" LOGGER
 SG_ BMU_M09_V02 : 32|16@1+ (1,0) [0|65535] "mV" LOGGER
 SG_ BMU_M09_VAge0 : 48|16@1+ (1,0) [0|65535] "ms" LOGGER

BO_ 2416443537 BMU_TRANSMIT_VOLTAGE_N9_P1: 8 BMU
 SG_ BMU_M09_V03 : 0|16@1+ (1,0) [0|65535] "mV" LOGGER
 SG_ BMU_M09_V04 : 16|16@1+ (1,0) [0|65535] "mV" LOGGER
 SG_ BMU_M09_V05 : 32|16@1+ (1,0) [0|65535] "mV" LOGGER
 SG_ BMU_M09_VAge1 : 48|16@1+ (1,0) [0|65535] "ms" LOGGER

BO_ 2416443538 BMU_TRANSMIT_VOLTAGE_N9_P2: 8 BMU
 SG_ BMU_M09_V06 : 0|16@1+ (1,0) [0|65535] "mV" LOGGER
 SG_ BMU_M09_V07 : 16|16@1+ (1,0) [0|65535] "mV" LOGGER
 SG_ BMU_M09_V08 : 32|16@1+ (1,0) [0|65535] "mV" LOGGER
 SG_ BMU_M09_VAge2 : 48|16@1+ (1,0) [0|65535] "ms" LOGGER

BO_ 2416443539 BMU_TRANSMIT_VOLTAGE_N9_P3: 8 BMU
 SG_ BMU_M09_V09 : 0|16@1+ (1,0) [0|65535] "mV" LOGGER
 SG_ BMU_M09_V10 : 16|16@1+ (1,0) [0|65535] "mV" LOGGER
 SG_ BMU_M09_V11 : 32|16@1+ (1,0) [0|65535] "mV" LOGGER
 SG_ BMU_M09_VAge3 : 48|16@1+ (1,0) [0|65535] "ms" LOGGER

BO_ 2416444560 BMU_TRANSMIT_TEMPERATURE_N9_P0: 8 BMU
 SG_ BMU_M09_T00 : 0|8@1+ (1,0) [0|255] "degC" LOGGER
 SG_ BMU_M09_T01 : 8|8@1+ (1,0) [0|255] "degC" LOGGER
 SG_ BMU_M09_T02 : 16|8@1+ (1,0) [0|255] "degC" LOGGER
 SG_ BMU_M09_T03 : 24|8@1+ (1,0) [0|255] "degC" LOGGER
 SG_ BMU_M09_T04 : 32|8@1+ (1,0) [0|255] "degC" LOGGER
 SG_ BMU_M09_T05 : 40|8@1+ (1,0) [0|255] "degC" LOGGER
 SG_ BMU_M09_TAge0 : 48|16@1+ (1,0) [0|65535] "ms" LOGGER

BO_ 2416444561 BMU_TRANSMIT_TEMPERATURE_N9_P1: 8 BMU
 SG_ BMU_M09_T06 : 0|8@1+ (1,0) [0|255] "degC" LOGGER
 SG_ BMU_M09_T07 : 8|8@1+ (1,0) [0|255] "degC" LOGGER
 SG_ BMU_M09_T08 : 16|8@1+ (1,0) [0|255] "degC" LOGGER
 SG_ BMU_M09_T09 : 24|8@1+ (1,0) [0|255] "degC" LOGGER
 SG_ BMU_M09_T10 : 32|8@1+ (1,0) [0|255] "degC" LOGGER
 SG_ BMU_M09_T11 : 40|8@1+ (1,0) [0|255] "degC" LOGGER
 SG_ BMU_M09_TAge1 : 48|16@1+ (1,0) [0|65535] "ms" LOGGER

BO_ 2416445584 BMU_TRANSMIT_BALANCING_N9: 8 BMU
 SG_ BMU_M09_Balance : 0|16@1+ (1,0) [0|65535] "" LOGGER
 SG_ BMU_M09_DieTemp : 16|8@1+ (1,0) [0|255] "degC" LOGGER

BO_ 2416443552 BMU_TRANSMIT_VOLTAGE_N10_P0: 8 BMU
 SG_ BMU_M10_V00 : 0|16@1+ (1,0) [0|65535] "mV" LOGGER
 SG_ BMU_M10_V01 : 16|16@1+ (1,0) [0|65535] "mV" LOGGER
 SG_ BMU_M10_V02 : 32|16@1+ (1,0) [0|65535] "mV" LOGGER
 SG_ BMU_M10_VAge0 : 48|16@1+ (1,0) [0|65535] "ms" LOGGER

BO_ 2416443553 BMU_TRANSMIT_VOLTAGE_N10_P1: 8 BMU
 SG_ BMU_M10_V03 : 0|16@1+ (1,0) [0|65535] "mV" LOGGER
 SG_ BMU_M10_V04 : 16|16@1+ (1,0) [0|65535] "mV" LOGGER
 SG_ BMU_M10_V05 : 32|16@1+ (1,0) [0|65535] "mV" LOGGER
 SG_ BMU_M10_VAge1 : 48|16@1+ (1,0) [0|65535] "ms" LOGGER

BO_ 2416443554 BMU_TRANSMIT_VOLTAGE_N10_P2: 8 BMU
 SG_ BMU_M10_V06 : 0|16@1+ (1,0) [0|65535] "mV" LOGGER
 SG_ BMU_M10_V07 : 16|16@1+ (1,0) [0|65535] "mV" LOGGER
 SG_ BMU_M10_V08 : 32|16@1+ (1,0) [0|65535] "mV" LOGGER
 SG_ BMU_M10_VAge2 : 48|16@1+ (1,0) [0|65535] "ms" LOGGER

BO_ 2416443555 BMU_TRANSMIT_VOLTAGE_N10_P3: 8 BMU
 SG_ BMU_M10_V09 : 0|16@1+ (1,0) [0|65535] "mV" LOGGER
 SG_ BMU_M10_V10 : 16|16@1+ (1,0) [0|65535] "mV" LOGGER
 SG_ BMU_M10_V11 : 32|16@1+ (1,0) [0|65535] "mV" LOGGER
 SG_ BMU_M10_VAge3 : 48|16@1+ (1,0) [0|65535] "ms" LOGGER

BO_ 2416444576 BMU_TRANSMIT_TEMPERATURE_N10_P0: 8 BMU
 SG_ BMU_M10_T00 : 0|8@1+ (1,0) [0|255] "degC" LOGGER
 SG_ BMU_M10_T01 : 8|8@1+ (1,0) [0|255] "degC" LOGGER
 SG_ BMU_M10_T02 : 16|8@1+ (1,0) [0|255] "degC" LOGGER
 SG_ BMU_M10_T03 : 24|8@1+ (1,0) [0|255] "degC" LOGGER
 SG_ BMU_M10_T04 : 32|8@1+ (1,0) [0|255] "degC" LOGGER
 SG_ BMU_M10_T05 : 40|8@1+ (1,0) [0|255] "degC" LOGGER
 SG_ BMU_M10_TAge0 : 48|16@1+ (1,0) [0|65535] "ms" LOGGER

BO_ 2416444577 BMU_TRANSMIT_TEMPERATURE_N10_P1: 8 BMU
 SG_ BMU_M10_T06 : 0|8@1+ (1,0) [0|255] "degC" LOGGER
 SG_ BMU_M10_T07 : 8|8@1+ (1,0) [0|255] "degC" LOGGER
 SG_ BMU_M10_T08 : 16|8@1+ (1,0) [0|255] "degC" LOGGER
 SG_ BMU_M10_T09 : 24|8@1+ (1,0) [0|255] "degC" LOGGER
 SG_ BMU_M10_T10 : 32|8@1+ (1,0) [0|255] "degC" LOGGER
 SG_ BMU_M10_T11 : 40|8@1+ (1,0) [0|255] "degC" LOGGER
 SG_ BMU_M10_TAge1 : 48|16@1+ (1,0) [0|65535] "ms" LOGGER

BO_ 2416445600 BMU_TRANSMIT_BALANCING_N10: 8 BMU
 SG_ BMU_M10_Balance : 0|16@1+ (1,0) [0|65535] "" LOGGER
 SG_ BMU_M10_DieTemp : 16|8@1+ (1,0) [0|255] "degC" LOGGER

BO_ 2416443568 BMU_TRANSMIT_VOLTAGE_N11_P0: 8 BMU
 SG_ BMU_M11_V00 : 0|16@1+ (1,0) [0|65535] "mV" LOGGER
 SG_ BMU_M11_V01 : 16|16@1+ (1,0) [0|65535] "mV" LOGGER
 SG_ BMU_M11_V02 : 32|16@1+ (1,0) [0|65535] "mV" LOGGER
 SG_ BMU_M11_VAge0 : 48|16@1+ (1,0) [0|65535] "ms" LOGGER

BO_ 2416443569 BMU_TRANSMIT_VOLTAGE_N11_P1: 8 BMU
 SG_ BMU_M11_V03 : 0|16@1+ (1,0) [0|65535] "mV" LOGGER
 SG_ BMU_M11_V04 : 16|16@1+ (1,0) [0|65535] "mV" LOGGER
 SG_ BMU_M11_V05 : 32|16@1+ (1,0) [0|65535] "mV" LOGGER
 SG_ BMU_M11_VAge1 : 48|16@1+ (1,0) [0|65535] "ms" LOGGER

BO_ 2416443570 BMU_TRANSMIT_VOLTAGE_N11_P2: 8 BMU
 SG_ BMU_M11_V06 : 0|16@1+ (1,0) [0|65535] "mV" LOGGER
 SG_ BMU_M11_V07 : 16|16@1+ (1,0) [0|65535] "mV" LOGGER
 SG_ BMU_M11_V08 : 32|16@1+ (1,0) [0|65535] "mV" LOGGER
 SG_ BMU_M11_VAge2 : 48|16@1+ (1,0) [0|65535] "ms" LOGGER

BO_ 2416443571 BMU_TRANSMIT_VOLTAGE_N11_P3: 8 BMU
 SG_ BMU_M11_V09 : 0|16@1+ (1,0) [0|65535] "mV" LOGGER
 SG_ BMU_M11_V10 : 16|16@1+ (1,0) [0|65535] "mV" LOGGER
 SG_ BMU_M11_V11 : 32|16@1+ (1,0) [0|65535] "mV" LOGGER
 SG_ BMU_M11_VAge3 : 48|16@1+ (1,0) [0|65535] "ms" LOGGER

BO_ 2416444592 BMU_TRANSMIT_TEMPERATURE_N11_P0: 8 BMU
 SG_ BMU_M11_T00 : 0|8@1+ (1,0) [0|255] "degC" LOGGER
 SG_ BMU_M11_T01 : 8|8@1+ (1,0) [0|255] "degC" LOGGER
 SG_ BMU_M11_T02 : 16|8@1+ (1,0) [0|255] "degC" LOGGER
 SG_ BMU_M11_T03 : 24|8@1+ (1,0) [0|255] "degC" LOGGER
 SG_ BMU_M11_T04 : 32|8@1+ (1,0) [0|255] "degC" LOGGER
 SG_ BMU_M11_T05 : 40|8@1+ (1,0) [0|255] "degC" LOGGER
 SG_ BMU_M11_TAge0 : 48|16@1+ (1,0) [0|65535] "ms" LOGGER

BO_ 2416444593 BMU_TRANSMIT_TEMPERATURE_N11_P1: 8 BMU
 SG_ BMU_M11_T06 : 0|8@1+ (1,0) [0|255] "degC" LOGGER
 SG_ BMU_M11_T07 : 8|8@1+ (1,0) [0|255] "degC" LOGGER
 SG_ BMU_M11_T08 : 16|8@1+ (1,0) [0|255] "degC" LOGGER
 SG_ BMU_M11_T09 : 24|8@1+ (1,0) [0|255] "degC" LOGGER
 SG_ BMU_M11_T10 : 32|8@1+ (1,0) [0|255] "degC" LOGGER
 SG_ BMU_M11_T11 : 40|8@1+ (1,0) [0|255] "degC" LOGGER
 SG_ BMU_M11_TAge1 : 48|16@1+ (1,0) [0|65535] "ms" LOGGER

BO_ 2416445616 BMU_TRANSMIT_BALANCING_N11: 8 BMU
 SG_ BMU_M11_Balance : 0|16@1+ (1,0) [0|65535] "" LOGGER
 SG_ BMU_M11_DieTemp : 16|8@1+ (1,0) [0|255] "degC" LOGGER

BO_ 2416443584 BMU_TRANSMIT_VOLTAGE_N12_P0: 8 BMU
 SG_ BMU_M12_V00 : 0|16@1+ (1,0) [0|65535] "mV" LOGGER
 SG_ BMU_M12_V01 : 16|16@1+ (1,0) [0|65535] "mV" LOGGER
 SG_ BMU_M12_V02 : 32|16@1+ (1,0) [0|65535] "mV" LOGGER
 SG_ BMU_M12_VAge0 : 48|16@1+ (1,0) [0|65535] "ms" LOGGER

BO_ 2416443585 BMU_TRANSMIT_VOLTAGE_N12_P1: 8 BMU
 SG_ BMU_M12_V03 : 0|16@1+ (1,0) [0|65535] "mV" LOGGER
 SG_ BMU_M12_V04 : 16|16@1+ (1,0) [0|65535] "mV" LOGGER
 SG_ BMU_M12_V05 : 32|16@1+ (1,0) [0|65535] "mV" LOGGER
 SG_ BMU_M12_VAge1 : 48|16@1+ (1,0) [0|65535] "ms" LOGGER

BO_ 2416443586 BMU_TRANSMIT_VOLTAGE_N12_P2: 8 BMU
 SG_ BMU_M12_V06 : 0|16@1+ (1,0) [0|65535] "mV" LOGGER
 SG_ BMU_M12_V07 : 16|16@1+ (1,0) [0|65535] "mV" LOGGER
 SG_ BMU_M12_V08 : 32|16@1+ (1,0) [0|65535] "mV" LOGGER
 SG_ BMU_M12_VAge2 : 48|16@1+ (1,0) [0|65535] "ms" LOGGER

BO_ 2416443587 BMU_TRANSMIT_VOLTAGE_N12_P3: 8 BMU
 SG_ BMU_M12_V09 : 0|16@1+ (1,0) [0|65535] "mV" LOGGER
 SG_ BMU_M12_V10 : 16|16@1+ (1,0) [0|65535] "mV" LOGGER
 SG_ BMU_M12_V11 : 32|16@1+ (1,0) [0|65535] "mV" LOGGER
 SG_ BMU_M12_VAge3 : 48|16@1+ (1,0) [0|65535] "ms" LOGGER

BO_ 2416444608 BMU_TRANSMIT_TEMPERATURE_N12_P0: 8 BMU
 SG_ BMU_M12_T00 : 0|8@1+ (1,0) [0|255] "degC" LOGGER
 SG_ BMU_M12_T01 : 8|8@1+ (1,0) [0|255] "degC" LOGGER
 SG_ BMU_M12_T02 : 16|8@1+ (1,0) [0|255] "degC" LOGGER
 SG_ BMU_M12_T03 : 24|8@1+ (1,0) [0|255] "degC" LOGGER
 SG_ BMU_M12_T04 : 32|8@1+ (1,0) [0|255] "degC" LOGGER
 SG_ BMU_M12_T05 : 40|8@1+ (1,0) [0|255] "degC" LOGGER
 SG_ BMU_M12_TAge0 : 48|16@1+ (1,0) [0|65535] "ms" LOGGER

BO_ 2416444609 BMU_TRANSMIT_TEMPERATURE_N12_P1: 8 BMU
 SG_ BMU_M12_T06 : 0|8@1+ (1,0) [0|255] "degC" LOGGER
 SG_ BMU_M12_T07 : 8|8@1+ (1,0) [0|255] "degC" LOGGER
 SG_ BMU_M12_T08 : 16|8@1+ (1,0) [0|255] "degC" LOGGER
 SG_ BMU_M12_T09 : 24|8@1+ (1,0) [0|255] "degC" LOGGER
 SG_ BMU_M12_T10 : 32|8@1+ (1,0) [0|255] "degC" LOGGER
 SG_ BMU_M12_T11 : 40|8@1+ (1,0) [0|255] "degC" LOGGER
 SG_ BMU_M12_TAge1 : 48|16@1+ (1,0) [0|65535] "ms" LOGGER

BO_ 2416445632 BMU_TRANSMIT_BALANCING_N12: 8 BMU
 SG_ BMU_M12_Balance : 0|16@1+ (1,0) [0|65535] "" LOGGER
 SG_ BMU_M12_DieTemp : 16|8@1+ (1,0) [0|255] "degC" LOGGER

BO_ 2416443600 BMU_TRANSMIT_VOLTAGE_N13_P0: 8 BMU
 SG_ BMU_M13_V00 : 0|16@1+ (1,0) [0|65535] "mV" LOGGER
 SG_ BMU_M13_V01 : 16|16@1+ (1,0) [0|65535] "mV" LOGGER
 SG_ BMU_M13_V02 : 32|16@1+ (1,0) [0|65535] "mV" LOGGER
 SG_ BMU_M13_VAge0 : 48|16@1+ (1,0) [0|65535] "ms" LOGGER

BO_ 2416443601 BMU_TRANSMIT_VOLTAGE_N13_P1: 8 BMU
 SG_ BMU_M13_V03 : 0|16@1+ (1,0) [0|65535] "mV" LOGGER
 SG_ BMU_M13_V04 : 16|16@1+ (1,0) [0|65535] "mV" LOGGER
 SG_ BMU_M13_V05 : 32|16@1+ (1,0) [0|65535] "mV" LOGGER
 SG_ BMU_M13_VAge1 : 48|16@1+ (1,0) [0|65535] "ms" LOGGER

BO_ 2416443602 BMU_TRANSMIT_VOLTAGE_N13_P2: 8 BMU
 SG_ BMU_M13_V06 : 0|16@1+ (1,0) [0|65535] "mV" LOGGER
 SG_ BMU_M13_V07 : 16|16@1+ (1,0) [0|65535] "mV" LOGGER
 SG_ BMU_M13_V08 : 32|16@1+ (1,0) [0|65535] "mV" LOGGER
 SG_ BMU_M13_VAge2 : 48|16@1+ (1,0) [0|65535] "ms" LOGGER

BO_ 2416443603 BMU_TRANSMIT_VOLTAGE_N13_P3: 8 BMU
 SG_ BMU_M13_V09 : 0|16@1+ (1,0) [0|65535] "mV" LOGGER
 SG_ BMU_M13_V10 : 16|16@1+ (1,0) [0|65535] "mV" LOGGER
 SG_ BMU_M13_V11 : 32|16@1+ (1,0) [0|65535] "mV" LOGGER
 SG_ BMU_M13_VAge3 : 48|16@1+ (1,0) [0|65535] "ms" LOGGER

BO_ 2416444624 BMU_TRANSMIT_TEMPERATURE_N13_P0: 8 BMU
 SG_ BMU_M13_T00 : 0|8@1+ (1,0) [0|255] "degC" LOGGER
 SG_ BMU_M13_T01 : 8|8@1+ (1,0) [0|255] "degC" LOGGER
 SG_ BMU_M13_T02 : 16|8@1+ (1,0) [0|255] "degC" LOGGER
 SG_ BMU_M13_T03 : 24|8@1+ (1,0) [0|255] "degC" LOGGER
 SG_ BMU_M13_T04 : 32|8@1+ (1,0) [0|255] "degC" LOGGER
 SG_ BMU_M13_T05 : 40|8@1+ (1,0) [0|255] "degC" LOGGER
 SG_ BMU_M13_TAge0 : 48|16@1+ (1,0) [0|65535] "ms" LOGGER

BO_ 2416444625 BMU_TRANSMIT_TEMPERATURE_N13_P1: 8 BMU
 SG_ BMU_M13_T06 : 0|8@1+ (1,0) [0|255] "degC" LOGGER
 SG_ BMU_M13_T07 : 8|8@1+ (1,0) [0|255] "degC" LOGGER
 SG_ BMU_M13_T08 : 16|8@1+ (1,0) [0|255] "degC" LOGGER
 SG_ BMU_M13_T09 : 24|8@1+ (1,0) [0|255] "degC" LOGGER
 SG_ BMU_M13_T10 : 32|8@1+ (1,0) [0|255] "degC" LOGGER
 SG_ BMU_M13_T11 : 40|8@1+ (1,0) [0|255] "degC" LOGGER
 SG_ BMU_M13_TAge1 : 48|16@1+ (1,0) [0|65535] "ms" LOGGER

BO_ 2416445648 BMU_TRANSMIT_BALANCING_N13: 8 BMU
 SG_ BMU_M13_Balance : 0|16@1+ (1,0) [0|65535] "" LOGGER
 SG_ BMU_M13_DieTemp : 16|8@1+ (1,0) [0|255] "degC" LOGGER

BO_ 2416443616 BMU_TRANSMIT_VOLTAGE_N14_P0: 8 BMU
 SG_ BMU_M14_V00 : 0|16@1+ (1,0) [0|65535] "mV" LOGGER
 SG_ BMU_M14_V01 : 16|16@1+ (1,0) [0|65535] "mV" LOGGER
 SG_ BMU_M14_V02 : 32|16@1+ (1,0) [0|65535] "mV" LOGGER
 SG_ BMU_M14_VAge0 : 48|16@1+ (1,0) [0|65535] "ms" LOGGER

BO_ 2416443617 BMU_TRANSMIT_VOLTAGE_N14_P1: 8 BMU
 SG_ BMU_M14_V03 : 0|16@1+ (1,0) [0|65535] "mV" LOGGER
 SG_ BMU_M14_V04 : 16|16@1+ (1,0) [0|65535] "mV" LOGGER
 SG_ BMU_M14_V05 : 32|16@1+ (1,0) [0|65535] "mV" LOGGER
 SG_ BMU_M14_VAge1 : 48|16@1+ (1,0) [0|65535] "ms" LOGGER

BO_ 2416443618 BMU_TRANSMIT_VOLTAGE_N14_P2: 8 BMU
 SG_ BMU_M14_V06 : 0|16@1+ (1,0) [0|65535] "mV" LOGGER
 SG_ BMU_M14_V07 : 16|16@1+ (1,0) [0|65535] "mV" LOGGER
 SG_ BMU_M14_V08 : 32|16@1+ (1,0) [0|65535] "mV" LOGGER
 SG_ BMU_M14_VAge2 : 48|16@1+ (1,0) [0|65535] "ms" LOGGER

BO_ 2416443619 BMU_TRANSMIT_VOLTAGE_N14_P3: 8 BMU
 SG_ BMU_M14_V09 : 0|16@1+ (1,0) [0|65535] "mV" LOGGER
 SG_ BMU_M14_V10 : 16|16@1+ (1,0) [0|65535] "mV" LOGGER
 SG_ BMU_M14_V11 : 32|16@1+ (1,0) [0|65535] "mV" LOGGER
 SG_ BMU_M14_VAge3 : 48|16@1+ (1,0) [0|65535] "ms" LOGGER

BO_ 2416444640 BMU_TRANSMIT_TEMPERATURE_N14_P0: 8 BMU
 SG_ BMU_M14_T00 : 0|8@1+ (1,0) [0|255] "degC" LOGGER
 SG_ BMU_M14_T01 : 8|8@1+ (1,0) [0|255] "degC" LOGGER
 SG_ BMU_M14_T02 : 16|8@1+ (1,0) [0|255] "degC" LOGGER
 SG_ BMU_M14_T03 : 24|8@1+ (1,0) [0|255] "degC" LOGGER
 SG_ BMU_M14_T04 : 32|8@1+ (1,0) [0|255] "degC" LOGGER
 SG_ BMU_M14_T05 : 40|8@1+ (1,0) [0|255] "degC" LOGGER
 SG_ BMU_M14_TAge0 : 48|16@1+ (1,0) [0|65535] "ms" LOGGER

BO_ 2416444641 BMU_TRANSMIT_TEMPERATURE_N14_P1: 8 BMU
 SG_ BMU_M14_T06 : 0|8@1+ (1,0) [0|255] "degC" LOGGER
 SG_ BMU_M14_T07 : 8|8@1+ (1,0) [0|255] "degC" LOGGER
 SG_ BMU_M14_T08 : 16|8@1+ (1,0) [0|255] "degC" LOGGER
 SG_ BMU_M14_T09 : 24|8@1+ (1,0) [0|255] "degC" LOGGER
 SG_ BMU_M14_T10 : 32|8@1+ (1,0) [0|255] "degC" LOGGER
 SG_ BMU_M14_T11 : 40|8@1+ (1,0) [0|255] "degC" LOGGER
 SG_ BMU_M14_TAge1 : 48|16@1+ (1,0) [0|65535] "ms" LOGGER

BO_ 2416445664 BMU_TRANSMIT_BALANCING_N14: 8 BMU
 SG_ BMU_M14_Balance : 0|16@1+ (1,0) [0|65535] "" LOGGER
 SG_ BMU_M14_DieTemp : 16|8@1+ (1,0) [0|255] "degC" LOGGER

BO_ 2416443632 BMU_TRANSMIT_VOLTAGE_N15_P0: 8 BMU
 SG_ BMU_M15_V00 : 0|16@1+ (1,0) [0|65535] "mV" LOGGER
 SG_ BMU_M15_V01 : 16|16@1+ (1,0) [0|65535] "mV" LOGGER
 SG_ BMU_M15_V02 : 32|16@1+ (1,0) [0|65535] "mV" LOGGER
 SG_ BMU_M15_VAge0 : 48|16@1+ (1,0) [0|65535] "ms" LOGGER

BO_ 2416443633 BMU_TRANSMIT_VOLTAGE_N15_P1: 8 BMU
 SG_ BMU_M15_V03 : 0|16@1+ (1,0) [0|65535] "mV" LOGGER
 SG_ BMU_M15_V04 : 16|16@1+ (1,0) [0|65535] "mV" LOGGER
 SG_ BMU_M15_V05 : 32|16@1+ (1,0) [0|65535] "mV" LOGGER
 SG_ BMU_M15_VAge1 : 48|16@1+ (1,0) [0|65535] "ms" LOGGER

BO_ 2416443634 BMU_TRANSMIT_VOLTAGE_N15_P2: 8 BMU
 SG_ BMU_M15_V06 : 0|16@1+ (1,0) [0|65535] "mV" LOGGER
 SG_ BMU_M15_V07 : 16|16@1+ (1,0) [0|65535] "mV" LOGGER
 SG_ BMU_M15_V08 : 32|16@1+ (1,0) [0|65535] "mV" LOGGER
 SG_ BMU_M15_VAge2 : 48|16@1+ (1,0) [0|65535] "ms" LOGGER

BO_ 2416443635 BMU_TRANSMIT_VOLTAGE_N15_P3: 8 BMU
 SG_ BMU_M15_V09 : 0|16@1+ (1,0) [0|65535] "mV" LOGGER
 SG_ BMU_M15_V10 : 16|16@1+ (1,0) [0|65535] "mV" LOGGER
 SG_ BMU_M15_V11 : 32|16@1+ (1,0) [0|65535] "mV" LOGGER
 SG_ BMU_M15_VAge3 : 48|16@1+ (1,0) [0|65535] "ms" LOGGER

BO_ 2416444656 BMU_TRANSMIT_TEMPERATURE_N15_P0: 8 BMU
 SG_ BMU_M15_T00 : 0|8@1+ (1,0) [0|255] "degC" LOGGER
 SG_ BMU_M15_T01 : 8|8@1+ (1,0) [0|255] "degC" LOGGER
 SG_ BMU_M15_T02 : 16|8@1+ (1,0) [0|255] "degC" LOGGER
 SG_ BMU_M15_T03 : 24|8@1+ (1,0) [0|255] "degC" LOGGER
 SG_ BMU_M15_T04 : 32|8@1+ (1,0) [0|255] "degC" LOGGER
 SG_ BMU_M15_T05 : 40|8@1+ (1,0) [0|255] "degC" LOGGER
 SG_ BMU_M15_TAge0 : 48|16@1+ (1,0) [0|65535] "ms" LOGGER

BO_ 2416444657 BMU_TRANSMIT_TEMPERATURE_N15_P1: 8 BMU
 SG_ BMU_M15_T06 : 0|8@1+ (1,0) [0|255] "degC" LOGGER
 SG_ BMU_M15_T07 : 8|8@1+ (1,0) [0|255] "degC" LOGGER
 SG_ BMU_M15_T08 : 16|8@1+ (1,0) [0|255] "degC" LOGGER
 SG_ BMU_M15_T09 : 24|8@1+ (1,0) [0|255] "degC" LOGGER
 SG_ BMU_M15_T10 : 32|8@1+ (1,0) [0|255] "degC" LOGGER
 SG_ BMU_M15_T11 : 40|8@1+ (1,0) [0|255] "degC" LOGGER
 SG_ BMU_M15_TAge1 : 48|16@1+ (1,0) [0|65535] "ms" LOGGER

BO_ 2416445680 BMU_TRANSMIT_BALANCING_N15: 8 BMU
 SG_ BMU_M15_Balance : 0|16@1+ (1,0) [0|65535] "" LOGGER
 SG_ BMU_M15_DieTemp : 16|8@1+ (1,0) [0|255] "degC" LOGGER

BO_ 2416443648 BMU_TRANSMIT_VOLTAGE_N16_P0: 8 BMU
 SG_ BMU_M16_V00 : 0|16@1+ (1,0) [0|65535] "mV" LOGGER
 SG_ BMU_M16_V01 : 16|16@1+ (1,0) [0|65535] "mV" LOGGER
 SG_ BMU_M16_V02 : 32|16@1+ (1,0) [0|65535] "mV" LOGGER
 SG_ BMU_M16_VAge0 : 48|16@1+ (1,0) [0|65535] "ms" LOGGER

BO_ 2416443649 BMU_TRANSMIT_VOLTAGE_N16_P1: 8 BMU
 SG_ BMU_M16_V03 : 0|16@1+ (1,0) [0|65535] "mV" LOGGER
 SG_ BMU_M16_V04 : 16|16@1+ (1,0) [0|65535] "mV" LOGGER
 SG_ BMU_M16_V05 : 32|16@1+ (1,0) [0|65535] "mV" LOGGER
 SG_ BMU_M16_VAge1 : 48|16@1+ (1,0) [0|65535] "ms" LOGGER

BO_ 2416443650 BMU_TRANSMIT_VOLTAGE_N16_P2: 8 BMU
 SG_ BMU_M16_V06 : 0|16@1+ (1,0) [0|65535] "mV" LOGGER
 SG_ BMU_M16_V07 : 16|16@1+ (1,0) [0|65535] "mV" LOGGER
 SG_ BMU_M16_V08 : 32|16@1+ (1,0) [0|65535] "mV" LOGGER
 SG_ BMU_M16_VAge2 : 48|16@1+ (1,0) [0|65535] "ms" LOGGER

BO_ 2416443651 BMU_TRANSMIT_VOLTAGE_N16_P3: 8 BMU
 SG_ BMU_M16_V09 : 0|16@1+ (1,0) [0|65535] "mV" LOGGER
 SG_ BMU_M16_V10 : 16|16@1+ (1,0) [0|65535] "mV" LOGGER
 SG_ BMU_M16_V11 : 32|16@1+ (1,0) [0|65535] "mV" LOGGER
 SG_ BMU_M16_VAge3 : 48|16@1+ (1,0) [0|65535] "ms" LOGGER

BO_ 2416444672 BMU_TRANSMIT_TEMPERATURE_N16_P0: 8 BMU
 SG_ BMU_M16_T00 : 0|8@1+ (1,0) [0|255] "degC" LOGGER
 SG_ BMU_M16_T01 : 8|8@1+ (1,0) [0|255] "degC" LOGGER
 SG_ BMU_M16_T02 : 16|8@1+ (1,0) [0|255] "degC" LOGGER
 SG_ BMU_M16_T03 : 24|8@1+ (1,0) [0|255] "degC" LOGGER
 SG_ BMU_M16_T04 : 32|8@1+ (1,0) [0|255] "degC" LOGGER
 SG_ BMU_M16_T05 : 40|8@1+ (1,0) [0|255] "degC" LOGGER
 SG_ BMU_M16_TAge0 : 48|16@1+ (1,0) [0|65535] "ms" LOGGER

BO_ 2416444673 BMU_TRANSMIT_TEMPERATURE_N16_P1: 8 BMU
 SG_ BMU_M16_T06 : 0|8@1+ (1,0) [0|255] "degC" LOGGER
 SG_ BMU_M16_T07 : 8|8@1+ (1,0) [0|255] "degC" LOGGER
 SG_ BMU_M16_T08 : 16|8@1+ (1,0) [0|255] "degC" LOGGER
 SG_ BMU_M16_T09 : 24|8@1+ (1,0) [0|255] "degC" LOGGER
 SG_ BMU_M16_T10 : 32|8@1+ (1,0) [0|255] "degC" LOGGER
 SG_ BMU_M16_T11 : 40|8@1+ (1,0) [0|255] "degC" LOGGER
 SG_ BMU_M16_TAge1 : 48|16@1+ (1,0) [0|65535] "ms" LOGGER

BO_ 2416445696 BMU_TRANSMIT_BALANCING_N16: 8 BMU
 SG_ BMU_M16_Balance : 0|16@1+ (1,0) [0|65535] "" LOGGER
 SG_ BMU_M16_DieTemp : 16|8@1+ (1,0) [0|255] "degC" LOGGER

BO_ 2416443664 BMU_TRANSMIT_VOLTAGE_N17_P0: 8 BMU
 SG_ BMU_M17_V00 : 0|16@1+ (1,0) [0|65535] "mV" LOGGER
 SG_ BMU_M17_V01 : 16|16@1+ (1,0) [0|65535] "mV" LOGGER
 SG_ BMU_M17_V02 : 32|16@1+ (1,0) [0|65535] "mV" LOGGER
 SG_ BMU_M17_VAge0 : 48|16@1+ (1,0) [0|65535] "ms" LOGGER

BO_ 2416443665 BMU_TRANSMIT_VOLTAGE_N17_P1: 8 BMU
 SG_ BMU_M17_V03 : 0|16@1+ (1,0) [0|65535] "mV" LOGGER
 SG_ BMU_M17_V04 : 16|16@1+ (1,0) [0|65535] "mV" LOGGER
 SG_ BMU_M17_V05 : 32|16@1+ (1,0) [0|65535] "mV" LOGGER
 SG_ BMU_M17_VAge1 : 48|16@1+ (1,0) [0|65535] "ms" LOGGER

BO_ 2416443666 BMU_TRANSMIT_VOLTAGE_N17_P2: 8 BMU
 SG_ BMU_M17_V06 : 0|16@1+ (1,0) [0|65535] "mV" LOGGER
 SG_ BMU_M17_V07 : 16|16@1+ (1,0) [0|65535] "mV" LOGGER
 SG_ BMU_M17_V08 : 32|16@1+ (1,0) [0|65535] "mV" LOGGER
 SG_ BMU_M17_VAge2 : 48|16@1+ (1,0) [0|65535] "ms" LOGGER

BO_ 2416443667 BMU_TRANSMIT_VOLTAGE_N17_P3: 8 BMU
 SG_ BMU_M17_V09 : 0|16@1+ (1,0) [0|65535] "mV" LOGGER
 SG_ BMU_M17_V10 : 16|16@1+ (1,0) [0|65535] "mV" LOGGER
 SG_ BMU_M17_V11 : 32|16@1+ (1,0) [0|65535] "mV" LOGGER
 SG_ BMU_M17_VAge3 : 48|16@1+ (1,0) [0|65535] "ms" LOGGER

BO_ 2416444688 BMU_TRANSMIT_TEMPERATURE_N17_P0: 8 BMU
 SG_ BMU_M17_T00 : 0|8@1+ (1,0) [0|255] "degC" LOGGER
 SG_ BMU_M17_T01 : 8|8@1+ (1,0) [0|255] "degC" LOGGER
 SG_ BMU_M17_T02 : 16|8@1+ (1,0) [0|255] "degC" LOGGER
 SG_ BMU_M17_T03 : 24|8@1+ (1,0) [0|255] "degC" LOGGER
 SG_ BMU_M17_T04 : 32|8@1+ (1,0) [0|255] "degC" LOGGER
 SG_ BMU_M17_T05 : 40|8@1+ (1,0) [0|255] "degC" LOGGER
 SG_ BMU_M17_TAge0 : 48|16@1+ (1,0) [0|65535] "ms" LOGGER

BO_ 2416444689 BMU_TRANSMIT_TEMPERATURE_N17_P1: 8 BMU
 SG_ BMU_M17_T06 : 0|8@1+ (1,0) [0|255] "degC" LOGGER
 SG_ BMU_M17_T07 : 8|8@1+ (1,0) [0|255] "degC" LOGGER
 SG_ BMU_M17_T08 : 16|8@1+ (1,0) [0|255] "degC" LOGGER
 SG_ BMU_M17_T09 : 24|8@1+ (1,0) [0|255] "degC" LOGGER
 SG_ BMU_M17_T10 : 32|8@1+ (1,0) [0|255] "degC" LOGGER
 SG_ BMU_M17_T11 : 40|8@1+ (1,0) [0|255] "degC" LOGGER
 SG_ BMU_M17_TAge1 : 48|16@1+ (1,0) [0|65535] "ms" LOGGER

BO_ 2416445712 BMU_TRANSMIT_BALANCING_N17: 8 BMU
 SG_ BMU_M17_Balance : 0|16@1+ (1,0) [0|65535] "" LOGGER
 SG_ BMU_M17_DieTemp : 16|8@1+ (1,0) [0|255] "degC" LOGGER

BO_ 2416443680 BMU_TRANSMIT_VOLTAGE_N18_P0: 8 BMU
 SG_ BMU_M18_V00 : 0|16@1+ (1,0) [0|65535] "mV" LOGGER
 SG_ BMU_M18_V01 : 16|16@1+ (1,0) [0|65535] "mV" LOGGER
 SG_ BMU_M18_V02 : 32|16@1+ (1,0) [0|65535] "mV" LOGGER
 SG_ BMU_M18_VAge0 : 48|16@1+ (1,0) [0|65535] "ms" LOGGER

BO_ 2416443681 BMU_TRANSMIT_VOLTAGE_N18_P1: 8 BMU
 SG_ BMU_M18_V03 : 0|16@1+ (1,0) [0|65535] "mV" LOGGER
 SG_ BMU_M18_V04 : 16|16@1+ (1,0) [0|65535] "mV" LOGGER
 SG_ BMU_M18_V05 : 32|16@1+ (1,0) [0|65535] "mV" LOGGER
 SG_ BMU_M18_VAge1 : 48|16@1+ (1,0) [0|65535] "ms" LOGGER

BO_ 2416443682 BMU_TRANSMIT_VOLTAGE_N18_P2: 8 BMU
 SG_ BMU_M18_V06 : 0|16@1+ (1,0) [0|65535] "mV" LOGGER
 SG_ BMU_M18_V07 : 16|16@1+ (1,0) [0|65535] "mV" LOGGER
 SG_ BMU_M18_V08 : 32|16@1+ (1,0) [0|65535] "mV" LOGGER
 SG_ BMU_M18_VAge2 : 48|16@1+ (1,0) [0|65535] "ms" LOGGER

BO_ 2416443683 BMU_TRANSMIT_VOLTAGE_N18_P3: 8 BMU
 SG_ BMU_M18_V09 : 0|16@1+ (1,0) [0|65535] "mV" LOGGER
 SG_ BMU_M18_V10 : 16|16@1+ (1,0) [0|65535] "mV" LOGGER
 SG_ BMU_M18_V11 : 32|16@1+ (1,0) [0|65535] "mV" LOGGER
 SG_ BMU_M18_VAge3 : 48|16@1+ (1,0) [0|65535] "ms" LOGGER

BO_ 2416444704 BMU_TRANSMIT_TEMPERATURE_N18_P0: 8 BMU
 SG_ BMU_M18_T00 : 0|8@1+ (1,0) [0|255] "degC" LOGGER
 SG_ BMU_M18_T01 : 8|8@1+ (1,0) [0|255] "degC" LOGGER
 SG_ BMU_M18_T02 : 16|8@1+ (1,0) [0|255] "degC" LOGGER
 SG_ BMU_M18_T03 : 24|8@1+ (1,0) [0|255] "degC" LOGGER
 SG_ BMU_M18_T04 : 32|8@1+ (1,0) [0|255] "degC" LOGGER
 SG_ BMU_M18_T05 : 40|8@1+ (1,0) [0|255] "degC" LOGGER
 SG_ BMU_M18_TAge0 : 48|16@1+ (1,0) [0|65535] "ms" LOGGER

BO_ 2416444705 BMU_TRANSMIT_TEMPERATURE_N18_P1: 8 BMU
 SG_ BMU_M18_T06 : 0|8@1+ (1,0) [0|255] "degC" LOGGER
 SG_ BMU_M18_T07 : 8|8@1+ (1,0) [0|255] "degC" LOGGER
 SG_ BMU_M18_T08 : 16|8@1+ (1,0) [0|255] "degC" LOGGER
 SG_ BMU_M18_T09 : 24|8@1+ (1,0) [0|255] "degC" LOGGER
 SG_ BMU_M18_T10 : 32|8@1+ (1,0) [0|255] "degC" LOGGER
 SG_ BMU_M18_T11 : 40|8@1+ (1,0) [0|255] "degC" LOGGER
 SG_ BMU_M18_TAge1 : 48|16@1+ (1,0) [0|65535] "ms" LOGGER

BO_ 2416445728 BMU_TRANSMIT_BALANCING_N18: 8 BMU
 SG_ BMU_M18_Balance : 0|16@1+ (1,0) [0|65535] "" LOGGER
 SG_ BMU_M18_DieTemp : 16|8@1+ (1,0) [0|255] "degC" LOGGER

BO_ 2416443696 BMU_TRANSMIT_VOLTAGE_N19_P0: 8 BMU
 SG_ BMU_M19_V00 : 0|16@1+ (1,0) [0|65535] "mV" LOGGER
 SG_ BMU_M19_V01 : 16|16@1+ (1,0) [0|65535] "mV" LOGGER
 SG_ BMU_M19_V02 : 32|16@1+ (1,0) [0|65535] "mV" LOGGER
 SG_ BMU_M19_VAge0 : 48|16@1+ (1,0) [0|65535] "ms" LOGGER

BO_ 2416443697 BMU_TRANSMIT_VOLTAGE_N19_P1: 8 BMU
 SG_ BMU_M19_V03 : 0|16@1+ (1,0) [0|65535] "mV" LOGGER
 SG_ BMU_M19_V04 : 16|16@1+ (1,0) [0|65535] "mV" LOGGER
 SG_ BMU_M19_V05 : 32|16@1+ (1,0) [0|65535] "mV" LOGGER
 SG_ BMU_M19_VAge1 : 48|16@1+ (1,0) [0|65535] "ms" LOGGER

BO_ 2416443698 BMU_TRANSMIT_VOLTAGE_N19_P2: 8 BMU
 SG_ BMU_M19_V06 : 0|16@1+ (1,0) [0|65535] "mV" LOGGER
 SG_ BMU_M19_V07 : 16|16@1+ (1,0) [0|65535] "mV" LOGGER
 SG_ BMU_M19_V08 : 32|16@1+ (1,0) [0|65535] "mV" LOGGER
 SG_ BMU_M19_VAge2 : 48|16@1+ (1,0) [0|65535] "ms" LOGGER

BO_ 2416443699 BMU_TRANSMIT_VOLTAGE_N19_P3: 8 BMU
 SG_ BMU_M19_V09 : 0|16@1+ (1,0) [0|65535] "mV" LOGGER
 SG_ BMU_M19_V10 : 16|16@1+ (1,0) [0|65535] "mV" LOGGER
 SG_ BMU_M19_V11 : 32|16@1+ (1,0) [0|65535] "mV" LOGGER
 SG_ BMU_M19_VAge3 : 48|16@1+ (1,0) [0|65535] "ms" LOGGER

BO_ 2416444720 BMU_TRANSMIT_TEMPERATURE_N19_P0: 8 BMU
 SG_ BMU_M19_T00 : 0|8@1+ (1,0) [0|255] "degC" LOGGER
 SG_ BMU_M19_T01 : 8|8@1+ (1,0) [0|255] "degC" LOGGER
 SG_ BMU_M19_T02 : 16|8@1+ (1,0) [0|255] "degC" LOGGER
 SG_ BMU_M19_T03 : 24|8@1+ (1,0) [0|255] "degC" LOGGER
 SG_ BMU_M19_T04 : 32|8@1+ (1,0) [0|255] "degC" LOGGER
 SG_ BMU_M19_T05 : 40|8@1+ (1,0) [0|255] "degC" LOGGER
 SG_ BMU_M19_TAge0 : 48|16@1+ (1,0) [0|65535] "ms" LOGGER

BO_ 2416444721 BMU_TRANSMIT_TEMPERATURE_N19_P1: 8 BMU
 SG_ BMU_M19_T06 : 0|8@1+ (1,0) [0|255] "degC" LOGGER
 SG_ BMU_M19_T07 : 8|8@1+ (1,0) [0|255] "degC" LOGGER
 SG_ BMU_M19_T08 : 16|8@1+ (1,0) [0|255] "degC" LOGGER
 SG_ BMU_M19_T09 : 24|8@1+ (1,0) [0|255] "degC" LOGGER
 SG_ BMU_M19_T10 : 32|8@1+ (1,0) [0|255] "degC" LOGGER
 SG_ BMU_M19_T11 : 40|8@1+ (1,0) [0|255] "degC" LOGGER
 SG_ BMU_M19_TAge1 : 48|16@1+ (1,0) [0|65535] "ms" LOGGER

BO_ 2416445744 BMU_TRANSMIT_BALANCING_N19: 8 BMU
 SG_ BMU_M19_Balance : 0|16@1+ (1,0) [0|65535] "" LOGGER
 SG_ BMU_M19_DieTemp : 16|8@1+ (1,0) [0|255] "degC" LOGGER

BO_ 2416443712 BMU_TRANSMIT_VOLTAGE_N20_P0: 8 BMU
 SG_ BMU_M20_V00 : 0|16@1+ (1,0) [0|65535] "mV" LOGGER
 SG_ BMU_M20_V01 : 16|16@1+ (1,0) [0|65535] "mV" LOGGER
 SG_ BMU_M20_V02 : 32|16@1+ (1,0) [0|65535] "mV" LOGGER
 SG_ BMU_M20_VAge0 : 48|16@1+ (1,0) [0|65535] "ms" LOGGER

BO_ 2416443713 BMU_TRANSMIT_VOLTAGE_N20_P1: 8 BMU
 SG_ BMU_M20_V03 : 0|16@1+ (1,0) [0|65535] "mV" LOGGER
 SG_ BMU_M20_V04 : 16|16@1+ (1,0) [0|65535] "mV" LOGGER
 SG_ BMU_M20_V05 : 32|16@1+ (1,0) [0|65535] "mV" LOGGER
 SG_ BMU_M20_VAge1 : 48|16@1+ (1,0) [0|65535] "ms" LOGGER

BO_ 2416443714 BMU_TRANSMIT_VOLTAGE_N20_P2: 8 BMU
 SG_ BMU_M20_V06 : 0|16@1+ (1,0) [0|65535] "mV" LOGGER
 SG_ BMU_M20_V07 : 16|16@1+ (1,0) [0|65535] "mV" LOGGER
 SG_ BMU_M20_V08 : 32|16@1+ (1,0) [0|65535] "mV" LOGGER
 SG_ BMU_M20_VAge2 : 48|16@1+ (1,0) [0|65535] "ms" LOGGER

BO_ 2416443715 BMU_TRANSMIT_VOLTAGE_N20_P3: 8 BMU
 SG_ BMU_M20_V09 : 0|16@1+ (1,0) [0|65535] "mV" LOGGER
 SG_ BMU_M20_V10 : 16|16@1+ (1,0) [0|65535] "mV" LOGGER
 SG_ BMU_M20_V11 : 32|16@1+ (1,0) [0|65535] "mV" LOGGER
 SG_ BMU_M20_VAge3 : 48|16@1+ (1,0) [0|65535] "ms" LOGGER

BO_ 2416444736 BMU_TRANSMIT_TEMPERATURE_N20_P0: 8 BMU
 SG_ BMU_M20_T00 : 0|8@1+ (1,0) [0|255] "degC" LOGGER
 SG_ BMU_M20_T01 : 8|8@1+ (1,0) [0|255] "degC" LOGGER
 SG_ BMU_M20_T02 : 16|8@1+ (1,0) [0|255] "degC" LOGGER
 SG_ BMU_M20_T03 : 24|8@1+ (1,0) [0|255] "degC" LOGGER
 SG_ BMU_M20_T04 : 32|8@1+ (1,0) [0|255] "degC" LOGGER
 SG_ BMU_M20_T05 : 40|8@1+ (1,0) [0|255] "degC" LOGGER
 SG_ BMU_M20_TAge0 : 48|16@1+ (1,0) [0|65535] "ms" LOGGER

BO_ 2416444737 BMU_TRANSMIT_TEMPERATURE_N20_P1: 8 BMU
 SG_ BMU_M20_T06 : 0|8@1+ (1,0) [0|255] "degC" LOGGER
 SG_ BMU_M20_T07 : 8|8@1+ (1,0) [0|255] "degC" LOGGER
 SG_ BMU_M20_T08 : 16|8@1+ (1,0) [0|255] "degC" LOGGER
 SG_ BMU_M20_T09 : 24|8@1+ (1,0) [0|255] "degC" LOGGER
 SG_ BMU_M20_T10 : 32|8@1+ (1,0) [0|255] "degC" LOGGER
 SG_ BMU_M20_T11 : 40|8@1+ (1,0) [0|255] "degC" LOGGER
 SG_ BMU_M20_TAge1 : 48|16@1+ (1,0) [0|65535] "ms" LOGGER

BO_ 2416445760 BMU_TRANSMIT_BALANCING_N20: 8 BMU
 SG_ BMU_M20_Balance : 0|16@1+ (1,0) [0|65535] "" LOGGER
 SG_ BMU_M20_DieTemp : 16|8@1+ (1,0) [0|255] "degC" LOGGER

BO_ 2416443728 BMU_TRANSMIT_VOLTAGE_N21_P0: 8 BMU
 SG_ BMU_M21_V00 : 0|16@1+ (1,0) [0|65535] "mV" LOGGER
 SG_ BMU_M21_V01 : 16|16@1+ (1,0) [0|65535] "mV" LOGGER
 SG_ BMU_M21_V02 : 32|16@1+ (1,0) [0|65535] "mV" LOGGER
 SG_ BMU_M21_VAge0 : 48|16@1+ (1,0) [0|65535] "ms" LOGGER

BO_ 2416443729 BMU_TRANSMIT_VOLTAGE_N21_P1: 8 BMU
 SG_ BMU_M21_V03 : 0|16@1+ (1,0) [0|65535] "mV" LOGGER
 SG_ BMU_M21_V04 : 16|16@1+ (1,0) [0|65535] "mV" LOGGER
 SG_ BMU_M21_V05 : 32|16@1+ (1,0) [0|65535] "mV" LOGGER
 SG_ BMU_M21_VAge1 : 48|16@1+ (1,0) [0|65535] "ms" LOGGER

BO_ 2416443730 BMU_TRANSMIT_VOLTAGE_N21_P2: 8 BMU
 SG_ BMU_M21_V06 : 0|16@1+ (1,0) [0|65535] "mV" LOGGER
 SG_ BMU_M21_V07 : 16|16@1+ (1,0) [0|65535] "mV" LOGGER
 SG_ BMU_M21_V08 : 32|16@1+ (1,0) [0|65535] "mV" LOGGER
 SG_ BMU_M21_VAge2 : 48|16@1+ (1,0) [0|65535] "ms" LOGGER

BO_ 2416443731 BMU_TRANSMIT_VOLTAGE_N21_P3: 8 BMU
 SG_ BMU_M21_V09 : 0|16@1+ (1,0) [0|65535] "mV" LOGGER
 SG_ BMU_M21_V10 : 16|16@1+ (1,0) [0|65535] "mV" LOGGER
 SG_ BMU_M21_V11 : 32|16@1+ (1,0) [0|65535] "mV" LOGGER
 SG_ BMU_M21_VAge3 : 48|16@1+ (1,0) [0|65535] "ms" LOGGER

BO_ 2416444752 BMU_TRANSMIT_TEMPERATURE_N21_P0: 8 BMU
 SG_ BMU_M21_T00 : 0|8@1+ (1,0) [0|255] "degC" LOGGER
 SG_ BMU_M21_T01 : 8|8@1+ (1,0) [0|255] "degC" LOGGER
 SG_ BMU_M21_T02 : 16|8@1+ (1,0) [0|255] "degC" LOGGER
 SG_ BMU_M21_T03 : 24|8@1+ (1,0) [0|255] "degC" LOGGER
 SG_ BMU_M21_T04 : 32|8@1+ (1,0) [0|255] "degC" LOGGER
 SG_ BMU_M21_T05 : 40|8@1+ (1,0) [0|255] "degC" LOGGER
 SG_ BMU_M21_TAge0 : 48|16@1+ (1,0) [0|65535] "ms" LOGGER

BO_ 2416444753 BMU_TRANSMIT_TEMPERATURE_N21_P1: 8 BMU
 SG_ BMU_M21_T06 : 0|8@1+ (1,0) [0|255] "degC" LOGGER
 SG_ BMU_M21_T07 : 8|8@1+ (1,0) [0|255] "degC" LOGGER
 SG_ BMU_M21_T08 : 16|8@1+ (1,0) [0|255] "degC" LOGGER
 SG_ BMU_M21_T09 : 24|8@1+ (1,0) [0|255] "degC" LOGGER
 SG_ BMU_M21_T10 : 32|8@1+ (1,0) [0|255] "degC" LOGGER
 SG_ BMU_M21_T11 : 40|8@1+ (1,0) [0|255] "degC" LOGGER
 SG_ BMU_M21_TAge1 : 48|16@1+ (1,0) [0|65535] "ms" LOGGER

BO_ 2416445776 BMU_TRANSMIT_BALANCING_N21: 8 BMU
 SG_ BMU_M21_Balance : 0|16@1+ (1,0) [0|65535] "" LOGGER
 SG_ BMU_M21_DieTemp : 16|8@1+ (1,0) [0|255] "degC" LOGGER

BO_ 2416443744 BMU_TRANSMIT_VOLTAGE_N22_P0: 8 BMU
 SG_ BMU_M22_V00 : 0|16@1+ (1,0) [0|65535] "mV" LOGGER
 SG_ BMU_M22_V01 : 16|16@1+ (1,0) [0|65535] "mV" LOGGER
 SG_ BMU_M22_V02 : 32|16@1+ (1,0) [0|65535] "mV" LOGGER
 SG_ BMU_M22_VAge0 : 48|16@1+ (1,0) [0|65535] "ms" LOGGER

BO_ 2416443745 BMU_TRANSMIT_VOLTAGE_N22_P1: 8 BMU
 SG_ BMU_M22_V03 : 0|16@1+ (1,0) [0|65535] "mV" LOGGER
 SG_ BMU_M22_V04 : 16|16@1+ (1,0) [0|65535] "mV" LOGGER
 SG_ BMU_M22_V05 : 32|16@1+ (1,0) [0|65535] "mV" LOGGER
 SG_ BMU_M22_VAge1 : 48|16@1+ (1,0) [0|65535] "ms" LOGGER

BO_ 2416443746 BMU_TRANSMIT_VOLTAGE_N22_P2: 8 BMU
 SG_ BMU_M22_V06 : 0|16@1+ (1,0) [0|65535] "mV" LOGGER
 SG_ BMU_M22_V07 : 16|16@1+ (1,0) [0|65535] "mV" LOGGER
 SG_ BMU_M22_V08 : 32|16@1+ (1,0) [0|65535] "mV" LOGGER
 SG_ BMU_M22_VAge2 : 48|16@1+ (1,0) [0|65535] "ms" LOGGER

BO_ 2416443747 BMU_TRANSMIT_VOLTAGE_N22_P3: 8 BMU
 SG_ BMU_M22_V09 : 0|16@1+ (1,0) [0|65535] "mV" LOGGER
 SG_ BMU_M22_V10 : 16|16@1+ (1,0) [0|65535] "mV" LOGGER
 SG_ BMU_M22_V11 : 32|16@1+ (1,0) [0|65535] "mV" LOGGER
 SG_ BMU_M22_VAge3 : 48|16@1+ (1,0) [0|65535] "ms" LOGGER

BO_ 2416444768 BMU_TRANSMIT_TEMPERATURE_N22_P0: 8 BMU
 SG_ BMU_M22_T00 : 0|8@1+ (1,0) [0|255] "degC" LOGGER
 SG_ BMU_M22_T01 : 8|8@1+ (1,0) [0|255] "degC" LOGGER
 SG_ BMU_M22_T02 : 16|8@1+ (1,0) [0|255] "degC" LOGGER
 SG_ BMU_M22_T03 : 24|8@1+ (1,0) [0|255] "degC" LOGGER
 SG_ BMU_M22_T04 : 32|8@1+ (1,0) [0|255] "degC" LOGGER
 SG_ BMU_M22_T05 : 40|8@1+ (1,0) [0|255] "degC" LOGGER
 SG_ BMU_M22_TAge0 : 48|16@1+ (1,0) [0|65535] "ms" LOGGER

BO_ 2416444769 BMU_TRANSMIT_TEMPERATURE_N22_P1: 8 BMU
 SG_ BMU_M22_T06 : 0|8@1+ (1,0) [0|255] "degC" LOGGER
 SG_ BMU_M22_T07 : 8|8@1+ (1,0) [0|255] "degC" LOGGER
 SG_ BMU_M22_T08 : 16|8@1+ (1,0) [0|255] "degC" LOGGER
 SG_ BMU_M22_T09 : 24|8@1+ (1,0) [0|255] "degC" LOGGER
 SG_ BMU_M22_T10 : 32|8@1+ (1,0) [0|255] "degC" LOGGER
 SG_ BMU_M22_T11 : 40|8@1+ (1,0) [0|255] "degC" LOGGER
 SG_ BMU_M22_TAge1 : 48|16@1+ (1,0) [0|65535] "ms" LOGGER

BO_ 2416445792 BMU_TRANSMIT_BALANCING_N22: 8 BMU
 SG_ BMU_M22_Balance : 0|16@1+ (1,0) [0|65535] "" LOGGER
 SG_ BMU_M22_DieTemp : 16|8@1+ (1,0) [0|255] "degC" LOGGER

BO_ 2416443760 BMU_TRANSMIT_VOLTAGE_N23_P0: 8 BMU
 SG_ BMU_M23_V00 : 0|16@1+ (1,0) [0|65535] "mV" LOGGER
 SG_ BMU_M23_V01 : 16|16@1+ (1,0) [0|65535] "mV" LOGGER
 SG_ BMU_M23_V02 : 32|16@1+ (1,0) [0|65535] "mV" LOGGER
 SG_ BMU_M23_VAge0 : 48|16@1+ (1,0) [0|65535] "ms" LOGGER

BO_ 2416443761 BMU_TRANSMIT_VOLTAGE_N23_P1: 8 BMU
 SG_ BMU_M23_V03 : 0|16@1+ (1,0) [0|65535] "mV" LOGGER
 SG_ BMU_M23_V04 : 16|16@1+ (1,0) [0|65535] "mV" LOGGER
 SG_ BMU_M23_V05 : 32|16@1+ (1,0) [0|65535] "mV" LOGGER
 SG_ BMU_M23_VAge1 : 48|16@1+ (1,0) [0|65535] "ms" LOGGER

BO_ 2416443762 BMU_TRANSMIT_VOLTAGE_N23_P2: 8 BMU
 SG_ BMU_M23_V06 : 0|16@1+ (1,0) [0|65535] "mV" LOGGER
 SG_ BMU_M23_V07 : 16|16@1+ (1,0) [0|65535] "mV" LOGGER
 SG_ BMU_M23_V08 : 32|16@1+ (1,0) [0|65535] "mV" LOGGER
 SG_ BMU_M23_VAge2 : 48|16@1+ (1,0) [0|65535] "ms" LOGGER

BO_ 2416443763 BMU_TRANSMIT_VOLTAGE_N23_P3: 8 BMU
 SG_ BMU_M23_V09 : 0|16@1+ (1,0) [0|65535] "mV" LOGGER
 SG_ BMU_M23_V10 : 16|16@1+ (1,0) [0|65535] "mV" LOGGER
 SG_ BMU_M23_V11 : 32|16@1+ (1,0) [0|65535] "mV" LOGGER
 SG_ BMU_M23_VAge3 : 48|16@1+ (1,0) [0|65535] "ms" LOGGER

BO_ 2416444784 BMU_TRANSMIT_TEMPERATURE_N23_P0: 8 BMU
 SG_ BMU_M23_T00 : 0|8@1+ (1,0) [0|255] "degC" LOGGER
 SG_ BMU_M23_T01 : 8|8@1+ (1,0) [0|255] "degC" LOGGER
 SG_ BMU_M23_T02 : 16|8@1+ (1,0) [0|255] "degC" LOGGER
 SG_ BMU_M23_T03 : 24|8@1+ (1,0) [0|255] "degC" LOGGER
 SG_ BMU_M23_T04 : 32|8@1+ (1,0) [0|255] "degC" LOGGER
 SG_ BMU_M23_T05 : 40|8@1+ (1,0) [0|255] "degC" LOGGER
 SG_ BMU_M23_TAge0 : 48|16@1+ (1,0) [0|65535] "ms" LOGGER

BO_ 2416444785 BMU_TRANSMIT_TEMPERATURE_N23_P1: 8 BMU
 SG_ BMU_M23_T06 : 0|8@1+ (1,0) [0|255] "degC" LOGGER
 SG_ BMU_M23_T07 : 8|8@1+ (1,0) [0|255] "degC" LOGGER
 SG_ BMU_M23_T08 : 16|8@1+ (1,0) [0|255] "degC" LOGGER
 SG_ BMU_M23_T09 : 24|8@1+ (1,0) [0|255] "degC" LOGGER
 SG_ BMU_M23_T10 : 32|8@1+ (1,0) [0|255] "degC" LOGGER
 SG_ BMU_M23_T11 : 40|8@1+ (1,0) [0|255] "degC" LOGGER
 SG_ BMU_M23_TAge1 : 48|16@1+ (1,0) [0|65535] "ms" LOGGER

BO_ 2416445808 BMU_TRANSMIT_BALANCING_N23: 8 BMU
 SG_ BMU_M23_Balance : 0|16@1+ (1,0) [0|65535] "" LOGGER
 SG_ BMU_M23_DieTemp : 16|8@1+ (1,0) [0|255] "degC" LOGGER

BA_DEF_  "BusType" STRING ;
BA_DEF_  "DBName" STRING ;
BA_DEF_ BO_  "GenMsgCycleTime" INT 0 65535;
BA_DEF_ BO_  "SendType" STRING;
BA_DEF_ BO_  "RxTimeoutMs" INT 0 65535;
BA_DEF_ BO_  "Status" STRING;
BA_DEF_ BO_  "Variant" STRING;
BA_DEF_ BO_  "VFrameFormat" ENUM "StandardCAN","ExtendedCAN";
BA_DEF_DEF_  "BusType" "CAN";
BA_DEF_DEF_  "DBName" "";
BA_DEF_DEF_  "GenMsgCycleTime" 0;
BA_DEF_DEF_  "SendType" "Cyclic";
BA_DEF_DEF_  "RxTimeoutMs" 0;
BA_DEF_DEF_  "Status" "Current";
BA_DEF_DEF_  "Variant" "";
BA_DEF_DEF_  "VFrameFormat" "StandardCAN";
BA_ "DBName" "bmu_cells";
BA_ "GenMsgCycleTime" BO_ 2284093440 3300;
BA_ "SendType" BO_ 2284093440 "Burst";
BA_ "Variant" BO_ 2284093440 "bmu_comp25";
BA_ "VFrameFormat" BO_ 2284093440 1;
BA_ "GenMsgCycleTime" BO_ 2284093441 3300;
BA_ "SendType" BO_ 2284093441 "Burst";
BA_ "Variant" BO_ 2284093441 "bmu_comp25";
BA_ "VFrameFormat" BO_ 2284093441 1;
BA_ "GenMsgCycleTime" BO_ 2284093442 3300;
BA_ "SendType" BO_ 2284093442 "Burst";
BA_ "Variant" BO_ 2284093442 "bmu_comp25";
BA_ "VFrameFormat" BO_ 2284093442 1;
BA_ "GenMsgCycleTime" BO_ 2284093443 3300;
BA_ "SendType" BO_ 2284093443 "Burst";
BA_ "Variant" BO_ 2284093443 "bmu_comp25";
BA_ "VFrameFormat" BO_ 2284093443 1;
BA_ "GenMsgCycleTime" BO_ 2284094464 3300;
BA_ "SendType" BO_ 2284094464 "Burst";
BA_ "RxTimeoutMs" BO_ 2284094464 7000;
BA_ "Variant" BO_ 2284094464 "bmu_comp25";
BA_ "VFrameFormat" BO_ 2284094464 1;
BA_ "GenMsgCycleTime" BO_ 2284094465 3300;
BA_ "SendType" BO_ 2284094465 "Burst";
BA_ "RxTimeoutMs" BO_ 2284094465 7000;
BA_ "Variant" BO_ 2284094465 "bmu_comp25";
BA_ "VFrameFormat" BO_ 2284094465 1;
BA_ "GenMsgCycleTime" BO_ 2284095488 3300;
BA_ "SendType" BO_ 2284095488 "Burst";
BA_ "Variant" BO_ 2284095488 "bmu_comp25";
BA_ "VFrameFormat" BO_ 2284095488 1;
BA_ "GenMsgCycleTime" BO_ 2284093456 3300;
BA_ "SendType" BO_ 2284093456 "Burst";
BA_ "Variant" BO_ 2284093456 "bmu_comp25";
BA_ "VFrameFormat" BO_ 2284093456 1;
BA_ "GenMsgCycleTime" BO_ 2284093457 3300;
BA_ "SendType" BO_ 2284093457 "Burst";
BA_ "Variant" BO_ 2284093457 "bmu_comp25";
BA_ "VFrameFormat" BO_ 2284093457 1;
BA_ "GenMsgCycleTime" BO_ 2284093458 3300;
BA_ "SendType" BO_ 2284093458 "Burst";
BA_ "Variant" BO_ 2284093458 "bmu_comp25";
BA_ "VFrameFormat" BO_ 2284093458 1;
BA_ "GenMsgCycleTime" BO_ 2284093459 3300;
BA_ "SendType" BO_ 2284093459 "Burst";
BA_ "Variant" BO_ 2284093459 "bmu_comp25";
BA_ "VFrameFormat" BO_ 2284093459 1;
BA_ "GenMsgCycleTime" BO_ 2284094480 3300;
BA_ "SendType" BO_ 2284094480 "Burst";
BA_ "RxTimeoutMs" BO_ 2284094480 7000;
BA_ "Variant" BO_ 2284094480 "bmu_comp25";
BA_ "VFrameFormat" BO_ 2284094480 1;
BA_ "GenMsgCycleTime" BO_ 2284094481 3300;
BA_ "SendType" BO_ 2284094481 "Burst";
BA_ "RxTimeoutMs" BO_ 2284094481 7000;
BA_ "Variant" BO_ 2284094481 "bmu_comp25";
BA_ "VFrameFormat" BO_ 2284094481 1;
BA_ "GenMsgCycleTime" BO_ 2284095504 3300;
BA_ "SendType" BO_ 2284095504 "Burst";
BA_ "Variant" BO_ 2284095504 "bmu_comp25";
BA_ "VFrameFormat" BO_ 2284095504 1;
BA_ "GenMsgCycleTime" BO_ 2284093472 3300;
BA_ "SendType" BO_ 2284093472 "Burst";
BA_ "Variant" BO_ 2284093472 "bmu_comp25";
BA_ "VFrameFormat" BO_ 2284093472 1;
BA_ "GenMsgCycleTime" BO_ 2284093473 3300;
BA_ "SendType" BO_ 2284093473 "Burst";
BA_ "Variant" BO_ 2284093473 "bmu_comp25";
BA_ "VFrameFormat" BO_ 2284093473 1;
BA_ "GenMsgCycleTime" BO_ 2284093474 3300;
BA_ "SendType" BO_ 2284093474 "Burst";
BA_ "Variant" BO_ 2284093474 "bmu_comp25";
BA_ "VFrameFormat" BO_ 2284093474 1;
BA_ "GenMsgCycleTime" BO_ 2284093475 3300;
BA_ "SendType" BO_ 2284093475 "Burst";
BA_ "Variant" BO_ 2284093475 "bmu_comp25";
BA_ "VFrameFormat" BO_ 2284093475 1;
BA_ "GenMsgCycleTime" BO_ 2284094496 3300;
BA_ "SendType" BO_ 2284094496 "Burst";
BA_ "RxTimeoutMs" BO_ 2284094496 7000;
BA_ "Variant" BO_ 2284094496 "bmu_comp25";
BA_ "VFrameFormat" BO_ 2284094496 1;
BA_ "GenMsgCycleTime" BO_ 2284094497 3300;
BA_ "SendType" BO_ 2284094497 "Burst";
BA_ "RxTimeoutMs" BO_ 2284094497 7000;
BA_ "Variant" BO_ 2284094497 "bmu_comp25";
BA_ "VFrameFormat" BO_ 2284094497 1;
BA_ "GenMsgCycleTime" BO_ 2284095520 3300;
BA_ "SendType" BO_ 2284095520 "Burst";
BA_ "Variant" BO_ 2284095520 "bmu_comp25";
BA_ "VFrameFormat" BO_ 2284095520 1;
BA_ "GenMsgCycleTime" BO_ 2284093488 3300;
BA_ "SendType" BO_ 2284093488 "Burst";
BA_ "Variant" BO_ 2284093488 "bmu_comp25";
BA_ "VFrameFormat" BO_ 2284093488 1;
BA_ "GenMsgCycleTime" BO_ 2284093489 3300;
BA_ "SendType" BO_ 2284093489 "Burst";
BA_ "Variant" BO_ 2284093489 "bmu_comp25";
BA_ "VFrameFormat" BO_ 2284093489 1;
BA_ "GenMsgCycleTime" BO_ 2284093490 3300;
BA_ "SendType" BO_ 2284093490 "Burst";
BA_ "Variant" BO_ 2284093490 "bmu_comp25";
BA_ "VFrameFormat" BO_ 2284093490 1;
BA_ "GenMsgCycleTime" BO_ 2284093491 3300;
BA_ "SendType" BO_ 2284093491 "Burst";
BA_ "Variant" BO_ 2284093491 "bmu_comp25";
BA_ "VFrameFormat" BO_ 2284093491 1;
BA_ "GenMsgCycleTime" BO_ 2284094512 3300;
BA_ "SendType" BO_ 2284094512 "Burst";
BA_ "RxTimeoutMs" BO_ 2284094512 7000;
BA_ "Variant" BO_ 2284094512 "bmu_comp25";
BA_ "VFrameFormat" BO_ 2284094512 1;
BA_ "GenMsgCycleTime" BO_ 2284094513 3300;
BA_ "SendType" BO_ 2284094513 "Burst";
BA_ "RxTimeoutMs" BO_ 2284094513 7000;
BA_ "Variant" BO_ 2284094513 "bmu_comp25";
BA_ "VFrameFormat" BO_ 2284094513 1;
BA_ "GenMsgCycleTime" BO_ 2284095536 3300;
BA_ "SendType" BO_ 2284095536 "Burst";
BA_ "Variant" BO_ 2284095536 "bmu_comp25";
BA_ "VFrameFormat" BO_ 2284095536 1;
BA_ "GenMsgCycleTime" BO_ 2284093504 3300;
BA_ "SendType" BO_ 2284093504 "Burst";
BA_ "Variant" BO_ 2284093504 "bmu_comp25";
BA_ "VFrameFormat" BO_ 2284093504 1;
BA_ "GenMsgCycleTime" BO_ 2284093505 3300;
BA_ "SendType" BO_ 2284093505 "Burst";
BA_ "Variant" BO_ 2284093505 "bmu_comp25";
BA_ "VFrameFormat" BO_ 2284093505 1;
BA_ "GenMsgCycleTime" BO_ 2284093506 3300;
BA_ "SendType" BO_ 2284093506 "Burst";
BA_ "Variant" BO_ 2284093506 "bmu_comp25";
BA_ "VFrameFormat" BO_ 2284093506 1;
BA_ "GenMsgCycleTime" BO_ 2284093507 3300;
BA_ "SendType" BO_ 2284093507 "Burst";
BA_ "Variant" BO_ 2284093507 "bmu_comp25";
BA_ "VFrameFormat" BO_ 2284093507 1;
BA_ "GenMsgCycleTime" BO_ 2284094528 3300;
BA_ "SendType" BO_ 2284094528 "Burst";
BA_ "RxTimeoutMs" BO_ 2284094528 7000;
BA_ "Variant" BO_ 2284094528 "bmu_comp25";
BA_ "VFrameFormat" BO_ 2284094528 1;
BA_ "GenMsgCycleTime" BO_ 2284094529 3300;
BA_ "SendType" BO_ 2284094529 "Burst";
BA_ "RxTimeoutMs" BO_ 2284094529 7000;
BA_ "Variant" BO_ 2284094529 "bmu_comp25";
BA_ "VFrameFormat" BO_ 2284094529 1;
BA_ "GenMsgCycleTime" BO_ 2284095552 3300;
BA_ "SendType" BO_ 2284095552 "Burst";
BA_ "Variant" BO_ 2284095552 "bmu_comp25";
BA_ "VFrameFormat" BO_ 2284095552 1;
BA_ "GenMsgCycleTime" BO_ 2284093520 3300;
BA_ "SendType" BO_ 2284093520 "Burst";
BA_ "Variant" BO_ 2284093520 "bmu_comp25";
BA_ "VFrameFormat" BO_ 2284093520 1;
BA_ "GenMsgCycleTime" BO_ 2284093521 3300;
BA_ "SendType" BO_ 2284093521 "Burst";
BA_ "Variant" BO_ 2284093521 "bmu_comp25";
BA_ "VFrameFormat" BO_ 2284093521 1;
BA_ "GenMsgCycleTime" BO_ 2284093522 3300;
BA_ "SendType" BO_ 2284093522 "Burst";
BA_ "Variant" BO_ 2284093522 "bmu_comp25";
BA_ "VFrameFormat" BO_ 2284093522 1;
BA_ "GenMsgCycleTime" BO_ 2284093523 3300;
BA_ "SendType" BO_ 2284093523 "Burst";
BA_ "Variant" BO_ 2284093523 "bmu_comp25";
BA_ "VFrameFormat" BO_ 2284093523 1;
BA_ "GenMsgCycleTime" BO_ 2284094544 3300;
BA_ "SendType" BO_ 2284094544 "Burst";
BA_ "RxTimeoutMs" BO_ 2284094544 7000;
BA_ "Variant" BO_ 2284094544 "bmu_comp25";
BA_ "VFrameFormat" BO_ 2284094544 1;
BA_ "GenMsgCycleTime" BO_ 2284094545 3300;
BA_ "SendType" BO_ 2284094545 "Burst";
BA_ "RxTimeoutMs" BO_ 2284094545 7000;
BA_ "Variant" BO_ 2284094545 "bmu_comp25";
BA_ "VFrameFormat" BO_ 2284094545 1;
BA_ "GenMsgCycleTime" BO_ 2284095568 3300;
BA_ "SendType" BO_ 2284095568 "Burst";
BA_ "Variant" BO_ 2284095568 "bmu_comp25";
BA_ "VFrameFormat" BO_ 2284095568 1;
BA_ "GenMsgCycleTime" BO_ 2284093536 3300;
BA_ "SendType" BO_ 2284093536 "Burst";
BA_ "Variant" BO_ 2284093536 "bmu_comp25";
BA_ "VFrameFormat" BO_ 2284093536 1;
BA_ "GenMsgCycleTime" BO_ 2284093537 3300;
BA_ "SendType" BO_ 2284093537 "Burst";
BA_ "Variant" BO_ 2284093537 "bmu_comp25";
BA_ "VFrameFormat" BO_ 2284093537 1;
BA_ "GenMsgCycleTime" BO_ 2284093538 3300;
BA_ "SendType" BO_ 2284093538 "Burst";
BA_ "Variant" BO_ 2284093538 "bmu_comp25";
BA_ "VFrameFormat" BO_ 2284093538 1;
BA_ "GenMsgCycleTime" BO_ 2284093539 3300;
BA_ "SendType" BO_ 2284093539 "Burst";
BA_ "Variant" BO_ 2284093539 "bmu_comp25";
BA_ "VFrameFormat" BO_ 2284093539 1;
BA_ "GenMsgCycleTime" BO_ 2284094560 3300;
BA_ "SendType" BO_ 2284094560 "Burst";
BA_ "RxTimeoutMs" BO_ 2284094560 7000;
BA_ "Variant" BO_ 2284094560 "bmu_comp25";
BA_ "VFrameFormat" BO_ 2284094560 1;
BA_ "GenMsgCycleTime" BO_ 2284094561 3300;
BA_ "SendType" BO_ 2284094561 "Burst";
BA_ "RxTimeoutMs" BO_ 2284094561 7000;
BA_ "Variant" BO_ 2284094561 "bmu_comp25";
BA_ "VFrameFormat" BO_ 2284094561 1;
BA_ "GenMsgCycleTime" BO_ 2284095584 3300;
BA_ "SendType" BO_ 2284095584 "Burst";
BA_ "Variant" BO_ 2284095584 "bmu_comp25";
BA_ "VFrameFormat" BO_ 2284095584 1;
BA_ "GenMsgCycleTime" BO_ 2284093552 3300;
BA_ "SendType" BO_ 2284093552 "Burst";
BA_ "Variant" BO_ 2284093552 "bmu_comp25";
BA_ "VFrameFormat" BO_ 2284093552 1;
BA_ "GenMsgCycleTime" BO_ 2284093553 3300;
BA_ "SendType" BO_ 2284093553 "Burst";
BA_ "Variant" BO_ 2284093553 "bmu_comp25";
BA_ "VFrameFormat" BO_ 2284093553 1;
BA_ "GenMsgCycleTime" BO_ 2284093554 3300;
BA_ "SendType" BO_ 2284093554 "Burst";
BA_ "Variant" BO_ 2284093554 "bmu_comp25";
BA_ "VFrameFormat" BO_ 2284093554 1;
BA_ "GenMsgCycleTime" BO_ 2284093555 3300;
BA_ "SendType" BO_ 2284093555 "Burst";
BA_ "Variant" BO_ 2284093555 "bmu_comp25";
BA_ "VFrameFormat" BO_ 2284093555 1;
BA_ "GenMsgCycleTime" BO_ 2284094576 3300;
BA_ "SendType" BO_ 2284094576 "Burst";
BA_ "RxTimeoutMs" BO_ 2284094576 7000;
BA_ "Variant" BO_ 2284094576 "bmu_comp25";
BA_ "VFrameFormat" BO_ 2284094576 1;
BA_ "GenMsgCycleTime" BO_ 2284094577 3300;
BA_ "SendType" BO_ 2284094577 "Burst";
BA_ "RxTimeoutMs" BO_ 2284094577 7000;
BA_ "Variant" BO_ 2284094577 "bmu_comp25";
BA_ "VFrameFormat" BO_ 2284094577 1;
BA_ "GenMsgCycleTime" BO_ 2284095600 3300;
BA_ "SendType" BO_ 2284095600 "Burst";
BA_ "Variant" BO_ 2284095600 "bmu_comp25";
BA_ "VFrameFormat" BO_ 2284095600 1;
BA_ "GenMsgCycleTime" BO_ 2284093568 3300;
BA_ "SendType" BO_ 2284093568 "Burst";
BA_ "Variant" BO_ 2284093568 "bmu_comp25";
BA_ "VFrameFormat" BO_ 2284093568 1;
BA_ "GenMsgCycleTime" BO_ 2284093569 3300;
BA_ "SendType" BO_ 2284093569 "Burst";
BA_ "Variant" BO_ 2284093569 "bmu_comp25";
BA_ "VFrameFormat" BO_ 2284093569 1;
BA_ "GenMsgCycleTime" BO_ 2284093570 3300;
BA_ "SendType" BO_ 2284093570 "Burst";
BA_ "Variant" BO_ 2284093570 "bmu_comp25";
BA_ "VFrameFormat" BO_ 2284093570 1;
BA_ "GenMsgCycleTime" BO_ 2284093571 3300;
BA_ "SendType" BO_ 2284093571 "Burst";
BA_ "Variant" BO_ 2284093571 "bmu_comp25";
BA_ "VFrameFormat" BO_ 2284093571 1;
BA_ "GenMsgCycleTime" BO_ 2284094592 3300;
BA_ "SendType" BO_ 2284094592 "Burst";
BA_ "RxTimeoutMs" BO_ 2284094592 7000;
BA_ "Variant" BO_ 2284094592 "bmu_comp25";
BA_ "VFrameFormat" BO_ 2284094592 1;
BA_ "GenMsgCycleTime" BO_ 2284094593 3300;
BA_ "SendType" BO_ 2284094593 "Burst";
BA_ "RxTimeoutMs" BO_ 2284094593 7000;
BA_ "Variant" BO_ 2284094593 "bmu_comp25";
BA_ "VFrameFormat" BO_ 2284094593 1;
BA_ "GenMsgCycleTime" BO_ 2284095616 3300;
BA_ "SendType" BO_ 2284095616 "Burst";
BA_ "Variant" BO_ 2284095616 "bmu_comp25";
BA_ "VFrameFormat" BO_ 2284095616 1;
BA_ "GenMsgCycleTime" BO_ 2284093584 3300;
BA_ "SendType" BO_ 2284093584 "Burst";
BA_ "Variant" BO_ 2284093584 "bmu_comp25";
BA_ "VFrameFormat" BO_ 2284093584 1;
BA_ "GenMsgCycleTime" BO_ 2284093585 3300;
BA_ "SendType" BO_ 2284093585 "Burst";
BA_ "Variant" BO_ 2284093585 "bmu_comp25";
BA_ "VFrameFormat" BO_ 2284093585 1;
BA_ "GenMsgCycleTime" BO_ 2284093586 3300;
BA_ "SendType" BO_ 2284093586 "Burst";
BA_ "Variant" BO_ 2284093586 "bmu_comp25";
BA_ "VFrameFormat" BO_ 2284093586 1;
BA_ "GenMsgCycleTime" BO_ 2284093587 3300;
BA_ "SendType" BO_ 2284093587 "Burst";
BA_ "Variant" BO_ 2284093587 "bmu_comp25";
BA_ "VFrameFormat" BO_ 2284093587 1;
BA_ "GenMsgCycleTime" BO_ 2284094608 3300;
BA_ "SendType" BO_ 2284094608 "Burst";
BA_ "RxTimeoutMs" BO_ 2284094608 7000;
BA_ "Variant" BO_ 2284094608 "bmu_comp25";
BA_ "VFrameFormat" BO_ 2284094608 1;
BA_ "GenMsgCycleTime" BO_ 2284094609 3300;
BA_ "SendType" BO_ 2284094609 "Burst";
BA_ "RxTimeoutMs" BO_ 2284094609 7000;
BA_ "Variant" BO_ 2284094609 "bmu_comp25";
BA_ "VFrameFormat" BO_ 2284094609 1;
BA_ "GenMsgCycleTime" BO_ 2284095632 3300;
BA_ "SendType" BO_ 2284095632 "Burst";
BA_ "Variant" BO_ 2284095632 "bmu_comp25";
BA_ "VFrameFormat" BO_ 2284095632 1;
BA_ "GenMsgCycleTime" BO_ 2284093600 3300;
BA_ "SendType" BO_ 2284093600 "Burst";
BA_ "Variant" BO_ 2284093600 "bmu_comp25";
BA_ "VFrameFormat" BO_ 2284093600 1;
BA_ "GenMsgCycleTime" BO_ 2284093601 3300;
BA_ "SendType" BO_ 2284093601 "Burst";
BA_ "Variant" BO_ 2284093601 "bmu_comp25";
BA_ "VFrameFormat" BO_ 2284093601 1;
BA_ "GenMsgCycleTime" BO_ 2284093602 3300;
BA_ "SendType" BO_ 2284093602 "Burst";
BA_ "Variant" BO_ 2284093602 "bmu_comp25";
BA_ "VFrameFormat" BO_ 2284093602 1;
BA_ "GenMsgCycleTime" BO_ 2284093603 3300;
BA_ "SendType" BO_ 2284093603 "Burst";
BA_ "Variant" BO_ 2284093603 "bmu_comp25";
BA_ "VFrameFormat" BO_ 2284093603 1;
BA_ "GenMsgCycleTime" BO_ 2284094624 3300;
BA_ "SendType" BO_ 2284094624 "Burst";
BA_ "RxTimeoutMs" BO_ 2284094624 7000;
BA_ "Variant" BO_ 2284094624 "bmu_comp25";
BA_ "VFrameFormat" BO_ 2284094624 1;
BA_ "GenMsgCycleTime" BO_ 2284094625 3300;
BA_ "SendType" BO_ 2284094625 "Burst";
BA_ "RxTimeoutMs" BO_ 2284094625 7000;
BA_ "Variant" BO_ 2284094625 "bmu_comp25";
BA_ "VFrameFormat" BO_ 2284094625 1;
BA_ "GenMsgCycleTime" BO_ 2284095648 3300;
BA_ "SendType" BO_ 2284095648 "Burst";
BA_ "Variant" BO_ 2284095648 "bmu_comp25";
BA_ "VFrameFormat" BO_ 2284095648 1;
BA_ "GenMsgCycleTime" BO_ 2284093616 3300;
BA_ "SendType" BO_ 2284093616 "Burst";
BA_ "Variant" BO_ 2284093616 "bmu_comp25";
BA_ "VFrameFormat" BO_ 2284093616 1;
BA_ "GenMsgCycleTime" BO_ 2284093617 3300;
BA_ "SendType" BO_ 2284093617 "Burst";
BA_ "Variant" BO_ 2284093617 "bmu_comp25";
BA_ "VFrameFormat" BO_ 2284093617 1;
BA_ "GenMsgCycleTime" BO_ 2284093618 3300;
BA_ "SendType" BO_ 2284093618 "Burst";
BA_ "Variant" BO_ 2284093618 "bmu_comp25";
BA_ "VFrameFormat" BO_ 2284093618 1;
BA_ "GenMsgCycleTime" BO_ 2284093619 3300;
BA_ "SendType" BO_ 2284093619 "Burst";
BA_ "Variant" BO_ 2284093619 "bmu_comp25";
BA_ "VFrameFormat" BO_ 2284093619 1;
BA_ "GenMsgCycleTime" BO_ 2284094640 3300;
BA_ "SendType" BO_ 2284094640 "Burst";
BA_ "RxTimeoutMs" BO_ 2284094640 7000;
BA_ "Variant" BO_ 2284094640 "bmu_comp25";
BA_ "VFrameFormat" BO_ 2284094640 1;
BA_ "GenMsgCycleTime" BO_ 2284094641 3300;
BA_ "SendType" BO_ 2284094641 "Burst";
BA_ "RxTimeoutMs" BO_ 2284094641 7000;
BA_ "Variant" BO_ 2284094641 "bmu_comp25";
BA_ "VFrameFormat" BO_ 2284094641 1;
BA_ "GenMsgCycleTime" BO_ 2284095664 3300;
BA_ "SendType" BO_ 2284095664 "Burst";
BA_ "Variant" BO_ 2284095664 "bmu_comp25";
BA_ "VFrameFormat" BO_ 2284095664 1;
BA_ "GenMsgCycleTime" BO_ 2284093632 3300;
BA_ "SendType" BO_ 2284093632 "Burst";
BA_ "Variant" BO_ 2284093632 "bmu_comp25";
BA_ "VFrameFormat" BO_ 2284093632 1;
BA_ "GenMsgCycleTime" BO_ 2284093633 3300;
BA_ "SendType" BO_ 2284093633 "Burst";
BA_ "Variant" BO_ 2284093633 "bmu_comp25";
BA_ "VFrameFormat" BO_ 2284093633 1;
BA_ "GenMsgCycleTime" BO_ 2284093634 3300;
BA_ "SendType" BO_ 2284093634 "Burst";
BA_ "Variant" BO_ 2284093634 "bmu_comp25";
BA_ "VFrameFormat" BO_ 2284093634 1;
BA_ "GenMsgCycleTime" BO_ 2284093635 3300;
BA_ "SendType" BO_ 2284093635 "Burst";
BA_ "Variant" BO_ 2284093635 "bmu_comp25";
BA_ "VFrameFormat" BO_ 2284093635 1;
BA_ "GenMsgCycleTime" BO_ 2284094656 3300;
BA_ "SendType" BO_ 2284094656 "Burst";
BA_ "RxTimeoutMs" BO_ 2284094656 7000;
BA_ "Variant" BO_ 2284094656 "bmu_comp25";
BA_ "VFrameFormat" BO_ 2284094656 1;
BA_ "GenMsgCycleTime" BO_ 2284094657 3300;
BA_ "SendType" BO_ 2284094657 "Burst";
BA_ "RxTimeoutMs" BO_ 2284094657 7000;
BA_ "Variant" BO_ 2284094657 "bmu_comp25";
BA_ "VFrameFormat" BO_ 2284094657 1;
BA_ "GenMsgCycleTime" BO_ 2284095680 3300;
BA_ "SendType" BO_ 2284095680 "Burst";
BA_ "Variant" BO_ 2284095680 "bmu_comp25";
BA_ "VFrameFormat" BO_ 2284095680 1;
BA_ "GenMsgCycleTime" BO_ 2284093648 3300;
BA_ "SendType" BO_ 2284093648 "Burst";
BA_ "Variant" BO_ 2284093648 "bmu_comp25";
BA_ "VFrameFormat" BO_ 2284093648 1;
BA_ "GenMsgCycleTime" BO_ 2284093649 3300;
BA_ "SendType" BO_ 2284093649 "Burst";
BA_ "Variant" BO_ 2284093649 "bmu_comp25";
BA_ "VFrameFormat" BO_ 2284093649 1;
BA_ "GenMsgCycleTime" BO_ 2284093650 3300;
BA_ "SendType" BO_ 2284093650 "Burst";
BA_ "Variant" BO_ 2284093650 "bmu_comp25";
BA_ "VFrameFormat" BO_ 2284093650 1;
BA_ "GenMsgCycleTime" BO_ 2284093651 3300;
BA_ "SendType" BO_ 2284093651 "Burst";
BA_ "Variant" BO_ 2284093651 "bmu_comp25";
BA_ "VFrameFormat" BO_ 2284093651 1;
BA_ "GenMsgCycleTime" BO_ 2284094672 3300;
BA_ "SendType" BO_ 2284094672 "Burst";
BA_ "RxTimeoutMs" BO_ 2284094672 7000;
BA_ "Variant" BO_ 2284094672 "bmu_comp25";
BA_ "VFrameFormat" BO_ 2284094672 1;
BA_ "GenMsgCycleTime" BO_ 2284094673 3300;
BA_ "SendType" BO_ 2284094673 "Burst";
BA_ "RxTimeoutMs" BO_ 2284094673 7000;
BA_ "Variant" BO_ 2284094673 "bmu_comp25";
BA_ "VFrameFormat" BO_ 2284094673 1;
BA_ "GenMsgCycleTime" BO_ 2284095696 3300;
BA_ "SendType" BO_ 2284095696 "Burst";
BA_ "Variant" BO_ 2284095696 "bmu_comp25";
BA_ "VFrameFormat" BO_ 2284095696 1;
BA_ "GenMsgCycleTime" BO_ 2284093664 3300;
BA_ "SendType" BO_ 2284093664 "Burst";
BA_ "Variant" BO_ 2284093664 "bmu_comp25";
BA_ "VFrameFormat" BO_ 2284093664 1;
BA_ "GenMsgCycleTime" BO_ 2284093665 3300;
BA_ "SendType" BO_ 2284093665 "Burst";
BA_ "Variant" BO_ 2284093665 "bmu_comp25";
BA_ "VFrameFormat" BO_ 2284093665 1;
BA_ "GenMsgCycleTime" BO_ 2284093666 3300;
BA_ "SendType" BO_ 2284093666 "Burst";
BA_ "Variant" BO_ 2284093666 "bmu_comp25";
BA_ "VFrameFormat" BO_ 2284093666 1;
BA_ "GenMsgCycleTime" BO_ 2284093667 3300;
BA_ "SendType" BO_ 2284093667 "Burst";
BA_ "Variant" BO_ 2284093667 "bmu_comp25";
BA_ "VFrameFormat" BO_ 2284093667 1;
BA_ "GenMsgCycleTime" BO_ 2284094688 3300;
BA_ "SendType" BO_ 2284094688 "Burst";
BA_ "RxTimeoutMs" BO_ 2284094688 7000;
BA_ "Variant" BO_ 2284094688 "bmu_comp25";
BA_ "VFrameFormat" BO_ 2284094688 1;
BA_ "GenMsgCycleTime" BO_ 2284094689 3300;
BA_ "SendType" BO_ 2284094689 "Burst";
BA_ "RxTimeoutMs" BO_ 2284094689 7000;
BA_ "Variant" BO_ 2284094689 "bmu_comp25";
BA_ "VFrameFormat" BO_ 2284094689 1;
BA_ "GenMsgCycleTime" BO_ 2284095712 3300;
BA_ "SendType" BO_ 2284095712 "Burst";
BA_ "Variant" BO_ 2284095712 "bmu_comp25";
BA_ "VFrameFormat" BO_ 2284095712 1;
BA_ "GenMsgCycleTime" BO_ 2284093680 3300;
BA_ "SendType" BO_ 2284093680 "Burst";
BA_ "Variant" BO_ 2284093680 "bmu_comp25";
BA_ "VFrameFormat" BO_ 2284093680 1;
BA_ "GenMsgCycleTime" BO_ 2284093681 3300;
BA_ "SendType" BO_ 2284093681 "Burst";
BA_ "Variant" BO_ 2284093681 "bmu_comp25";
BA_ "VFrameFormat" BO_ 2284093681 1;
BA_ "GenMsgCycleTime" BO_ 2284093682 3300;
BA_ "SendType" BO_ 2284093682 "Burst";
BA_ "Variant" BO_ 2284093682 "bmu_comp25";
BA_ "VFrameFormat" BO_ 2284093682 1;
BA_ "GenMsgCycleTime" BO_ 2284093683 3300;
BA_ "SendType" BO_ 2284093683 "Burst";
BA_ "Variant" BO_ 2284093683 "bmu_comp25";
BA_ "VFrameFormat" BO_ 2284093683 1;
BA_ "GenMsgCycleTime" BO_ 2284094704 3300;
BA_ "SendType" BO_ 2284094704 "Burst";
BA_ "RxTimeoutMs" BO_ 2284094704 7000;
BA_ "Variant" BO_ 2284094704 "bmu_comp25";
BA_ "VFrameFormat" BO_ 2284094704 1;
BA_ "GenMsgCycleTime" BO_ 2284094705 3300;
BA_ "SendType" BO_ 2284094705 "Burst";
BA_ "RxTimeoutMs" BO_ 2284094705 7000;
BA_ "Variant" BO_ 2284094705 "bmu_comp25";
BA_ "VFrameFormat" BO_ 2284094705 1;
BA_ "GenMsgCycleTime" BO_ 2284095728 3300;
BA_ "SendType" BO_ 2284095728 "Burst";
BA_ "Variant" BO_ 2284095728 "bmu_comp25";
BA_ "VFrameFormat" BO_ 2284095728 1;
BA_ "GenMsgCycleTime" BO_ 2284093696 3300;
BA_ "SendType" BO_ 2284093696 "Burst";
BA_ "Variant" BO_ 2284093696 "bmu_comp25";
BA_ "VFrameFormat" BO_ 2284093696 1;
BA_ "GenMsgCycleTime" BO_ 2284093697 3300;
BA_ "SendType" BO_ 2284093697 "Burst";
BA_ "Variant" BO_ 2284093697 "bmu_comp25";
BA_ "VFrameFormat" BO_ 2284093697 1;
BA_ "GenMsgCycleTime" BO_ 2284093698 3300;
BA_ "SendType" BO_ 2284093698 "Burst";
BA_ "Variant" BO_ 2284093698 "bmu_comp25";
BA_ "VFrameFormat" BO_ 2284093698 1;
BA_ "GenMsgCycleTime" BO_ 2284093699 3300;
BA_ "SendType" BO_ 2284093699 "Burst";
BA_ "Variant" BO_ 2284093699 "bmu_comp25";
BA_ "VFrameFormat" BO_ 2284093699 1;
BA_ "GenMsgCycleTime" BO_ 2284094720 3300;
BA_ "SendType" BO_ 2284094720 "Burst";
BA_ "RxTimeoutMs" BO_ 2284094720 7000;
BA_ "Variant" BO_ 2284094720 "bmu_comp25";
BA_ "VFrameFormat" BO_ 2284094720 1;
BA_ "GenMsgCycleTime" BO_ 2284094721 3300;
BA_ "SendType" BO_ 2284094721 "Burst";
BA_ "RxTimeoutMs" BO_ 2284094721 7000;
BA_ "Variant" BO_ 2284094721 "bmu_comp25";
BA_ "VFrameFormat" BO_ 2284094721 1;
BA_ "GenMsgCycleTime" BO_ 2284095744 3300;
BA_ "SendType" BO_ 2284095744 "Burst";
BA_ "Variant" BO_ 2284095744 "bmu_comp25";
BA_ "VFrameFormat" BO_ 2284095744 1;
BA_ "GenMsgCycleTime" BO_ 2284093712 3300;
BA_ "SendType" BO_ 2284093712 "Burst";
BA_ "Variant" BO_ 2284093712 "bmu_comp25";
BA_ "VFrameFormat" BO_ 2284093712 1;
BA_ "GenMsgCycleTime" BO_ 2284093713 3300;
BA_ "SendType" BO_ 2284093713 "Burst";
BA_ "Variant" BO_ 2284093713 "bmu_comp25";
BA_ "VFrameFormat" BO_ 2284093713 1;
BA_ "GenMsgCycleTime" BO_ 2284093714 3300;
BA_ "SendType" BO_ 2284093714 "Burst";
BA_ "Variant" BO_ 2284093714 "bmu_comp25";
BA_ "VFrameFormat" BO_ 2284093714 1;
BA_ "GenMsgCycleTime" BO_ 2284093715 3300;
BA_ "SendType" BO_ 2284093715 "Burst";
BA_ "Variant" BO_ 2284093715 "bmu_comp25";
BA_ "VFrameFormat" BO_ 2284093715 1;
BA_ "GenMsgCycleTime" BO_ 2284094736 3300;
BA_ "SendType" BO_ 2284094736 "Burst";
BA_ "RxTimeoutMs" BO_ 2284094736 7000;
BA_ "Variant" BO_ 2284094736 "bmu_comp25";
BA_ "VFrameFormat" BO_ 2284094736 1;
BA_ "GenMsgCycleTime" BO_ 2284094737 3300;
BA_ "SendType" BO_ 2284094737 "Burst";
BA_ "RxTimeoutMs" BO_ 2284094737 7000;
BA_ "Variant" BO_ 2284094737 "bmu_comp25";
BA_ "VFrameFormat" BO_ 2284094737 1;
BA_ "GenMsgCycleTime" BO_ 2284095760 3300;
BA_ "SendType" BO_ 2284095760 "Burst";
BA_ "Variant" BO_ 2284095760 "bmu_comp25";
BA_ "VFrameFormat" BO_ 2284095760 1;
BA_ "GenMsgCycleTime" BO_ 2284093728 3300;
BA_ "SendType" BO_ 2284093728 "Burst";
BA_ "Variant" BO_ 2284093728 "bmu_comp25";
BA_ "VFrameFormat" BO_ 2284093728 1;
BA_ "GenMsgCycleTime" BO_ 2284093729 3300;
BA_ "SendType" BO_ 2284093729 "Burst";
BA_ "Variant" BO_ 2284093729 "bmu_comp25";
BA_ "VFrameFormat" BO_ 2284093729 1;
BA_ "GenMsgCycleTime" BO_ 2284093730 3300;
BA_ "SendType" BO_ 2284093730 "Burst";
BA_ "Variant" BO_ 2284093730 "bmu_comp25";
BA_ "VFrameFormat" BO_ 2284093730 1;
BA_ "GenMsgCycleTime" BO_ 2284093731 3300;
BA_ "SendType" BO_ 2284093731 "Burst";
BA_ "Variant" BO_ 2284093731 "bmu_comp25";
BA_ "VFrameFormat" BO_ 2284093731 1;
BA_ "GenMsgCycleTime" BO_ 2284094752 3300;
BA_ "SendType" BO_ 2284094752 "Burst";
BA_ "RxTimeoutMs" BO_ 2284094752 7000;
BA_ "Variant" BO_ 2284094752 "bmu_comp25";
BA_ "VFrameFormat" BO_ 2284094752 1;
BA_ "GenMsgCycleTime" BO_ 2284094753 3300;
BA_ "SendType" BO_ 2284094753 "Burst";
BA_ "RxTimeoutMs" BO_ 2284094753 7000;
BA_ "Variant" BO_ 2284094753 "bmu_comp25";
BA_ "VFrameFormat" BO_ 2284094753 1;
BA_ "GenMsgCycleTime" BO_ 2284095776 3300;
BA_ "SendType" BO_ 2284095776 "Burst";
BA_ "Variant" BO_ 2284095776 "bmu_comp25";
BA_ "VFrameFormat" BO_ 2284095776 1;
BA_ "GenMsgCycleTime" BO_ 2284093744 3300;
BA_ "SendType" BO_ 2284093744 "Burst";
BA_ "Variant" BO_ 2284093744 "bmu_comp25";
BA_ "VFrameFormat" BO_ 2284093744 1;
BA_ "GenMsgCycleTime" BO_ 2284093745 3300;
BA_ "SendType" BO_ 2284093745 "Burst";
BA_ "Variant" BO_ 2284093745 "bmu_comp25";
BA_ "VFrameFormat" BO_ 2284093745 1;
BA_ "GenMsgCycleTime" BO_ 2284093746 3300;
BA_ "SendType" BO_ 2284093746 "Burst";
BA_ "Variant" BO_ 2284093746 "bmu_comp25";
BA_ "VFrameFormat" BO_ 2284093746 1;
BA_ "GenMsgCycleTime" BO_ 2284093747 3300;
BA_ "SendType" BO_ 2284093747 "Burst";
BA_ "Variant" BO_ 2284093747 "bmu_comp25";
BA_ "VFrameFormat" BO_ 2284093747 1;
BA_ "GenMsgCycleTime" BO_ 2284094768 3300;
BA_ "SendType" BO_ 2284094768 "Burst";
BA_ "RxTimeoutMs" BO_ 2284094768 7000;
BA_ "Variant" BO_ 2284094768 "bmu_comp25";
BA_ "VFrameFormat" BO_ 2284094768 1;
BA_ "GenMsgCycleTime" BO_ 2284094769 3300;
BA_ "SendType" BO_ 2284094769 "Burst";
BA_ "RxTimeoutMs" BO_ 2284094769 7000;
BA_ "Variant" BO_ 2284094769 "bmu_comp25";
BA_ "VFrameFormat" BO_ 2284094769 1;
BA_ "GenMsgCycleTime" BO_ 2284095792 3300;
BA_ "SendType" BO_ 2284095792 "Burst";
BA_ "Variant" BO_ 2284095792 "bmu_comp25";
BA_ "VFrameFormat" BO_ 2284095792 1;
BA_ "GenMsgCycleTime" BO_ 2284093760 3300;
BA_ "SendType" BO_ 2284093760 "Burst";
BA_ "Variant" BO_ 2284093760 "bmu_comp25";
BA_ "VFrameFormat" BO_ 2284093760 1;
BA_ "GenMsgCycleTime" BO_ 2284093761 3300;
BA_ "SendType" BO_ 2284093761 "Burst";
BA_ "Variant" BO_ 2284093761 "bmu_comp25";
BA_ "VFrameFormat" BO_ 2284093761 1;
BA_ "GenMsgCycleTime" BO_ 2284093762 3300;
BA_ "SendType" BO_ 2284093762 "Burst";
BA_ "Variant" BO_ 2284093762 "bmu_comp25";
BA_ "VFrameFormat" BO_ 2284093762 1;
BA_ "GenMsgCycleTime" BO_ 2284093763 3300;
BA_ "SendType" BO_ 2284093763 "Burst";
BA_ "Variant" BO_ 2284093763 "bmu_comp25";
BA_ "VFrameFormat" BO_ 2284093763 1;
BA_ "GenMsgCycleTime" BO_ 2284094784 3300;
BA_ "SendType" BO_ 2284094784 "Burst";
BA_ "RxTimeoutMs" BO_ 2284094784 7000;
BA_ "Variant" BO_ 2284094784 "bmu_comp25";
BA_ "VFrameFormat" BO_ 2284094784 1;
BA_ "GenMsgCycleTime" BO_ 2284094785 3300;
BA_ "SendType" BO_ 2284094785 "Burst";
BA_ "RxTimeoutMs" BO_ 2284094785 7000;
BA_ "Variant" BO_ 2284094785 "bmu_comp25";
BA_ "VFrameFormat" BO_ 2284094785 1;
BA_ "GenMsgCycleTime" BO_ 2284095808 3300;
BA_ "SendType" BO_ 2284095808 "Burst";
BA_ "Variant" BO_ 2284095808 "bmu_comp25";
BA_ "VFrameFormat" BO_ 2284095808 1;
BA_ "GenMsgCycleTime" BO_ 2284093776 3300;
BA_ "SendType" BO_ 2284093776 "Burst";
BA_ "Variant" BO_ 2284093776 "bmu_comp25";
BA_ "VFrameFormat" BO_ 2284093776 1;
BA_ "GenMsgCycleTime" BO_ 2284093777 3300;
BA_ "SendType" BO_ 2284093777 "Burst";
BA_ "Variant" BO_ 2284093777 "bmu_comp25";
BA_ "VFrameFormat" BO_ 2284093777 1;
BA_ "GenMsgCycleTime" BO_ 2284093778 3300;
BA_ "SendType" BO_ 2284093778 "Burst";
BA_ "Variant" BO_ 2284093778 "bmu_comp25";
BA_ "VFrameFormat" BO_ 2284093778 1;
BA_ "GenMsgCycleTime" BO_ 2284093779 3300;
BA_ "SendType" BO_ 2284093779 "Burst";
BA_ "Variant" BO_ 2284093779 "bmu_comp25";
BA_ "VFrameFormat" BO_ 2284093779 1;
BA_ "GenMsgCycleTime" BO_ 2284094800 3300;
BA_ "SendType" BO_ 2284094800 "Burst";
BA_ "RxTimeoutMs" BO_ 2284094800 7000;
BA_ "Variant" BO_ 2284094800 "bmu_comp25";
BA_ "VFrameFormat" BO_ 2284094800 1;
BA_ "GenMsgCycleTime" BO_ 2284094801 3300;
BA_ "SendType" BO_ 2284094801 "Burst";
BA_ "RxTimeoutMs" BO_ 2284094801 7000;
BA_ "Variant" BO_ 2284094801 "bmu_comp25";
BA_ "VFrameFormat" BO_ 2284094801 1;
BA_ "GenMsgCycleTime" BO_ 2284095824 3300;
BA_ "SendType" BO_ 2284095824 "Burst";
BA_ "Variant" BO_ 2284095824 "bmu_comp25";
BA_ "VFrameFormat" BO_ 2284095824 1;
BA_ "GenMsgCycleTime" BO_ 2284093792 3300;
BA_ "SendType" BO_ 2284093792 "Burst";
BA_ "Variant" BO_ 2284093792 "bmu_comp25";
BA_ "VFrameFormat" BO_ 2284093792 1;
BA_ "GenMsgCycleTime" BO_ 2284093793 3300;
BA_ "SendType" BO_ 2284093793 "Burst";
BA_ "Variant" BO_ 2284093793 "bmu_comp25";
BA_ "VFrameFormat" BO_ 2284093793 1;
BA_ "GenMsgCycleTime" BO_ 2284093794 3300;
BA_ "SendType" BO_ 2284093794 "Burst";
BA_ "Variant" BO_ 2284093794 "bmu_comp25";
BA_ "VFrameFormat" BO_ 2284093794 1;
BA_ "GenMsgCycleTime" BO_ 2284093795 3300;
BA_ "SendType" BO_ 2284093795 "Burst";
BA_ "Variant" BO_ 2284093795 "bmu_comp25";
BA_ "VFrameFormat" BO_ 2284093795 1;
BA_ "GenMsgCycleTime" BO_ 2284094816 3300;
BA_ "SendType" BO_ 2284094816 "Burst";
BA_ "RxTimeoutMs" BO_ 2284094816 7000;
BA_ "Variant" BO_ 2284094816 "bmu_comp25";
BA_ "VFrameFormat" BO_ 2284094816 1;
BA_ "GenMsgCycleTime" BO_ 2284094817 3300;
BA_ "SendType" BO_ 2284094817 "Burst";
BA_ "RxTimeoutMs" BO_ 2284094817 7000;
BA_ "Variant" BO_ 2284094817 "bmu_comp25";
BA_ "VFrameFormat" BO_ 2284094817 1;
BA_ "GenMsgCycleTime" BO_ 2284095840 3300;
BA_ "SendType" BO_ 2284095840 "Burst";
BA_ "Variant" BO_ 2284095840 "bmu_comp25";
BA_ "VFrameFormat" BO_ 2284095840 1;
BA_ "GenMsgCycleTime" BO_ 2284093808 3300;
BA_ "SendType" BO_ 2284093808 "Burst";
BA_ "Variant" BO_ 2284093808 "bmu_comp25";
BA_ "VFrameFormat" BO_ 2284093808 1;
BA_ "GenMsgCycleTime" BO_ 2284093809 3300;
BA_ "SendType" BO_ 2284093809 "Burst";
BA_ "Variant" BO_ 2284093809 "bmu_comp25";
BA_ "VFrameFormat" BO_ 2284093809 1;
BA_ "GenMsgCycleTime" BO_ 2284093810 3300;
BA_ "SendType" BO_ 2284093810 "Burst";
BA_ "Variant" BO_ 2284093810 "bmu_comp25";
BA_ "VFrameFormat" BO_ 2284093810 1;
BA_ "GenMsgCycleTime" BO_ 2284093811 3300;
BA_ "SendType" BO_ 2284093811 "Burst";
BA_ "Variant" BO_ 2284093811 "bmu_comp25";
BA_ "VFrameFormat" BO_ 2284093811 1;
BA_ "GenMsgCycleTime" BO_ 2284094832 3300;
BA_ "SendType" BO_ 2284094832 "Burst";
BA_ "RxTimeoutMs" BO_ 2284094832 7000;
BA_ "Variant" BO_ 2284094832 "bmu_comp25";
BA_ "VFrameFormat" BO_ 2284094832 1;
BA_ "GenMsgCycleTime" BO_ 2284094833 3300;
BA_ "SendType" BO_ 2284094833 "Burst";
BA_ "RxTimeoutMs" BO_ 2284094833 7000;
BA_ "Variant" BO_ 2284094833 "bmu_comp25";
BA_ "VFrameFormat" BO_ 2284094833 1;
BA_ "GenMsgCycleTime" BO_ 2284095856 3300;
BA_ "SendType" BO_ 2284095856 "Burst";
BA_ "Variant" BO_ 2284095856 "bmu_comp25";
BA_ "VFrameFormat" BO_ 2284095856 1;
BA_ "GenMsgCycleTime" BO_ 2416443392 3300;
BA_ "SendType" BO_ 2416443392 "Burst";
BA_ "Status" BO_ 2416443392 "Planned";
BA_ "Variant" BO_ 2416443392 "bmu_qev6";
BA_ "VFrameFormat" BO_ 2416443392 1;
BA_ "GenMsgCycleTime" BO_ 2416443393 3300;
BA_ "SendType" BO_ 2416443393 "Burst";
BA_ "Status" BO_ 2416443393 "Planned";
BA_ "Variant" BO_ 2416443393 "bmu_qev6";
BA_ "VFrameFormat" BO_ 2416443393 1;
BA_ "GenMsgCycleTime" BO_ 2416443394 3300;
BA_ "SendType" BO_ 2416443394 "Burst";
BA_ "Status" BO_ 2416443394 "Planned";
BA_ "Variant" BO_ 2416443394 "bmu_qev6";
BA_ "VFrameFormat" BO_ 2416443394 1;
BA_ "GenMsgCycleTime" BO_ 2416443395 3300;
BA_ "SendType" BO_ 2416443395 "Burst";
BA_ "Status" BO_ 2416443395 "Planned";
BA_ "Variant" BO_ 2416443395 "bmu_qev6";
BA_ "VFrameFormat" BO_ 2416443395 1;
BA_ "GenMsgCycleTime" BO_ 2416444416 3300;
BA_ "SendType" BO_ 2416444416 "Burst";
BA_ "Status" BO_ 2416444416 "Planned";
BA_ "Variant" BO_ 2416444416 "bmu_qev6";
BA_ "VFrameFormat" BO_ 2416444416 1;
BA_ "GenMsgCycleTime" BO_ 2416444417 3300;
BA_ "SendType" BO_ 2416444417 "Burst";
BA_ "Status" BO_ 2416444417 "Planned";
BA_ "Variant" BO_ 2416444417 "bmu_qev6";
BA_ "VFrameFormat" BO_ 2416444417 1;
BA_ "GenMsgCycleTime" BO_ 2416445440 3300;
BA_ "SendType" BO_ 2416445440 "Burst";
BA_ "Status" BO_ 2416445440 "Planned";
BA_ "Variant" BO_ 2416445440 "bmu_qev6";
BA_ "VFrameFormat" BO_ 2416445440 1;
BA_ "GenMsgCycleTime" BO_ 2416443408 3300;
BA_ "SendType" BO_ 2416443408 "Burst";
BA_ "Status" BO_ 2416443408 "Planned";
BA_ "Variant" BO_ 2416443408 "bmu_qev6";
BA_ "VFrameFormat" BO_ 2416443408 1;
BA_ "GenMsgCycleTime" BO_ 2416443409 3300;
BA_ "SendType" BO_ 2416443409 "Burst";
BA_ "Status" BO_ 2416443409 "Planned";
BA_ "Variant" BO_ 2416443409 "bmu_qev6";
BA_ "VFrameFormat" BO_ 2416443409 1;
BA_ "GenMsgCycleTime" BO_ 2416443410 3300;
BA_ "SendType" BO_ 2416443410 "Burst";
BA_ "Status" BO_ 2416443410 "Planned";
BA_ "Variant" BO_ 2416443410 "bmu_qev6";
BA_ "VFrameFormat" BO_ 2416443410 1;
BA_ "GenMsgCycleTime" BO_ 2416443411 3300;
BA_ "SendType" BO_ 2416443411 "Burst";
BA_ "Status" BO_ 2416443411 "Planned";
BA_ "Variant" BO_ 2416443411 "bmu_qev6";
BA_ "VFrameFormat" BO_ 2416443411 1;
BA_ "GenMsgCycleTime" BO_ 2416444432 3300;
BA_ "SendType" BO_ 2416444432 "Burst";
BA_ "Status" BO_ 2416444432 "Planned";
BA_ "Variant" BO_ 2416444432 "bmu_qev6";
BA_ "VFrameFormat" BO_ 2416444432 1;
BA_ "GenMsgCycleTime" BO_ 2416444433 3300;
BA_ "SendType" BO_ 2416444433 "Burst";
BA_ "Status" BO_ 2416444433 "Planned";
BA_ "Variant" BO_ 2416444433 "bmu_qev6";
BA_ "VFrameFormat" BO_ 2416444433 1;
BA_ "GenMsgCycleTime" BO_ 2416445456 3300;
BA_ "SendType" BO_ 2416445456 "Burst";
BA_ "Status" BO_ 2416445456 "Planned";
BA_ "Variant" BO_ 2416445456 "bmu_qev6";
BA_ "VFrameFormat" BO_ 2416445456 1;
BA_ "GenMsgCycleTime" BO_ 2416443424 3300;
BA_ "SendType" BO_ 2416443424 "Burst";
BA_ "Status" BO_ 2416443424 "Planned";
BA_ "Variant" BO_ 2416443424 "bmu_qev6";
BA_ "VFrameFormat" BO_ 2416443424 1;
BA_ "GenMsgCycleTime" BO_ 2416443425 3300;
BA_ "SendType" BO_ 2416443425 "Burst";
BA_ "Status" BO_ 2416443425 "Planned";
BA_ "Variant" BO_ 2416443425 "bmu_qev6";
BA_ "VFrameFormat" BO_ 2416443425 1;
BA_ "GenMsgCycleTime" BO_ 2416443426 3300;
BA_ "SendType" BO_ 2416443426 "Burst";
BA_ "Status" BO_ 2416443426 "Planned";
BA_ "Variant" BO_ 2416443426 "bmu_qev6";
BA_ "VFrameFormat" BO_ 2416443426 1;
BA_ "GenMsgCycleTime" BO_ 2416443427 3300;
BA_ "SendType" BO_ 2416443427 "Burst";
BA_ "Status" BO_ 2416443427 "Planned";
BA_ "Variant" BO_ 2416443427 "bmu_qev6";
BA_ "VFrameFormat" BO_ 2416443427 1;
BA_ "GenMsgCycleTime" BO_ 2416444448 3300;
BA_ "SendType" BO_ 2416444448 "Burst";
BA_ "Status" BO_ 2416444448 "Planned";
BA_ "Variant" BO_ 2416444448 "bmu_qev6";
BA_ "VFrameFormat" BO_ 2416444448 1;
BA_ "GenMsgCycleTime" BO_ 2416444449 3300;
BA_ "SendType" BO_ 2416444449 "Burst";
BA_ "Status" BO_ 2416444449 "Planned";
BA_ "Variant" BO_ 2416444449 "bmu_qev6";
BA_ "VFrameFormat" BO_ 2416444449 1;
BA_ "GenMsgCycleTime" BO_ 2416445472 3300;
BA_ "SendType" BO_ 2416445472 "Burst";
BA_ "Status" BO_ 2416445472 "Planned";
BA_ "Variant" BO_ 2416445472 "bmu_qev6";
BA_ "VFrameFormat" BO_ 2416445472 1;
BA_ "GenMsgCycleTime" BO_ 2416443440 3300;
BA_ "SendType" BO_ 2416443440 "Burst";
BA_ "Status" BO_ 2416443440 "Planned";
BA_ "Variant" BO_ 2416443440 "bmu_qev6";
BA_ "VFrameFormat" BO_ 2416443440 1;
BA_ "GenMsgCycleTime" BO_ 2416443441 3300;
BA_ "SendType" BO_ 2416443441 "Burst";
BA_ "Status" BO_ 2416443441 "Planned";
BA_ "Variant" BO_ 2416443441 "bmu_qev6";
BA_ "VFrameFormat" BO_ 2416443441 1;
BA_ "GenMsgCycleTime" BO_ 2416443442 3300;
BA_ "SendType" BO_ 2416443442 "Burst";
BA_ "Status" BO_ 2416443442 "Planned";
BA_ "Variant" BO_ 2416443442 "bmu_qev6";
BA_ "VFrameFormat" BO_ 2416443442 1;
BA_ "GenMsgCycleTime" BO_ 2416443443 3300;
BA_ "SendType" BO_ 2416443443 "Burst";
BA_ "Status" BO_ 2416443443 "Planned";
BA_ "Variant" BO_ 2416443443 "bmu_qev6";
BA_ "VFrameFormat" BO_ 2416443443 1;
BA_ "GenMsgCycleTime" BO_ 2416444464 3300;
BA_ "SendType" BO_ 2416444464 "Burst";
BA_ "Status" BO_ 2416444464 "Planned";
BA_ "Variant" BO_ 2416444464 "bmu_qev6";
BA_ "VFrameFormat" BO_ 2416444464 1;
BA_ "GenMsgCycleTime" BO_ 2416444465 3300;
BA_ "SendType" BO_ 2416444465 "Burst";
BA_ "Status" BO_ 2416444465 "Planned";
BA_ "Variant" BO_ 2416444465 "bmu_qev6";
BA_ "VFrameFormat" BO_ 2416444465 1;
BA_ "GenMsgCycleTime" BO_ 2416445488 3300;
BA_ "SendType" BO_ 2416445488 "Burst";
BA_ "Status" BO_ 2416445488 "Planned";
BA_ "Variant" BO_ 2416445488 "bmu_qev6";
BA_ "VFrameFormat" BO_ 2416445488 1;
BA_ "GenMsgCycleTime" BO_ 2416443456 3300;
BA_ "SendType" BO_ 2416443456 "Burst";
BA_ "Status" BO_ 2416443456 "Planned";
BA_ "Variant" BO_ 2416443456 "bmu_qev6";
BA_ "VFrameFormat" BO_ 2416443456 1;
BA_ "GenMsgCycleTime" BO_ 2416443457 3300;
BA_ "SendType" BO_ 2416443457 "Burst";
BA_ "Status" BO_ 2416443457 "Planned";
BA_ "Variant" BO_ 2416443457 "bmu_qev6";
BA_ "VFrameFormat" BO_ 2416443457 1;
BA_ "GenMsgCycleTime" BO_ 2416443458 3300;
BA_ "SendType" BO_ 2416443458 "Burst";
BA_ "Status" BO_ 2416443458 "Planned";
BA_ "Variant" BO_ 2416443458 "bmu_qev6";
BA_ "VFrameFormat" BO_ 2416443458 1;
BA_ "GenMsgCycleTime" BO_ 2416443459 3300;
BA_ "SendType" BO_ 2416443459 "Burst";
BA_ "Status" BO_ 2416443459 "Planned";
BA_ "Variant" BO_ 2416443459 "bmu_qev6";
BA_ "VFrameFormat" BO_ 2416443459 1;
BA_ "GenMsgCycleTime" BO_ 2416444480 3300;
BA_ "SendType" BO_ 2416444480 "Burst";
BA_ "Status" BO_ 2416444480 "Planned";
BA_ "Variant" BO_ 2416444480 "bmu_qev6";
BA_ "VFrameFormat" BO_ 2416444480 1;
BA_ "GenMsgCycleTime" BO_ 2416444481 3300;
BA_ "SendType" BO_ 2416444481 "Burst";
BA_ "Status" BO_ 2416444481 "Planned";
BA_ "Variant" BO_ 2416444481 "bmu_qev6";
BA_ "VFrameFormat" BO_ 2416444481 1;
BA_ "GenMsgCycleTime" BO_ 2416445504 3300;
BA_ "SendType" BO_ 2416445504 "Burst";
BA_ "Status" BO_ 2416445504 "Planned";
BA_ "Variant" BO_ 2416445504 "bmu_qev6";
BA_ "VFrameFormat" BO_ 2416445504 1;
BA_ "GenMsgCycleTime" BO_ 2416443472 3300;
BA_ "SendType" BO_ 2416443472 "Burst";
BA_ "Status" BO_ 2416443472 "Planned";
BA_ "Variant" BO_ 2416443472 "bmu_qev6";
BA_ "VFrameFormat" BO_ 2416443472 1;
BA_ "GenMsgCycleTime" BO_ 2416443473 3300;
BA_ "SendType" BO_ 2416443473 "Burst";
BA_ "Status" BO_ 2416443473 "Planned";
BA_ "Variant" BO_ 2416443473 "bmu_qev6";
BA_ "VFrameFormat" BO_ 2416443473 1;
BA_ "GenMsgCycleTime" BO_ 2416443474 3300;
BA_ "SendType" BO_ 2416443474 "Burst";
BA_ "Status" BO_ 2416443474 "Planned";
BA_ "Variant" BO_ 2416443474 "bmu_qev6";
BA_ "VFrameFormat" BO_ 2416443474 1;
BA_ "GenMsgCycleTime" BO_ 2416443475 3300;
BA_ "SendType" BO_ 2416443475 "Burst";
BA_ "Status" BO_ 2416443475 "Planned";
BA_ "Variant" BO_ 2416443475 "bmu_qev6";
BA_ "VFrameFormat" BO_ 2416443475 1;
BA_ "GenMsgCycleTime" BO_ 2416444496 3300;
BA_ "SendType" BO_ 2416444496 "Burst";
BA_ "Status" BO_ 2416444496 "Planned";
BA_ "Variant" BO_ 2416444496 "bmu_qev6";
BA_ "VFrameFormat" BO_ 2416444496 1;
BA_ "GenMsgCycleTime" BO_ 2416444497 3300;
BA_ "SendType" BO_ 2416444497 "Burst";
BA_ "Status" BO_ 2416444497 "Planned";
BA_ "Variant" BO_ 2416444497 "bmu_qev6";
BA_ "VFrameFormat" BO_ 2416444497 1;
BA_ "GenMsgCycleTime" BO_ 2416445520 3300;
BA_ "SendType" BO_ 2416445520 "Burst";
BA_ "Status" BO_ 2416445520 "Planned";
BA_ "Variant" BO_ 2416445520 "bmu_qev6";
BA_ "VFrameFormat" BO_ 2416445520 1;
BA_ "GenMsgCycleTime" BO_ 2416443488 3300;
BA_ "SendType" BO_ 2416443488 "Burst";
BA_ "Status" BO_ 2416443488 "Planned";
BA_ "Variant" BO_ 2416443488 "bmu_qev6";
BA_ "VFrameFormat" BO_ 2416443488 1;
BA_ "GenMsgCycleTime" BO_ 2416443489 3300;
BA_ "SendType" BO_ 2416443489 "Burst";
BA_ "Status" BO_ 2416443489 "Planned";
BA_ "Variant" BO_ 2416443489 "bmu_qev6";
BA_ "VFrameFormat" BO_ 2416443489 1;
BA_ "GenMsgCycleTime" BO_ 2416443490 3300;
BA_ "SendType" BO_ 2416443490 "Burst";
BA_ "Status" BO_ 2416443490 "Planned";
BA_ "Variant" BO_ 2416443490 "bmu_qev6";
BA_ "VFrameFormat" BO_ 2416443490 1;
BA_ "GenMsgCycleTime" BO_ 2416443491 3300;
BA_ "SendType" BO_ 2416443491 "Burst";
BA_ "Status" BO_ 2416443491 "Planned";
BA_ "Variant" BO_ 2416443491 "bmu_qev6";
BA_ "VFrameFormat" BO_ 2416443491 1;
BA_ "GenMsgCycleTime" BO_ 2416444512 3300;
BA_ "SendType" BO_ 2416444512 "Burst";
BA_ "Status" BO_ 2416444512 "Planned";
BA_ "Variant" BO_ 2416444512 "bmu_qev6";
BA_ "VFrameFormat" BO_ 2416444512 1;
BA_ "GenMsgCycleTime" BO_ 2416444513 3300;
BA_ "SendType" BO_ 2416444513 "Burst";
BA_ "Status" BO_ 2416444513 "Planned";
BA_ "Variant" BO_ 2416444513 "bmu_qev6";
BA_ "VFrameFormat" BO_ 2416444513 1;
BA_ "GenMsgCycleTime" BO_ 2416445536 3300;
BA_ "SendType" BO_ 2416445536 "Burst";
BA_ "Status" BO_ 2416445536 "Planned";
BA_ "Variant" BO_ 2416445536 "bmu_qev6";
BA_ "VFrameFormat" BO_ 2416445536 1;
BA_ "GenMsgCycleTime" BO_ 2416443504 3300;
BA_ "SendType" BO_ 2416443504 "Burst";
BA_ "Status" BO_ 2416443504 "Planned";
BA_ "Variant" BO_ 2416443504 "bmu_qev6";
BA_ "VFrameFormat" BO_ 2416443504 1;
BA_ "GenMsgCycleTime" BO_ 2416443505 3300;
BA_ "SendType" BO_ 2416443505 "Burst";
BA_ "Status" BO_ 2416443505 "Planned";
BA_ "Variant" BO_ 2416443505 "bmu_qev6";
BA_ "VFrameFormat" BO_ 2416443505 1;
BA_ "GenMsgCycleTime" BO_ 2416443506 3300;
BA_ "SendType" BO_ 2416443506 "Burst";
BA_ "Status" BO_ 2416443506 "Planned";
BA_ "Variant" BO_ 2416443506 "bmu_qev6";
BA_ "VFrameFormat" BO_ 2416443506 1;
BA_ "GenMsgCycleTime" BO_ 2416443507 3300;
BA_ "SendType" BO_ 2416443507 "Burst";
BA_ "Status" BO_ 2416443507 "Planned";
BA_ "Variant" BO_ 2416443507 "bmu_qev6";
BA_ "VFrameFormat" BO_ 2416443507 1;
BA_ "GenMsgCycleTime" BO_ 2416444528 3300;
BA_ "SendType" BO_ 2416444528 "Burst";
BA_ "Status" BO_ 2416444528 "Planned";
BA_ "Variant" BO_ 2416444528 "bmu_qev6";
BA_ "VFrameFormat" BO_ 2416444528 1;
BA_ "GenMsgCycleTime" BO_ 2416444529 3300;
BA_ "SendType" BO_ 2416444529 "Burst";
BA_ "Status" BO_ 2416444529 "Planned";
BA_ "Variant" BO_ 2416444529 "bmu_qev6";
BA_ "VFrameFormat" BO_ 2416444529 1;
BA_ "GenMsgCycleTime" BO_ 2416445552 3300;
BA_ "SendType" BO_ 2416445552 "Burst";
BA_ "Status" BO_ 2416445552 "Planned";
BA_ "Variant" BO_ 2416445552 "bmu_qev6";
BA_ "VFrameFormat" BO_ 2416445552 1;
BA_ "GenMsgCycleTime" BO_ 2416443520 3300;
BA_ "SendType" BO_ 2416443520 "Burst";
BA_ "Status" BO_ 2416443520 "Planned";
BA_ "Variant" BO_ 2416443520 "bmu_qev6";
BA_ "VFrameFormat" BO_ 2416443520 1;
BA_ "GenMsgCycleTime" BO_ 2416443521 3300;
BA_ "SendType" BO_ 2416443521 "Burst";
BA_ "Status" BO_ 2416443521 "Planned";
BA_ "Variant" BO_ 2416443521 "bmu_qev6";
BA_ "VFrameFormat" BO_ 2416443521 1;
BA_ "GenMsgCycleTime" BO_ 2416443522 3300;
BA_ "SendType" BO_ 2416443522 "Burst";
BA_ "Status" BO_ 2416443522 "Planned";
BA_ "Variant" BO_ 2416443522 "bmu_qev6";
BA_ "VFrameFormat" BO_ 2416443522 1;
BA_ "GenMsgCycleTime" BO_ 2416443523 3300;
BA_ "SendType" BO_ 2416443523 "Burst";
BA_ "Status" BO_ 2416443523 "Planned";
BA_ "Variant" BO_ 2416443523 "bmu_qev6";
BA_ "VFrameFormat" BO_ 2416443523 1;
BA_ "GenMsgCycleTime" BO_ 2416444544 3300;
BA_ "SendType" BO_ 2416444544 "Burst";
BA_ "Status" BO_ 2416444544 "Planned";
BA_ "Variant" BO_ 2416444544 "bmu_qev6";
BA_ "VFrameFormat" BO_ 2416444544 1;
BA_ "GenMsgCycleTime" BO_ 2416444545 3300;
BA_ "SendType" BO_ 2416444545 "Burst";
BA_ "Status" BO_ 2416444545 "Planned";
BA_ "Variant" BO_ 2416444545 "bmu_qev6";
BA_ "VFrameFormat" BO_ 2416444545 1;
BA_ "GenMsgCycleTime" BO_ 2416445568 3300;
BA_ "SendType" BO_ 2416445568 "Burst";
BA_ "Status" BO_ 2416445568 "Planned";
BA_ "Variant" BO_ 2416445568 "bmu_qev6";
BA_ "VFrameFormat" BO_ 2416445568 1;
BA_ "GenMsgCycleTime" BO_ 2416443536 3300;
BA_ "SendType" BO_ 2416443536 "Burst";
BA_ "Status" BO_ 2416443536 "Planned";
BA_ "Variant" BO_ 2416443536 "bmu_qev6";
BA_ "VFrameFormat" BO_ 2416443536 1;
BA_ "GenMsgCycleTime" BO_ 2416443537 3300;
BA_ "SendType" BO_ 2416443537 "Burst";
BA_ "Status" BO_ 2416443537 "Planned";
BA_ "Variant" BO_ 2416443537 "bmu_qev6";
BA_ "VFrameFormat" BO_ 2416443537 1;
BA_ "GenMsgCycleTime" BO_ 2416443538 3300;
BA_ "SendType" BO_ 2416443538 "Burst";
BA_ "Status" BO_ 2416443538 "Planned";
BA_ "Variant" BO_ 2416443538 "bmu_qev6";
BA_ "VFrameFormat" BO_ 2416443538 1;
BA_ "GenMsgCycleTime" BO_ 2416443539 3300;
BA_ "SendType" BO_ 2416443539 "Burst";
BA_ "Status" BO_ 2416443539 "Planned";
BA_ "Variant" BO_ 2416443539 "bmu_qev6";
BA_ "VFrameFormat" BO_ 2416443539 1;
BA_ "GenMsgCycleTime" BO_ 2416444560 3300;
BA_ "SendType" BO_ 2416444560 "Burst";
BA_ "Status" BO_ 2416444560 "Planned";
BA_ "Variant" BO_ 2416444560 "bmu_qev6";
BA_ "VFrameFormat" BO_ 2416444560 1;
BA_ "GenMsgCycleTime" BO_ 2416444561 3300;
BA_ "SendType" BO_ 2416444561 "Burst";
BA_ "Status" BO_ 2416444561 "Planned";
BA_ "Variant" BO_ 2416444561 "bmu_qev6";
BA_ "VFrameFormat" BO_ 2416444561 1;
BA_ "GenMsgCycleTime" BO_ 2416445584 3300;
BA_ "SendType" BO_ 2416445584 "Burst";
BA_ "Status" BO_ 2416445584 "Planned";
BA_ "Variant" BO_ 2416445584 "bmu_qev6";
BA_ "VFrameFormat" BO_ 2416445584 1;
BA_ "GenMsgCycleTime" BO_ 2416443552 3300;
BA_ "SendType" BO_ 2416443552 "Burst";
BA_ "Status" BO_ 2416443552 "Planned";
BA_ "Variant" BO_ 2416443552 "bmu_qev6";
BA_ "VFrameFormat" BO_ 2416443552 1;
BA_ "GenMsgCycleTime" BO_ 2416443553 3300;
BA_ "SendType" BO_ 2416443553 "Burst";
BA_ "Status" BO_ 2416443553 "Planned";
BA_ "Variant" BO_ 2416443553 "bmu_qev6";
BA_ "VFrameFormat" BO_ 2416443553 1;
BA_ "GenMsgCycleTime" BO_ 2416443554 3300;
BA_ "SendType" BO_ 2416443554 "Burst";
BA_ "Status" BO_ 2416443554 "Planned";
BA_ "Variant" BO_ 2416443554 "bmu_qev6";
BA_ "VFrameFormat" BO_ 2416443554 1;
BA_ "GenMsgCycleTime" BO_ 2416443555 3300;
BA_ "SendType" BO_ 2416443555 "Burst";
BA_ "Status" BO_ 2416443555 "Planned";
BA_ "Variant" BO_ 2416443555 "bmu_qev6";
BA_ "VFrameFormat" BO_ 2416443555 1;
BA_ "GenMsgCycleTime" BO_ 2416444576 3300;
BA_ "SendType" BO_ 2416444576 "Burst";
BA_ "Status" BO_ 2416444576 "Planned";
BA_ "Variant" BO_ 2416444576 "bmu_qev6";
BA_ "VFrameFormat" BO_ 2416444576 1;
BA_ "GenMsgCycleTime" BO_ 2416444577 3300;
BA_ "SendType" BO_ 2416444577 "Burst";
BA_ "Status" BO_ 2416444577 "Planned";
BA_ "Variant" BO_ 2416444577 "bmu_qev6";
BA_ "VFrameFormat" BO_ 2416444577 1;
BA_ "GenMsgCycleTime" BO_ 2416445600 3300;
BA_ "SendType" BO_ 2416445600 "Burst";
BA_ "Status" BO_ 2416445600 "Planned";
BA_ "Variant" BO_ 2416445600 "bmu_qev6";
BA_ "VFrameFormat" BO_ 2416445600 1;
BA_ "GenMsgCycleTime" BO_ 2416443568 3300;
BA_ "SendType" BO_ 2416443568 "Burst";
BA_ "Status" BO_ 2416443568 "Planned";
BA_ "Variant" BO_ 2416443568 "bmu_qev6";
BA_ "VFrameFormat" BO_ 2416443568 1;
BA_ "GenMsgCycleTime" BO_ 2416443569 3300;
BA_ "SendType" BO_ 2416443569 "Burst";
BA_ "Status" BO_ 2416443569 "Planned";
BA_ "Variant" BO_ 2416443569 "bmu_qev6";
BA_ "VFrameFormat" BO_ 2416443569 1;
BA_ "GenMsgCycleTime" BO_ 2416443570 3300;
BA_ "SendType" BO_ 2416443570 "Burst";
BA_ "Status" BO_ 2416443570 "Planned";
BA_ "Variant" BO_ 2416443570 "bmu_qev6";
BA_ "VFrameFormat" BO_ 2416443570 1;
BA_ "GenMsgCycleTime" BO_ 2416443571 3300;
BA_ "SendType" BO_ 2416443571 "Burst";
BA_ "Status" BO_ 2416443571 "Planned";
BA_ "Variant" BO_ 2416443571 "bmu_qev6";
BA_ "VFrameFormat" BO_ 2416443571 1;
BA_ "GenMsgCycleTime" BO_ 2416444592 3300;
BA_ "SendType" BO_ 2416444592 "Burst";
BA_ "Status" BO_ 2416444592 "Planned";
BA_ "Variant" BO_ 2416444592 "bmu_qev6";
BA_ "VFrameFormat" BO_ 2416444592 1;
BA_ "GenMsgCycleTime" BO_ 2416444593 3300;
BA_ "SendType" BO_ 2416444593 "Burst";
BA_ "Status" BO_ 2416444593 "Planned";
BA_ "Variant" BO_ 2416444593 "bmu_qev6";
BA_ "VFrameFormat" BO_ 2416444593 1;
BA_ "GenMsgCycleTime" BO_ 2416445616 3300;
BA_ "SendType" BO_ 2416445616 "Burst";
BA_ "Status" BO_ 2416445616 "Planned";
BA_ "Variant" BO_ 2416445616 "bmu_qev6";
BA_ "VFrameFormat" BO_ 2416445616 1;
BA_ "GenMsgCycleTime" BO_ 2416443584 3300;
BA_ "SendType" BO_ 2416443584 "Burst";
BA_ "Status" BO_ 2416443584 "Planned";
BA_ "Variant" BO_ 2416443584 "bmu_qev6";
BA_ "VFrameFormat" BO_ 2416443584 1;
BA_ "GenMsgCycleTime" BO_ 2416443585 3300;
BA_ "SendType" BO_ 2416443585 "Burst";
BA_ "Status" BO_ 2416443585 "Planned";
BA_ "Variant" BO_ 2416443585 "bmu_qev6";
BA_ "VFrameFormat" BO_ 2416443585 1;
BA_ "GenMsgCycleTime" BO_ 2416443586 3300;
BA_ "SendType" BO_ 2416443586 "Burst";
BA_ "Status" BO_ 2416443586 "Planned";
BA_ "Variant" BO_ 2416443586 "bmu_qev6";
BA_ "VFrameFormat" BO_ 2416443586 1;
BA_ "GenMsgCycleTime" BO_ 2416443587 3300;
BA_ "SendType" BO_ 2416443587 "Burst";
BA_ "Status" BO_ 2416443587 "Planned";
BA_ "Variant" BO_ 2416443587 "bmu_qev6";
BA_ "VFrameFormat" BO_ 2416443587 1;
BA_ "GenMsgCycleTime" BO_ 2416444608 3300;
BA_ "SendType" BO_ 2416444608 "Burst";
BA_ "Status" BO_ 2416444608 "Planned";
BA_ "Variant" BO_ 2416444608 "bmu_qev6";
BA_ "VFrameFormat" BO_ 2416444608 1;
BA_ "GenMsgCycleTime" BO_ 2416444609 3300;
BA_ "SendType" BO_ 2416444609 "Burst";
BA_ "Status" BO_ 2416444609 "Planned";
BA_ "Variant" BO_ 2416444609 "bmu_qev6";
BA_ "VFrameFormat" BO_ 2416444609 1;
BA_ "GenMsgCycleTime" BO_ 2416445632 3300;
BA_ "SendType" BO_ 2416445632 "Burst";
BA_ "Status" BO_ 2416445632 "Planned";
BA_ "Variant" BO_ 2416445632 "bmu_qev6";
BA_ "VFrameFormat" BO_ 2416445632 1;
BA_ "GenMsgCycleTime" BO_ 2416443600 3300;
BA_ "SendType" BO_ 2416443600 "Burst";
BA_ "Status" BO_ 2416443600 "Planned";
BA_ "Variant" BO_ 2416443600 "bmu_qev6";
BA_ "VFrameFormat" BO_ 2416443600 1;
BA_ "GenMsgCycleTime" BO_ 2416443601 3300;
BA_ "SendType" BO_ 2416443601 "Burst";
BA_ "Status" BO_ 2416443601 "Planned";
BA_ "Variant" BO_ 2416443601 "bmu_qev6";
BA_ "VFrameFormat" BO_ 2416443601 1;
BA_ "GenMsgCycleTime" BO_ 2416443602 3300;
BA_ "SendType" BO_ 2416443602 "Burst";
BA_ "Status" BO_ 2416443602 "Planned";
BA_ "Variant" BO_ 2416443602 "bmu_qev6";
BA_ "VFrameFormat" BO_ 2416443602 1;
BA_ "GenMsgCycleTime" BO_ 2416443603 3300;
BA_ "SendType" BO_ 2416443603 "Burst";
BA_ "Status" BO_ 2416443603 "Planned";
BA_ "Variant" BO_ 2416443603 "bmu_qev6";
BA_ "VFrameFormat" BO_ 2416443603 1;
BA_ "GenMsgCycleTime" BO_ 2416444624 3300;
BA_ "SendType" BO_ 2416444624 "Burst";
BA_ "Status" BO_ 2416444624 "Planned";
BA_ "Variant" BO_ 2416444624 "bmu_qev6";
BA_ "VFrameFormat" BO_ 2416444624 1;
BA_ "GenMsgCycleTime" BO_ 2416444625 3300;
BA_ "SendType" BO_ 2416444625 "Burst";
BA_ "Status" BO_ 2416444625 "Planned";
BA_ "Variant" BO_ 2416444625 "bmu_qev6";
BA_ "VFrameFormat" BO_ 2416444625 1;
BA_ "GenMsgCycleTime" BO_ 2416445648 3300;
BA_ "SendType" BO_ 2416445648 "Burst";
BA_ "Status" BO_ 2416445648 "Planned";
BA_ "Variant" BO_ 2416445648 "bmu_qev6";
BA_ "VFrameFormat" BO_ 2416445648 1;
BA_ "GenMsgCycleTime" BO_ 2416443616 3300;
BA_ "SendType" BO_ 2416443616 "Burst";
BA_ "Status" BO_ 2416443616 "Planned";
BA_ "Variant" BO_ 2416443616 "bmu_qev6";
BA_ "VFrameFormat" BO_ 2416443616 1;
BA_ "GenMsgCycleTime" BO_ 2416443617 3300;
BA_ "SendType" BO_ 2416443617 "Burst";
BA_ "Status" BO_ 2416443617 "Planned";
BA_ "Variant" BO_ 2416443617 "bmu_qev6";
BA_ "VFrameFormat" BO_ 2416443617 1;
BA_ "GenMsgCycleTime" BO_ 2416443618 3300;
BA_ "SendType" BO_ 2416443618 "Burst";
BA_ "Status" BO_ 2416443618 "Planned";
BA_ "Variant" BO_ 2416443618 "bmu_qev6";
BA_ "VFrameFormat" BO_ 2416443618 1;
BA_ "GenMsgCycleTime" BO_ 2416443619 3300;
BA_ "SendType" BO_ 2416443619 "Burst";
BA_ "Status" BO_ 2416443619 "Planned";
BA_ "Variant" BO_ 2416443619 "bmu_qev6";
BA_ "VFrameFormat" BO_ 2416443619 1;
BA_ "GenMsgCycleTime" BO_ 2416444640 3300;
BA_ "SendType" BO_ 2416444640 "Burst";
BA_ "Status" BO_ 2416444640 "Planned";
BA_ "Variant" BO_ 2416444640 "bmu_qev6";
BA_ "VFrameFormat" BO_ 2416444640 1;
BA_ "GenMsgCycleTime" BO_ 2416444641 3300;
BA_ "SendType" BO_ 2416444641 "Burst";
BA_ "Status" BO_ 2416444641 "Planned";
BA_ "Variant" BO_ 2416444641 "bmu_qev6";
BA_ "VFrameFormat" BO_ 2416444641 1;
BA_ "GenMsgCycleTime" BO_ 2416445664 3300;
BA_ "SendType" BO_ 2416445664 "Burst";
BA_ "Status" BO_ 2416445664 "Planned";
BA_ "Variant" BO_ 2416445664 "bmu_qev6";
BA_ "VFrameFormat" BO_ 2416445664 1;
BA_ "GenMsgCycleTime" BO_ 2416443632 3300;
BA_ "SendType" BO_ 2416443632 "Burst";
BA_ "Status" BO_ 2416443632 "Planned";
BA_ "Variant" BO_ 2416443632 "bmu_qev6";
BA_ "VFrameFormat" BO_ 2416443632 1;
BA_ "GenMsgCycleTime" BO_ 2416443633 3300;
BA_ "SendType" BO_ 2416443633 "Burst";
BA_ "Status" BO_ 2416443633 "Planned";
BA_ "Variant" BO_ 2416443633 "bmu_qev6";
BA_ "VFrameFormat" BO_ 2416443633 1;
BA_ "GenMsgCycleTime" BO_ 2416443634 3300;
BA_ "SendType" BO_ 2416443634 "Burst";
BA_ "Status" BO_ 2416443634 "Planned";
BA_ "Variant" BO_ 2416443634 "bmu_qev6";
BA_ "VFrameFormat" BO_ 2416443634 1;
BA_ "GenMsgCycleTime" BO_ 2416443635 3300;
BA_ "SendType" BO_ 2416443635 "Burst";
BA_ "Status" BO_ 2416443635 "Planned";
BA_ "Variant" BO_ 2416443635 "bmu_qev6";
BA_ "VFrameFormat" BO_ 2416443635 1;
BA_ "GenMsgCycleTime" BO_ 2416444656 3300;
BA_ "SendType" BO_ 2416444656 "Burst";
BA_ "Status" BO_ 2416444656 "Planned";
BA_ "Variant" BO_ 2416444656 "bmu_qev6";
BA_ "VFrameFormat" BO_ 2416444656 1;
BA_ "GenMsgCycleTime" BO_ 2416444657 3300;
BA_ "SendType" BO_ 2416444657 "Burst";
BA_ "Status" BO_ 2416444657 "Planned";
BA_ "Variant" BO_ 2416444657 "bmu_qev6";
BA_ "VFrameFormat" BO_ 2416444657 1;
BA_ "GenMsgCycleTime" BO_ 2416445680 3300;
BA_ "SendType" BO_ 2416445680 "Burst";
BA_ "Status" BO_ 2416445680 "Planned";
BA_ "Variant" BO_ 2416445680 "bmu_qev6";
BA_ "VFrameFormat" BO_ 2416445680 1;
BA_ "GenMsgCycleTime" BO_ 2416443648 3300;
BA_ "SendType" BO_ 2416443648 "Burst";
BA_ "Status" BO_ 2416443648 "Planned";
BA_ "Variant" BO_ 2416443648 "bmu_qev6";
BA_ "VFrameFormat" BO_ 2416443648 1;
BA_ "GenMsgCycleTime" BO_ 2416443649 3300;
BA_ "SendType" BO_ 2416443649 "Burst";
BA_ "Status" BO_ 2416443649 "Planned";
BA_ "Variant" BO_ 2416443649 "bmu_qev6";
BA_ "VFrameFormat" BO_ 2416443649 1;
BA_ "GenMsgCycleTime" BO_ 2416443650 3300;
BA_ "SendType" BO_ 2416443650 "Burst";
BA_ "Status" BO_ 2416443650 "Planned";
BA_ "Variant" BO_ 2416443650 "bmu_qev6";
BA_ "VFrameFormat" BO_ 2416443650 1;
BA_ "GenMsgCycleTime" BO_ 2416443651 3300;
BA_ "SendType" BO_ 2416443651 "Burst";
BA_ "Status" BO_ 2416443651 "Planned";
BA_ "Variant" BO_ 2416443651 "bmu_qev6";
BA_ "VFrameFormat" BO_ 2416443651 1;
BA_ "GenMsgCycleTime" BO_ 2416444672 3300;
BA_ "SendType" BO_ 2416444672 "Burst";
BA_ "Status" BO_ 2416444672 "Planned";
BA_ "Variant" BO_ 2416444672 "bmu_qev6";
BA_ "VFrameFormat" BO_ 2416444672 1;
BA_ "GenMsgCycleTime" BO_ 2416444673 3300;
BA_ "SendType" BO_ 2416444673 "Burst";
BA_ "Status" BO_ 2416444673 "Planned";
BA_ "Variant" BO_ 2416444673 "bmu_qev6";
BA_ "VFrameFormat" BO_ 2416444673 1;
BA_ "GenMsgCycleTime" BO_ 2416445696 3300;
BA_ "SendType" BO_ 2416445696 "Burst";
BA_ "Status" BO_ 2416445696 "Planned";
BA_ "Variant" BO_ 2416445696 "bmu_qev6";
BA_ "VFrameFormat" BO_ 2416445696 1;
BA_ "GenMsgCycleTime" BO_ 2416443664 3300;
BA_ "SendType" BO_ 2416443664 "Burst";
BA_ "Status" BO_ 2416443664 "Planned";
BA_ "Variant" BO_ 2416443664 "bmu_qev6";
BA_ "VFrameFormat" BO_ 2416443664 1;
BA_ "GenMsgCycleTime" BO_ 2416443665 3300;
BA_ "SendType" BO_ 2416443665 "Burst";
BA_ "Status" BO_ 2416443665 "Planned";
BA_ "Variant" BO_ 2416443665 "bmu_qev6";
BA_ "VFrameFormat" BO_ 2416443665 1;
BA_ "GenMsgCycleTime" BO_ 2416443666 3300;
BA_ "SendType" BO_ 2416443666 "Burst";
BA_ "Status" BO_ 2416443666 "Planned";
BA_ "Variant" BO_ 2416443666 "bmu_qev6";
BA_ "VFrameFormat" BO_ 2416443666 1;
BA_ "GenMsgCycleTime" BO_ 2416443667 3300;
BA_ "SendType" BO_ 2416443667 "Burst";
BA_ "Status" BO_ 2416443667 "Planned";
BA_ "Variant" BO_ 2416443667 "bmu_qev6";
BA_ "VFrameFormat" BO_ 2416443667 1;
BA_ "GenMsgCycleTime" BO_ 2416444688 3300;
BA_ "SendType" BO_ 2416444688 "Burst";
BA_ "Status" BO_ 2416444688 "Planned";
BA_ "Variant" BO_ 2416444688 "bmu_qev6";
BA_ "VFrameFormat" BO_ 2416444688 1;
BA_ "GenMsgCycleTime" BO_ 2416444689 3300;
BA_ "SendType" BO_ 2416444689 "Burst";
BA_ "Status" BO_ 2416444689 "Planned";
BA_ "Variant" BO_ 2416444689 "bmu_qev6";
BA_ "VFrameFormat" BO_ 2416444689 1;
BA_ "GenMsgCycleTime" BO_ 2416445712 3300;
BA_ "SendType" BO_ 2416445712 "Burst";
BA_ "Status" BO_ 2416445712 "Planned";
BA_ "Variant" BO_ 2416445712 "bmu_qev6";
BA_ "VFrameFormat" BO_ 2416445712 1;
BA_ "GenMsgCycleTime" BO_ 2416443680 3300;
BA_ "SendType" BO_ 2416443680 "Burst";
BA_ "Status" BO_ 2416443680 "Planned";
BA_ "Variant" BO_ 2416443680 "bmu_qev6";
BA_ "VFrameFormat" BO_ 2416443680 1;
BA_ "GenMsgCycleTime" BO_ 2416443681 3300;
BA_ "SendType" BO_ 2416443681 "Burst";
BA_ "Status" BO_ 2416443681 "Planned";
BA_ "Variant" BO_ 2416443681 "bmu_qev6";
BA_ "VFrameFormat" BO_ 2416443681 1;
BA_ "GenMsgCycleTime" BO_ 2416443682 3300;
BA_ "SendType" BO_ 2416443682 "Burst";
BA_ "Status" BO_ 2416443682 "Planned";
BA_ "Variant" BO_ 2416443682 "bmu_qev6";
BA_ "VFrameFormat" BO_ 2416443682 1;
BA_ "GenMsgCycleTime" BO_ 2416443683 3300;
BA_ "SendType" BO_ 2416443683 "Burst";
BA_ "Status" BO_ 2416443683 "Planned";
BA_ "Variant" BO_ 2416443683 "bmu_qev6";
BA_ "VFrameFormat" BO_ 2416443683 1;
BA_ "GenMsgCycleTime" BO_ 2416444704 3300;
BA_ "SendType" BO_ 2416444704 "Burst";
BA_ "Status" BO_ 2416444704 "Planned";
BA_ "Variant" BO_ 2416444704 "bmu_qev6";
BA_ "VFrameFormat" BO_ 2416444704 1;
BA_ "GenMsgCycleTime" BO_ 2416444705 3300;
BA_ "SendType" BO_ 2416444705 "Burst";
BA_ "Status" BO_ 2416444705 "Planned";
BA_ "Variant" BO_ 2416444705 "bmu_qev6";
BA_ "VFrameFormat" BO_ 2416444705 1;
BA_ "GenMsgCycleTime" BO_ 2416445728 3300;
BA_ "SendType" BO_ 2416445728 "Burst";
BA_ "Status" BO_ 2416445728 "Planned";
BA_ "Variant" BO_ 2416445728 "bmu_qev6";
BA_ "VFrameFormat" BO_ 2416445728 1;
BA_ "GenMsgCycleTime" BO_ 2416443696 3300;
BA_ "SendType" BO_ 2416443696 "Burst";
BA_ "Status" BO_ 2416443696 "Planned";
BA_ "Variant" BO_ 2416443696 "bmu_qev6";
BA_ "VFrameFormat" BO_ 2416443696 1;
BA_ "GenMsgCycleTime" BO_ 2416443697 3300;
BA_ "SendType" BO_ 2416443697 "Burst";
BA_ "Status" BO_ 2416443697 "Planned";
BA_ "Variant" BO_ 2416443697 "bmu_qev6";
BA_ "VFrameFormat" BO_ 2416443697 1;
BA_ "GenMsgCycleTime" BO_ 2416443698 3300;
BA_ "SendType" BO_ 2416443698 "Burst";
BA_ "Status" BO_ 2416443698 "Planned";
BA_ "Variant" BO_ 2416443698 "bmu_qev6";
BA_ "VFrameFormat" BO_ 2416443698 1;
BA_ "GenMsgCycleTime" BO_ 2416443699 3300;
BA_ "SendType" BO_ 2416443699 "Burst";
BA_ "Status" BO_ 2416443699 "Planned";
BA_ "Variant" BO_ 2416443699 "bmu_qev6";
BA_ "VFrameFormat" BO_ 2416443699 1;
BA_ "GenMsgCycleTime" BO_ 2416444720 3300;
BA_ "SendType" BO_ 2416444720 "Burst";
BA_ "Status" BO_ 2416444720 "Planned";
BA_ "Variant" BO_ 2416444720 "bmu_qev6";
BA_ "VFrameFormat" BO_ 2416444720 1;
BA_ "GenMsgCycleTime" BO_ 2416444721 3300;
BA_ "SendType" BO_ 2416444721 "Burst";
BA_ "Status" BO_ 2416444721 "Planned";
BA_ "Variant" BO_ 2416444721 "bmu_qev6";
BA_ "VFrameFormat" BO_ 2416444721 1;
BA_ "GenMsgCycleTime" BO_ 2416445744 3300;
BA_ "SendType" BO_ 2416445744 "Burst";
BA_ "Status" BO_ 2416445744 "Planned";
BA_ "Variant" BO_ 2416445744 "bmu_qev6";
BA_ "VFrameFormat" BO_ 2416445744 1;
BA_ "GenMsgCycleTime" BO_ 2416443712 3300;
BA_ "SendType" BO_ 2416443712 "Burst";
BA_ "Status" BO_ 2416443712 "Planned";
BA_ "Variant" BO_ 2416443712 "bmu_qev6";
BA_ "VFrameFormat" BO_ 2416443712 1;
BA_ "GenMsgCycleTime" BO_ 2416443713 3300;
BA_ "SendType" BO_ 2416443713 "Burst";
BA_ "Status" BO_ 2416443713 "Planned";
BA_ "Variant" BO_ 2416443713 "bmu_qev6";
BA_ "VFrameFormat" BO_ 2416443713 1;
BA_ "GenMsgCycleTime" BO_ 2416443714 3300;
BA_ "SendType" BO_ 2416443714 "Burst";
BA_ "Status" BO_ 2416443714 "Planned";
BA_ "Variant" BO_ 2416443714 "bmu_qev6";
BA_ "VFrameFormat" BO_ 2416443714 1;
BA_ "GenMsgCycleTime" BO_ 2416443715 3300;
BA_ "SendType" BO_ 2416443715 "Burst";
BA_ "Status" BO_ 2416443715 "Planned";
BA_ "Variant" BO_ 2416443715 "bmu_qev6";
BA_ "VFrameFormat" BO_ 2416443715 1;
BA_ "GenMsgCycleTime" BO_ 2416444736 3300;
BA_ "SendType" BO_ 2416444736 "Burst";
BA_ "Status" BO_ 2416444736 "Planned";
BA_ "Variant" BO_ 2416444736 "bmu_qev6";
BA_ "VFrameFormat" BO_ 2416444736 1;
BA_ "GenMsgCycleTime" BO_ 2416444737 3300;
BA_ "SendType" BO_ 2416444737 "Burst";
BA_ "Status" BO_ 2416444737 "Planned";
BA_ "Variant" BO_ 2416444737 "bmu_qev6";
BA_ "VFrameFormat" BO_ 2416444737 1;
BA_ "GenMsgCycleTime" BO_ 2416445760 3300;
BA_ "SendType" BO_ 2416445760 "Burst";
BA_ "Status" BO_ 2416445760 "Planned";
BA_ "Variant" BO_ 2416445760 "bmu_qev6";
BA_ "VFrameFormat" BO_ 2416445760 1;
BA_ "GenMsgCycleTime" BO_ 2416443728 3300;
BA_ "SendType" BO_ 2416443728 "Burst";
BA_ "Status" BO_ 2416443728 "Planned";
BA_ "Variant" BO_ 2416443728 "bmu_qev6";
BA_ "VFrameFormat" BO_ 2416443728 1;
BA_ "GenMsgCycleTime" BO_ 2416443729 3300;
BA_ "SendType" BO_ 2416443729 "Burst";
BA_ "Status" BO_ 2416443729 "Planned";
BA_ "Variant" BO_ 2416443729 "bmu_qev6";
BA_ "VFrameFormat" BO_ 2416443729 1;
BA_ "GenMsgCycleTime" BO_ 2416443730 3300;
BA_ "SendType" BO_ 2416443730 "Burst";
BA_ "Status" BO_ 2416443730 "Planned";
BA_ "Variant" BO_ 2416443730 "bmu_qev6";
BA_ "VFrameFormat" BO_ 2416443730 1;
BA_ "GenMsgCycleTime" BO_ 2416443731 3300;
BA_ "SendType" BO_ 2416443731 "Burst";
BA_ "Status" BO_ 2416443731 "Planned";
BA_ "Variant" BO_ 2416443731 "bmu_qev6";
BA_ "VFrameFormat" BO_ 2416443731 1;
BA_ "GenMsgCycleTime" BO_ 2416444752 3300;
BA_ "SendType" BO_ 2416444752 "Burst";
BA_ "Status" BO_ 2416444752 "Planned";
BA_ "Variant" BO_ 2416444752 "bmu_qev6";
BA_ "VFrameFormat" BO_ 2416444752 1;
BA_ "GenMsgCycleTime" BO_ 2416444753 3300;
BA_ "SendType" BO_ 2416444753 "Burst";
BA_ "Status" BO_ 2416444753 "Planned";
BA_ "Variant" BO_ 2416444753 "bmu_qev6";
BA_ "VFrameFormat" BO_ 2416444753 1;
BA_ "GenMsgCycleTime" BO_ 2416445776 3300;
BA_ "SendType" BO_ 2416445776 "Burst";
BA_ "Status" BO_ 2416445776 "Planned";
BA_ "Variant" BO_ 2416445776 "bmu_qev6";
BA_ "VFrameFormat" BO_ 2416445776 1;
BA_ "GenMsgCycleTime" BO_ 2416443744 3300;
BA_ "SendType" BO_ 2416443744 "Burst";
BA_ "Status" BO_ 2416443744 "Planned";
BA_ "Variant" BO_ 2416443744 "bmu_qev6";
BA_ "VFrameFormat" BO_ 2416443744 1;
BA_ "GenMsgCycleTime" BO_ 2416443745 3300;
BA_ "SendType" BO_ 2416443745 "Burst";
BA_ "Status" BO_ 2416443745 "Planned";
BA_ "Variant" BO_ 2416443745 "bmu_qev6";
BA_ "VFrameFormat" BO_ 2416443745 1;
BA_ "GenMsgCycleTime" BO_ 2416443746 3300;
BA_ "SendType" BO_ 2416443746 "Burst";
BA_ "Status" BO_ 2416443746 "Planned";
BA_ "Variant" BO_ 2416443746 "bmu_qev6";
BA_ "VFrameFormat" BO_ 2416443746 1;
BA_ "GenMsgCycleTime" BO_ 2416443747 3300;
BA_ "SendType" BO_ 2416443747 "Burst";
BA_ "Status" BO_ 2416443747 "Planned";
BA_ "Variant" BO_ 2416443747 "bmu_qev6";
BA_ "VFrameFormat" BO_ 2416443747 1;
BA_ "GenMsgCycleTime" BO_ 2416444768 3300;
BA_ "SendType" BO_ 2416444768 "Burst";
BA_ "Status" BO_ 2416444768 "Planned";
BA_ "Variant" BO_ 2416444768 "bmu_qev6";
BA_ "VFrameFormat" BO_ 2416444768 1;
BA_ "GenMsgCycleTime" BO_ 2416444769 3300;
BA_ "SendType" BO_ 2416444769 "Burst";
BA_ "Status" BO_ 2416444769 "Planned";
BA_ "Variant" BO_ 2416444769 "bmu_qev6";
BA_ "VFrameFormat" BO_ 2416444769 1;
BA_ "GenMsgCycleTime" BO_ 2416445792 3300;
BA_ "SendType" BO_ 2416445792 "Burst";
BA_ "Status" BO_ 2416445792 "Planned";
BA_ "Variant" BO_ 2416445792 "bmu_qev6";
BA_ "VFrameFormat" BO_ 2416445792 1;
BA_ "GenMsgCycleTime" BO_ 2416443760 3300;
BA_ "SendType" BO_ 2416443760 "Burst";
BA_ "Status" BO_ 2416443760 "Planned";
BA_ "Variant" BO_ 2416443760 "bmu_qev6";
BA_ "VFrameFormat" BO_ 2416443760 1;
BA_ "GenMsgCycleTime" BO_ 2416443761 3300;
BA_ "SendType" BO_ 2416443761 "Burst";
BA_ "Status" BO_ 2416443761 "Planned";
BA_ "Variant" BO_ 2416443761 "bmu_qev6";
BA_ "VFrameFormat" BO_ 2416443761 1;
BA_ "GenMsgCycleTime" BO_ 2416443762 3300;
BA_ "SendType" BO_ 2416443762 "Burst";
BA_ "Status" BO_ 2416443762 "Planned";
BA_ "Variant" BO_ 2416443762 "bmu_qev6";
BA_ "VFrameFormat" BO_ 2416443762 1;
BA_ "GenMsgCycleTime" BO_ 2416443763 3300;
BA_ "SendType" BO_ 2416443763 "Burst";
BA_ "Status" BO_ 2416443763 "Planned";
BA_ "Variant" BO_ 2416443763 "bmu_qev6";
BA_ "VFrameFormat" BO_ 2416443763 1;
BA_ "GenMsgCycleTime" BO_ 2416444784 3300;
BA_ "SendType" BO_ 2416444784 "Burst";
BA_ "Status" BO_ 2416444784 "Planned";
BA_ "Variant" BO_ 2416444784 "bmu_qev6";
BA_ "VFrameFormat" BO_ 2416444784 1;
BA_ "GenMsgCycleTime" BO_ 2416444785 3300;
BA_ "SendType" BO_ 2416444785 "Burst";
BA_ "Status" BO_ 2416444785 "Planned";
BA_ "Variant" BO_ 2416444785 "bmu_qev6";
BA_ "VFrameFormat" BO_ 2416444785 1;
BA_ "GenMsgCycleTime" BO_ 2416445808 3300;
BA_ "SendType" BO_ 2416445808 "Burst";
BA_ "Status" BO_ 2416445808 "Planned";
BA_ "Variant" BO_ 2416445808 "bmu_qev6";
BA_ "VFrameFormat" BO_ 2416445808 1;
